VERSION ""

NS_ :

BS_:

BU_: MPAD CVADAS ADCAM ORC EVCU2 EPS ECM CVPAM CADM BSM2 BSM

BO_ 299 ADAS_FD_INFO3: 32 ADCAM
 SG_ ACC_Axle_Torque : 7|16@0+ (2,-65534) [-65534|65536] "Nm"  EVCU2,BSM
 SG_ ACC_Axle_Torque_Enabled : 180|1@0+ (1,0) [0|1] "" BSM
 SG_ MessageCounter_ADAS_FD_INFO3 : 179|4@0+ (1,0) [0|15] "-"  MPAD,BSM
 SG_ CRC_ADAS_FD_INFO3 : 191|8@0+ (1,0) [0|255] "-"  MPAD,BSM
 SG_ ACC_TORSts : 22|1@0+ (1,0) [0|1] "" ADCAM

BO_ 263 PT_SYSTEM_FD_1: 64 EVCU2
 SG_ PowertrainPrplsnActv_PT : 146|1@0+ (1,0) [0|1] "" CVADAS,ADCAM,MPAD,CADM,BSM,EPS
 SG_ GearEngagedForDisplay_PT : 12|5@0+ (1,0) [0|31] "" CVADAS,ADCAM,EPS
 SG_ GearEngaged_PT : 132|4@0+ (1,0) [0|15] "" ADCAM,BSM2,BSM,EPS
 SG_ DriveReady_PT : 166|1@0+ (1,0) [0|1] "" BSM,EPS
 SG_ TargetGear_PT : 55|4@0+ (1,0) [0|15] "" EPS
 SG_ SpeedLimitSts_PT : 140|3@0+ (1,0) [0|7] "" Vector__XXX
 SG_ ShiftLeverPosition_PT : 51|4@0+ (1,0) [0|15] "" CVADAS,ADCAM,CVPAM,BSM,EPS
 SG_ PdlPosActual_PT : 39|8@0+ (0.4,0) [0|102] "%"  CVADAS,ADCAM,MPAD,BSM2,CVPAM,CADM,BSM
 SG_ MessageCounter_PT_SYSTEM_FD_1 : 435|4@0+ (1,0) [0|15] "-"  CVADAS,ADCAM,MPAD,CADM,BSM,EPS,ECM
 SG_ ISASts_PT : 149|1@0+ (1,0) [0|1] "" Vector__XXX
 SG_ GasPedalPositionFailSts_PT : 145|1@0+ (1,0) [0|1] "" ADCAM,MPAD,CADM,BSM
 SG_ GasPedalPosition_PT : 31|8@0+ (0.392,0) [0|99.96] "%"  MPAD,BSM
 SG_ CRC_PT_SYSTEM_FD_1 : 447|8@0+ (1,0) [0|255] "-"  CVADAS,ADCAM,MPAD,CADM,BSM,EPS,ECM
 SG_ RawPVS2_PT : 303|8@0+ (0.019607843,0) [0|4.999999965] "V"  Vector__XXX
 SG_ RawPVS1_PT : 295|8@0+ (0.019607843,0) [0|4.999999965] "V"  Vector__XXX
 SG_ EVCU2_THA_Resp : 220|2@0+ (1,0) [0|3] "" CVADAS
 SG_ EVCU2_TRSC_Resp : 414|2@0+ (1,0) [0|3] "" CVADAS
 SG_ Propulsion_ADAS_Inhibit : 231|1@0+ (1,0) [0|1] "" CVADAS,BSM

BO_ 1580 HYBRID_POWERTRAIN6: 32 EVCU2
 SG_ Motor2_RPM : 23|16@0+ (1,-32768) [-32768|32767] "RPM"  ORC
 SG_ Motor1_RPM : 7|16@0+ (1,-32768) [-32768|32767] "RPM"  ORC

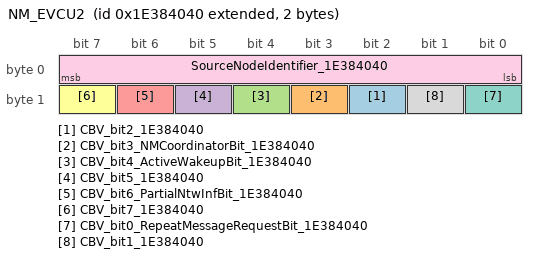
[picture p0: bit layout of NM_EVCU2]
BO_ 2654486592 NM_EVCU2: 2 EVCU2
 SG_ CBV_bit2_1E384040 : 10|1@0+ (1,0) [0|1] "" CVADAS,ADCAM,MPAD,BSM2,CVPAM,CADM,BSM,ORC,EPS,ECM
 SG_ CBV_bit3_NMCoordinatorBit_1E384040 : 11|1@0+ (1,0) [0|1] "" CVADAS,ADCAM,MPAD,BSM2,CVPAM,CADM,BSM,ORC,EPS,ECM
 SG_ CBV_bit4_ActiveWakeupBit_1E384040 : 12|1@0+ (1,0) [0|1] "" CVADAS,ADCAM,MPAD,BSM2,CVPAM,CADM,BSM,ORC,EPS,ECM
 SG_ CBV_bit5_1E384040 : 13|1@0+ (1,0) [0|1] "" CVADAS,ADCAM,MPAD,BSM2,CVPAM,CADM,BSM,ORC,EPS,ECM
 SG_ CBV_bit6_PartialNtwInfBit_1E384040 : 14|1@0+ (1,0) [0|1] "" CVADAS,ADCAM,MPAD,BSM2,CVPAM,CADM,BSM,ORC,EPS,ECM
 SG_ CBV_bit7_1E384040 : 15|1@0+ (1,0) [0|1] "" CVADAS,ADCAM,MPAD,BSM2,CVPAM,CADM,BSM,ORC,EPS,ECM
 SG_ CBV_bit0_RepeatMessageRequestBit_1E384040 : 8|1@0+ (1,0) [0|1] "" CVADAS,ADCAM,MPAD,BSM2,CVPAM,CADM,BSM,ORC,EPS,ECM
 SG_ CBV_bit1_1E384040 : 9|1@0+ (1,0) [0|1] "" CVADAS,ADCAM,MPAD,BSM2,CVPAM,CADM,BSM,ORC,EPS,ECM
 SG_ SourceNodeIdentifier_1E384040 : 7|8@0+ (1,0) [0|255] "-"  CVADAS,ADCAM,MPAD,BSM2,CVPAM,CADM,BSM,ORC,EPS,ECM

BO_ 616 ADAS_FD_HMI_VIP: 32 ADCAM
 SG_ Set_Speed_MPH_VIP : 15|8@0+ (1,0) [0|255] "mph"  MPAD
 SG_ Set_Speed_KPH_VIP : 7|8@0+ (1,0) [0|255] "kph"  MPAD
 SG_ LKA_LEDControlSts_VIP : 57|2@0+ (1,0) [0|3] "No_Unit"  MPAD
 SG_ RR_Chime_RqSts_VIP : 99|1@0+ (1,0) [0|1] "No_Unit"  MPAD
 SG_ PEB_Setting_Avail_VIP : 78|1@0+ (1,0) [0|1] "No_Unit"  MPAD
 SG_ LR_Chime_RqSts_VIP : 100|1@0+ (1,0) [0|1] "No_Unit"  MPAD
 SG_ LKA_FailSts_VIP : 84|1@0+ (1,0) [0|1] "No_Unit"  MPAD
 SG_ LKA_Blind_VIP : 86|1@0+ (1,0) [0|1] "No_Unit"  MPAD
 SG_ ICA_Blind_VIP : 55|1@0+ (1,0) [0|1] "No_Unit"  MPAD
 SG_ FCW_Setting_Avail_VIP : 77|1@0+ (1,0) [0|1] "No_Unit"  MPAD
 SG_ DDD_FailSts_VIP : 96|1@0+ (1,0) [0|1] "No_Unit"  MPAD
 SG_ DDD_DispPopupSts_VIP : 39|2@0+ (1,0) [0|3] "No_Unit"  MPAD
 SG_ BSS_TrailerSts_VIP : 175|3@0+ (1,0) [0|7] "No_Unit"  MPAD
 SG_ BSS_SRV_RQSts_VIP : 88|1@0+ (1,0) [0|1] "No_Unit"  MPAD
 SG_ BSS_DispPopoupSts_VIP : 132|3@0+ (1,0) [0|7] "No_Unit"  MPAD
 SG_ BSS_CFG_STATSts_VIP : 103|2@0+ (1,0) [0|3] "No_Unit"  MPAD
 SG_ BSS_Blind_RQSts_VIP : 101|1@0+ (1,0) [0|1] "No_Unit"  MPAD
 SG_ BlindSpotRightWarn_VIP : 171|2@0+ (1,0) [0|3] "No_Unit"  MPAD
 SG_ BlindSpotLeftWarn_VIP : 105|2@0+ (1,0) [0|3] "No_unit"  MPAD
 SG_ AEB_Limited_VIP : 72|1@0+ (1,0) [0|1] "No_Unit"  MPAD
 SG_ AEB_Limit_Fail_VIP : 74|1@0+ (1,0) [0|1] "No_Unit"  MPAD
 SG_ AEB_FailSts_VIP : 83|1@0+ (1,0) [0|1] "No_Unit"  MPAD
 SG_ AEB_DispPopupSts_VIP : 37|6@0+ (1,0) [0|63] "No_Unit"  MPAD
 SG_ AEB_Blind_VIP : 76|1@0+ (1,0) [0|1] "No_Unit"  MPAD
 SG_ LKA_Status_VIP : 23|1@0+ (1,0) [0|1] "No_Unit"  MPAD
 SG_ Lane_DispPopupSts_VIP : 127|8@0+ (1,0) [0|255] "No_Unit"  MPAD
 SG_ Lane_DisplaySts_Right_LKA_VIP : 60|3@0+ (1,0) [0|7] "No_Unit"  MPAD
 SG_ Lane_DisplaySts_Left_VIP : 71|3@0+ (1,0) [0|7] "No_Unit"  MPAD
 SG_ DisplaySts_Veh_LKA_VIP : 63|3@0+ (1,0) [0|7] "No_Unit"  MPAD
 SG_ MessageCounter_ADAS_FD_HMI_VIP : 179|4@0+ (1,0) [0|15] "No_Unit"  MPAD
 SG_ CRC_ADAS_FD_HMI_VIP : 191|8@0+ (1,0) [0|255] "No_Unit"  MPAD
 SG_ DM_Camera_Block_VIP : 112|1@0+ (1,0) [0|1] "-"  MPAD
 SG_ RRCC_DispPopupSts_VIP : 149|6@0+ (1,0) [0|63] "No_Unit"  MPAD
 SG_ ACC_Set_Speed_Strike_VIP : 92|1@0+ (1,0) [0|1] "No_Unit"  MPAD

BO_ 213 VIP_INFO_FD: 32 MPAD
 SG_ ACCFSafe_D5 : 7|8@0+ (1,0) [0|255] "No_Unit"  ADCAM
 SG_ AEB_Type_Brk_D5 : 11|4@0+ (1,0) [0|15] "No_Unit"  ADCAM
 SG_ DASEngReqPos_D5 : 20|1@0+ (1,0) [0|1] "No_Unit"  ADCAM
 SG_ LKA_LAT_CTRL_ResponseSts_D5 : 13|2@0+ (1,0) [0|3] "No_Unit"  ADCAM
 SG_ RRCC_Cancel_Req_D5 : 15|2@0+ (1,0) [0|3] "No_Unit"  ADCAM
 SG_ MessageCounter_VIP_INFO_FD : 179|4@0+ (1,0) [0|15] "No_Unit"  ADCAM
 SG_ CRC_VIP_INFO_FD : 191|8@0+ (1,0) [0|255] "No_Unit"  ADCAM

BO_ 97 GT_MASTER_FD: 16 MPAD
 SG_ SyncTime : 39|32@0+ (1,0) [0|0] "" CVADAS,BSM2,BSM,ORC
 SG_ OfsTimeSec : 71|32@0+ (1,0) [0|0] "sec"  CVADAS,BSM2,BSM,ORC
 SG_ OfsTimeNSec : 103|32@0+ (1,0) [0|0] "" CVADAS,BSM2,BSM,ORC
 SG_ GTS_Type : 7|8@0+ (1,0) [0|255] "" CVADAS,BSM2,BSM,ORC
 SG_ GTS_SC : 19|4@0+ (1,0) [0|15] "" CVADAS,BSM2,BSM,ORC
 SG_ GTS_D : 23|4@0+ (1,0) [0|16] "" CVADAS,BSM2,BSM,ORC
 SG_ GTS_CRC : 15|8@0+ (1,0) [0|255] "" CVADAS,BSM2,BSM,ORC
 SG_ GTS_Byte3 : 31|8@0+ (1,0) [0|255] "" CVADAS,BSM2,BSM,ORC

BO_ 210 ADAS_FD_INFO3_VIP: 32 ADCAM
 SG_ ACC_Axle_Torque_VIP : 7|16@0+ (2,-65534) [-65534|65536] "Nm"  MPAD

BO_ 209 ADAS_FD_INFO_VIP: 32 ADCAM
 SG_ TorqueOverlaySteeringReq_VIP : 130|11@0+ (0.0048828125,-5) [-5|4.9951171875] "No_Unit"  MPAD
 SG_ SteeringVibration_Type_VIP : 67|4@0+ (1,0) [0|15] "No_Unit"  MPAD
 SG_ SteeringVibration_Rq_VIP : 135|1@0+ (1,0) [0|1] "No_Unit"  MPAD
 SG_ Prefill_Req_VIP : 91|1@0+ (1,0) [0|1] "No_Unit"  MPAD
 SG_ PEB_SystemSts_VIP : 90|1@0+ (1,0) [0|1] "No_Unit"  MPAD
 SG_ Object_Dist_VIP : 127|8@0+ (1,0) [0|255] "m"  MPAD
 SG_ LKA_LAT_CTRL_RequestSts_VIP : 108|2@0+ (1,0) [0|3] "No_Unit"  MPAD
 SG_ LC_Jerk_VIP : 104|1@0+ (1,0) [0|1] "No_Unit"  MPAD
 SG_ Intervention_VIP : 163|12@0+ (0.01,-16) [-16|24.95] "m/s2"  MPAD
 SG_ GrMax_Rq_ACC_VIP : 150|4@0+ (1,0) [0|15] "No_Unit"  MPAD
 SG_ DDD_SystemSts_VIP : 103|1@0+ (1,0) [0|1] "No_Unit"  MPAD
 SG_ DDD_Setting_Avail_VIP : 102|1@0+ (1,0) [0|1] "No_Unit"  MPAD
 SG_ CIPV_Fused_VIP : 101|1@0+ (1,0) [0|1] "No_Unit"  MPAD
 SG_ Brake_Jerk_Req_VIP : 100|1@0+ (1,0) [0|1] "No_Unit"  MPAD
 SG_ AEB_Type_VIP : 167|4@0+ (1,0) [0|15] "No_Unit"  MPAD
 SG_ AEB_Systemsts_VIP : 99|2@0+ (1,0) [0|3] "No_Unit"  MPAD
 SG_ AEB_Sensitivity_Setting_VIP : 1|2@0+ (1,0) [0|3] "No_Unit"  MPAD
 SG_ ACC_Systemsts_VIP : 183|4@0+ (1,0) [0|15] "No_Unit"  MPAD
 SG_ ACC_Engine_Torque_Enabled_VIP : 111|1@0+ (1,0) [0|1] "No_Unit"  MPAD
 SG_ ACC_DsrSpeedKPH_VIP : 119|8@0+ (1,0) [0|255] "km/h"  MPAD
 SG_ MessageCounter_ADAS_FD_INFO_VIP : 179|4@0+ (1,0) [0|15] "No_Unit"  MPAD
 SG_ CRC_ADAS_FD_INFO_VIP : 191|8@0+ (1,0) [0|255] "No_Unit"  MPAD

BO_ 734 ADAS_FD_LANES_2: 64 CVADAS
 SG_ Segment_8_Y2 : 369|10@0+ (0.01,-5) [-5|5.23] "m"  MPAD,CADM
 SG_ Segment_8_Y1 : 201|10@0+ (0.01,-5) [-5|5.23] "m"  MPAD,CADM
 SG_ Segment_8_X2 : 290|11@0+ (0.03,-21) [-21|40.41] "m"  MPAD,CADM
 SG_ Segment_8_X1 : 122|11@0+ (0.03,-21) [-21|40.41] "m"  MPAD,CADM
 SG_ Segment_8_ID : 43|4@0+ (1,0) [0|15] "" MPAD,CADM
 SG_ Segment_8_Confidence : 411|4@0+ (0.1,0) [0|1.5] "" MPAD,CADM
 SG_ Segment_7_Y2 : 363|10@0+ (0.01,-5) [-5|5.23] "m"  MPAD,CADM
 SG_ Segment_7_Y1 : 195|10@0+ (0.01,-5) [-5|5.23] "m"  MPAD,CADM
 SG_ Segment_7_X2 : 285|11@0+ (0.03,-21) [-21|40.41] "m"  MPAD,CADM
 SG_ Segment_7_X1 : 117|11@0+ (0.03,-21) [-21|40.41] "m"  MPAD,CADM
 SG_ Segment_7_ID : 47|4@0+ (1,0) [0|15] "" MPAD,CADM
 SG_ Segment_7_Confidence : 415|4@0+ (0.1,0) [0|1.5] "" MPAD,CADM
 SG_ Segment_6_Y2 : 357|10@0+ (0.01,-5) [-5|5.23] "m"  MPAD,CADM
 SG_ Segment_6_Y1 : 189|10@0+ (0.01,-5) [-5|5.23] "m"  MPAD,CADM
 SG_ Segment_6_X2 : 264|11@0+ (0.03,-21) [-21|40.41] "m"  MPAD,CADM
 SG_ Segment_6_X1 : 96|11@0+ (0.03,-21) [-21|40.41] "m"  MPAD,CADM
 SG_ Segment_6_ID : 35|4@0+ (1,0) [0|15] "" MPAD,CADM
 SG_ Segment_6_Confidence : 403|4@0+ (0.1,0) [0|1.5] "" MPAD,CADM
 SG_ Segment_5_Y2 : 351|10@0+ (0.01,-5) [-5|5.23] "m"  MPAD,CADM
 SG_ Segment_5_Y1 : 183|10@0+ (0.01,-5) [-5|5.23] "m"  MPAD,CADM
 SG_ Segment_5_X2 : 259|11@0+ (0.03,-21) [-21|40.41] "m"  MPAD,CADM
 SG_ Segment_5_X1 : 91|11@0+ (0.03,-21) [-21|40.41] "m"  MPAD,CADM
 SG_ Segment_5_ID : 39|4@0+ (1,0) [0|15] "" MPAD,CADM
 SG_ Segment_5_Confidence : 407|4@0+ (0.1,0) [0|1.5] "" MPAD,CADM
 SG_ Segment_4_Y2 : 329|10@0+ (0.01,-5) [-5|5.23] "m"  MPAD,CADM
 SG_ Segment_4_Y1 : 161|10@0+ (0.01,-5) [-5|5.23] "m"  MPAD,CADM
 SG_ Segment_4_X2 : 254|11@0+ (0.03,-21) [-21|40.41] "m"  MPAD,CADM
 SG_ Segment_4_X1 : 86|11@0+ (0.03,-21) [-21|40.41] "m"  MPAD,CADM
 SG_ Segment_4_ID : 27|4@0+ (1,0) [0|15] "" MPAD,CADM
 SG_ Segment_4_Confidence : 395|4@0+ (0.1,0) [0|1.5] "" MPAD,CADM
 SG_ Segment_3_Y2 : 323|10@0+ (0.01,-5) [-5|5.23] "m"  MPAD,CADM
 SG_ Segment_3_Y1 : 155|10@0+ (0.01,-5) [-5|5.23] "m"  MPAD,CADM
 SG_ Segment_3_X2 : 233|11@0+ (0.03,-21) [-21|40.41] "m"  MPAD,CADM
 SG_ Segment_3_X1 : 65|11@0+ (0.03,-21) [-21|40.41] "m"  MPAD,CADM
 SG_ Segment_3_ID : 31|4@0+ (1,0) [0|15] "" MPAD,CADM
 SG_ Segment_3_Confidence : 399|4@0+ (0.1,0) [0|1.5] "" MPAD,CADM
 SG_ Segment_2_Y2 : 317|10@0+ (0.01,-5) [-5|5.23] "m"  MPAD,CADM
 SG_ Segment_2_Y1 : 149|10@0+ (0.01,-5) [-5|5.23] "m"  MPAD,CADM
 SG_ Segment_2_X2 : 228|11@0+ (0.03,-21) [-21|40.41] "m"  MPAD,CADM
 SG_ Segment_2_X1 : 60|11@0+ (0.03,-21) [-21|40.41] "m"  MPAD,CADM
 SG_ Segment_2_ID : 19|4@0+ (1,0) [0|15] "" MPAD,CADM
 SG_ Segment_2_Confidence : 387|4@0+ (0.1,0) [0|1.5] "" MPAD,CADM
 SG_ Segment_1_Y2 : 311|10@0+ (0.01,-5) [-5|5.23] "m"  MPAD,CADM
 SG_ Segment_1_Y1 : 143|10@0+ (0.01,-5) [-5|5.23] "m"  MPAD,CADM
 SG_ Segment_1_X2 : 223|11@0+ (0.03,-21) [-21|40.41] "m"  MPAD,CADM
 SG_ Segment_1_X1 : 55|11@0+ (0.03,-21) [-21|40.41] "m"  MPAD,CADM
 SG_ Segment_1_ID : 23|4@0+ (1,0) [0|15] "" MPAD,CADM
 SG_ Segment_1_Confidence : 391|4@0+ (0.1,0) [0|1.5] "" MPAD,CADM
 SG_ MessageCounter_ADAS_FD_LANES_2 : 435|4@0+ (1,0) [0|15] "-"  MPAD,CADM
 SG_ MAC_ADAS_FD_LANES_2 : 471|48@0+ (1,0) [0|0] "-"  MPAD,CADM
 SG_ Frame_Index_Lanes_2 : 7|16@0+ (1,0) [0|65535] "" MPAD,CADM
 SG_ CRC_ADAS_FD_LANES_2 : 447|8@0+ (1,0) [0|255] "-"  MPAD,CADM
 SG_ Cntr_ADAS_FD_LANES_2 : 455|16@0+ (1,0) [0|65535] "-"  MPAD,CADM
 SG_ Reserved_for_functional_safety_2DE : 431|12@0+ (0,0) [0|0] "" MPAD,CADM

BO_ 730 ADAS_FD_LANES_1: 64 CVADAS
 SG_ MessageCounter_ADAS_FD_LANES_1 : 435|4@0+ (1,0) [0|15] "-"  MPAD,CADM
 SG_ MAC_ADAS_FD_LANES_1 : 471|48@0+ (1,0) [0|0] "-"  MPAD,CADM
 SG_ Line_4_Type : 179|4@0+ (1,0) [0|15] "" MPAD,CADM
 SG_ Line_4_Start_Range : 294|7@0+ (0.5,-25) [-25|38.5] "m"  MPAD,CADM
 SG_ Line_4_Offset : 209|10@0+ (0.01,-5) [-5|5.23] "m"  MPAD,CADM
 SG_ Line_4_Heading : 249|10@0+ (0.0009765625,-0.357) [-0.357|0.6420234375] "rad"  MPAD,CADM
 SG_ Line_4_End_Range : 326|7@0+ (0.5,-25) [-25|38.5] "m"  MPAD,CADM
 SG_ Line_4_Curvature_Rate : 143|16@0+ (3.7252902985E-09,-0.000122) [-0.000122|0.0001221368997121975] "" MPAD,CADM
 SG_ Line_4_Curvature : 79|16@0+ (9.77E-07,-0.032) [-0.032|0.032027694999999995] "" MPAD,CADM
 SG_ Line_4_Confidence : 163|4@0+ (0.1,0) [0|1.5] "" MPAD,CADM
 SG_ Line_3_Type : 183|4@0+ (1,0) [0|15] "" MPAD,CADM
 SG_ Line_3_Start_Range : 287|7@0+ (0.5,-25) [-25|38.5] "m"  MPAD,CADM
 SG_ Line_3_Offset : 203|10@0+ (0.01,-5) [-5|5.23] "m"  MPAD,CADM
 SG_ Line_3_Heading : 243|10@0+ (0.0009765625,-0.357) [-0.357|0.6420234375] "rad"  MPAD,CADM
 SG_ Line_3_End_Range : 319|7@0+ (0.5,-25) [-25|38.5] "m"  MPAD,CADM
 SG_ Line_3_Curvature_Rate : 127|16@0+ (3.7252902985E-09,-0.000122) [-0.000122|0.0001221368997121975] "" MPAD,CADM
 SG_ Line_3_Curvature : 63|16@0+ (9.77E-07,-0.032) [-0.032|0.032027694999999995] "" MPAD,CADM
 SG_ Line_3_Confidence : 167|4@0+ (0.1,0) [0|1.5] "" MPAD,CADM
 SG_ Line_2_Type : 171|4@0+ (1,0) [0|15] "" MPAD,CADM
 SG_ Line_2_Start_Range : 278|7@0+ (0.5,-25) [-25|38.5] "m"  MPAD,CADM
 SG_ Line_2_Offset : 197|10@0+ (0.01,-5) [-5|5.23] "m"  MPAD,CADM
 SG_ Line_2_Heading : 237|10@0+ (0.0009765625,-0.357) [-0.357|0.6420234375] "rad"  MPAD,CADM
 SG_ Line_2_End_Range : 310|7@0+ (0.5,-25) [-25|38.5] "m"  MPAD,CADM
 SG_ Line_2_Curvature_Rate : 111|16@0+ (3.7252902985E-09,-0.000122) [-0.000122|0.0001221368997121975] "" MPAD,CADM
 SG_ Line_2_Curvature : 47|16@0+ (9.77E-07,-0.032) [-0.032|0.032027694999999995] "" MPAD,CADM
 SG_ Line_2_Confidence : 155|4@0+ (0.1,0) [0|1.5] "" MPAD,CADM
 SG_ Line_1_Type : 175|4@0+ (1,0) [0|15] "" MPAD,CADM
 SG_ Line_1_Start_Range : 271|7@0+ (0.5,-25) [-25|38.5] "m"  MPAD,CADM
 SG_ Line_1_Offset : 191|10@0+ (0.01,-5) [-5|5.23] "m"  MPAD,CADM
 SG_ Line_1_Heading : 231|10@0+ (0.0009765625,-0.357) [-0.357|0.6420234375] "rad"  MPAD,CADM
 SG_ Line_1_End_Range : 303|7@0+ (0.5,-25) [-25|38.5] "m"  MPAD,CADM
 SG_ Line_1_Curvature_Rate : 95|16@0+ (3.7252902985E-09,-0.000122) [-0.000122|0.0001221368997121975] "" MPAD,CADM
 SG_ Line_1_Curvature : 31|16@0+ (9.77E-07,-0.032) [-0.032|0.032027694999999995] "" MPAD,CADM
 SG_ Line_1_Confidence : 159|4@0+ (0.1,0) [0|1.5] "" MPAD,CADM
 SG_ Health_Lane_Detection : 19|2@0+ (1,0) [0|3] "" MPAD,CADM
 SG_ Health_Front_Object_Detection : 17|2@0+ (1,0) [0|3] "" MPAD,CADM
 SG_ Frame_Index_Lanes_1 : 7|16@0+ (1,0) [0|65535] "" MPAD,CADM
 SG_ FOD_Confidence : 335|2@0+ (1,0) [0|3] "" MPAD,CADM
 SG_ CRC_ADAS_FD_LANES_1 : 447|8@0+ (1,0) [0|255] "-"  MPAD,CADM
 SG_ Cntr_ADAS_FD_LANES_1 : 455|16@0+ (1,0) [0|65535] "-"  MPAD,CADM
 SG_ Camera_Status : 23|4@0+ (1,0) [0|15] "" MPAD,CADM
 SG_ Reserved_for_functional_safety_2DA : 431|12@0+ (0,0) [0|0] "" MPAD,CADM

BO_ 265 BRAKE_FD_TMSMP: 64 BSM
 SG_ StbmTimestampSec_BSM_TMSMP : 191|32@0+ (1,0) [0|4294967295] "sec"  MPAD
 SG_ StbmTimestampNSec_BSM_TMSMP : 223|32@0+ (1,0) [0|4294967295] "nsec"  MPAD
 SG_ StbmSyncState_BSM_TMSMP : 255|8@0+ (1,0) [0|255] "No_Unit"  MPAD
 SG_ RHRWheelSpeed_TMSMP : 68|13@0+ (0.0625,0) [0|511.875] "Km/h"  MPAD
 SG_ RHR_WheelSensorFailSts_TMSMP : 103|1@0+ (1,0) [0|1] "-"  MPAD
 SG_ RHR_Spin_TMSMP : 102|2@0+ (1,0) [0|3] "-"  MPAD
 SG_ RHR_FastPulseCounter_TMSMP : 159|8@0+ (1,0) [0|255] "pulse"  MPAD
 SG_ RHFWheelSpeed_TMSMP : 52|13@0+ (0.0625,0) [0|511.875] "Km/h"  MPAD
 SG_ RHF_WheelSensorFailSts_TMSMP : 182|1@0+ (1,0) [0|1] "-"  MPAD
 SG_ RHF_Spin_TMSMP : 7|2@0+ (1,0) [0|3] "-"  MPAD
 SG_ RHF_FastPulseCounter_TMSMP : 175|8@0+ (1,0) [0|255] "pulse"  MPAD
 SG_ LHRWheelSpeed_TMSMP : 4|13@0+ (0.0625,0) [0|511.875] "Km/h"  MPAD
 SG_ LHR_WheelSensorFailSts_TMSMP : 87|1@0+ (1,0) [0|1] "-"  MPAD
 SG_ LHR_Spin_TMSMP : 86|2@0+ (1,0) [0|3] "-"  MPAD
 SG_ LHR_FastPulseCounter_TMSMP : 151|8@0+ (1,0) [0|255] "pulse"  MPAD
 SG_ LHFWheelSpeed_TMSMP : 20|13@0+ (0.0625,0) [0|511.875] "Km/h"  MPAD
 SG_ LHF_WheelSensorFailSts_TMSMP : 181|1@0+ (1,0) [0|1] "-"  MPAD
 SG_ LHF_Spin_TMSMP : 23|2@0+ (1,0) [0|3] "-"  MPAD
 SG_ LHF_FastPulseCounter_TMSMP : 167|8@0+ (1,0) [0|255] "pulse"  MPAD

BO_TX_BU_ 299 : ADCAM,MPAD,CADM;
CM_ SG_ 299 ACC_Axle_Torque "ACC requested Axle Torque";
CM_ SG_ 263 PowertrainPrplsnActv_PT "Powertrain Propulsion System Status";
CM_ SG_ 263 GearEngagedForDisplay_PT "Transmission Gear Engaged signal for the instrument cluster display";
CM_ SG_ 263 GearEngaged_PT "Current engaged gear";
CM_ SG_ 263 DriveReady_PT "Drive Ready allowed status";
CM_ SG_ 1580 Motor2_RPM "Motor 2 speed";
CM_ SG_ 1580 Motor1_RPM "Motor 1 speed";
CM_ SG_ 263 TargetGear_PT "Intended Gear that the transmission will shift to.";
CM_ SG_ 263 SpeedLimitSts_PT "Speed limiter status";
CM_ SG_ 263 ShiftLeverPosition_PT "Shift Lever Position";
CM_ SG_ 263 PdlPosActual_PT "Actual Pedal Position";
CM_ SG_ 263 MessageCounter_PT_SYSTEM_FD_1 "This signal is a counter used for safety checks strategies. This counter is incremented of 1 (one) unit at each frame transmission.";
CM_ SG_ 263 ISASts_PT "Intelligent Speed Assist status";
CM_ SG_ 263 GasPedalPositionFailSts_PT "Gas Pedal Position Failure Status";
CM_ SG_ 263 GasPedalPosition_PT "Gas Pedal Position in percentage";
CM_ SG_ 263 CRC_PT_SYSTEM_FD_1 "CRC according to SAE J1850 standard at each frame transmission.";
CM_ SG_ 616 Set_Speed_MPH_VIP "Speed shown by IPC, which ACC is controlling in MPH";
CM_ SG_ 616 Set_Speed_KPH_VIP "Speed shown by IPC, which ACC is controlling in KPH";
CM_ SG_ 616 LKA_LEDControlSts_VIP "Lane Keep LED Control Status";
CM_ SG_ 97 GTS_Type "Global Time Sync type of frame";
CM_ SG_ 97 GTS_SC "Sequence Counter";
CM_ SG_ 97 GTS_CRC "Global Time Sync CRC";
CM_ SG_ 210 ACC_Axle_Torque_VIP "ACC requested Axle Torque";
CM_ SG_ 299 ACC_Axle_Torque_Enabled "An enable bit that axle torque commands should be followed";
CM_ SG_ 209 TorqueOverlaySteeringReq_VIP "TorqueOverlaySteeringReq";
CM_ SG_ 209 SteeringVibration_Type_VIP "Type of Steering Wheel Vibration Request";
CM_ SG_ 209 SteeringVibration_Rq_VIP "Request to activate Steering Wheel Vibration";
CM_ SG_ 209 Prefill_Req_VIP "Prefill command of Brake System by DASM";
CM_ SG_ 209 PEB_SystemSts_VIP "PEB System Status";
CM_ SG_ 209 Object_Dist_VIP "It indicates the distance to the recognized object";
CM_ SG_ 209 LKA_LAT_CTRL_RequestSts_VIP "LKA_LAT_CTRL_RequestSts";
CM_ SG_ 209 LC_Jerk_VIP "Lane Centering request for brake jerk";
CM_ SG_ 209 Intervention_VIP "Request to set target acceleration/deceleration for any feature";
CM_ SG_ 209 GrMax_Rq_ACC_VIP "Used to request Max Gear from TCM";
CM_ SG_ 209 DDD_SystemSts_VIP "DDD System Status";
CM_ SG_ 209 DDD_Setting_Avail_VIP "DDD_Setting Av Status";
CM_ SG_ 209 CIPV_Fused_VIP "Closest in-path vehicle is fused True = 1";
CM_ SG_ 209 Brake_Jerk_Req_VIP "Request from DASM to perform Jerk Warning";
CM_ SG_ 209 AEB_Type_VIP "AEB Type";
CM_ SG_ 209 AEB_Systemsts_VIP "AEB System Status";
CM_ SG_ 209 AEB_Sensitivity_Setting_VIP "AEB sensitivity status";
CM_ SG_ 209 ACC_Systemsts_VIP "ACC System Status";
CM_ SG_ 209 ACC_Engine_Torque_Enabled_VIP "An enable bit that Torque commands should be followed";
CM_ SG_ 209 ACC_DsrSpeedKPH_VIP "Desired speed in kilometers per hour";
CM_ SG_ 616 RR_Chime_RqSts_VIP "BSM right rear chime on request";
CM_ SG_ 616 PEB_Setting_Avail_VIP "PEB setting availability";
CM_ SG_ 616 LR_Chime_RqSts_VIP "BSM Left rear chime on request";
CM_ SG_ 616 LKA_FailSts_VIP "LKA_FailSts";
CM_ SG_ 616 LKA_Blind_VIP "LKA_Blind";
CM_ SG_ 616 ICA_Blind_VIP "This signal is used to indicate the presence of an occlusion of the ICA feature";
CM_ SG_ 616 FCW_Setting_Avail_VIP "FCW setting availability";
CM_ SG_ 616 DDD_FailSts_VIP "DDD Fail Sts CADM2";
CM_ SG_ 616 DDD_DispPopupSts_VIP "DDD Disp Pop Up";
CM_ SG_ 616 BSS_SRV_RQSts_VIP "BSS service warning request";
CM_ SG_ 616 BSS_CFG_STATSts_VIP "Blind Spot configuration status";
CM_ SG_ 616 BSS_Blind_RQSts_VIP "Sensor blinded request from BSS";
CM_ SG_ 616 BlindSpotRightWarn_VIP "BlindSpotRightWarn";
CM_ SG_ 616 BlindSpotLeftWarn_VIP "BlindSpotLeftWarn";
CM_ SG_ 616 AEB_Limited_VIP "AEB_Limited";
CM_ SG_ 616 AEB_Limit_Fail_VIP "AEB_Limit_Fail";
CM_ SG_ 616 AEB_FailSts_VIP "AEB_FailSts";
CM_ SG_ 616 AEB_DispPopupSts_VIP "AEB Dips Pop Up";
CM_ SG_ 616 AEB_Blind_VIP "AEB_Blind";
CM_ SG_ 299 MessageCounter_ADAS_FD_INFO3 "This signal is a counter used for safety checks strategies. This counter is incremented of 1 (one) unit at each frame transmission.";
CM_ SG_ 299 CRC_ADAS_FD_INFO3 "CRC according to SAE J1850 standard at each frame transmission.";
CM_ SG_ 213 ACCFSafe_D5 "0";
CM_ SG_ 213 AEB_Type_Brk_D5 "AEB type brake signal";
CM_ SG_ 213 DASEngReqPos_D5 "ACC allowed to request engine torque";
CM_ SG_ 213 LKA_LAT_CTRL_ResponseSts_D5 "LKA LAT CTRL Response Sts";
CM_ SG_ 263 RawPVS2_PT "Raw Pedal Voltage - Sensor 2";
CM_ SG_ 263 RawPVS1_PT "Raw Pedal Voltage - Sensor 1";
CM_ SG_ 263 EVCU2_THA_Resp "EVCU2 speed limiting availability response for trailer hitch assist";
CM_ SG_ 734 Segment_8_Y2 "Line segment 8 end point lateral position";
CM_ SG_ 734 Segment_8_Y1 "Line segment 8 start point lateral position";
CM_ SG_ 734 Segment_8_X2 "Line segment 8 end point longitudinal position";
CM_ SG_ 734 Segment_8_X1 "Line segment 8 start point longitudinal position";
CM_ SG_ 734 Segment_8_ID "ID value of line segment 8";
CM_ SG_ 734 Segment_8_Confidence "Line segment 8 confidence";
CM_ SG_ 734 Segment_7_Y2 "Line segment 7 end point lateral position";
CM_ SG_ 734 Segment_7_Y1 "Line segment 7 start point lateral position";
CM_ SG_ 734 Segment_7_X2 "Line segment 7 end point longitudinal position";
CM_ SG_ 734 Segment_7_X1 "Line segment 7 start point longitudinal position";
CM_ SG_ 734 Segment_7_ID "ID value of line segment 7";
CM_ SG_ 734 Segment_7_Confidence "Line segment 7 confidence";
CM_ SG_ 734 Segment_6_Y2 "Line segment 6 end point lateral position";
CM_ SG_ 734 Segment_6_Y1 "Line segment 6 start point lateral position";
CM_ SG_ 734 Segment_6_X2 "Line segment 6 end point longitudinal position";
CM_ SG_ 734 Segment_6_X1 "Line segment 6 start point longitudinal position";
CM_ SG_ 734 Segment_6_ID "ID value of line segment 6";
CM_ SG_ 734 Segment_6_Confidence "Line segment 6 confidence";
CM_ SG_ 734 Segment_5_Y2 "Line segment 5 end point lateral position";
CM_ SG_ 734 Segment_5_Y1 "Line segment 5 start point lateral position";
CM_ SG_ 734 Segment_5_X2 "Line segment 5 end point longitudinal position";
CM_ SG_ 734 Segment_5_X1 "Line segment 5 start point longitudinal position";
CM_ SG_ 734 Segment_5_ID "ID value of line segment 5";
CM_ SG_ 734 Segment_5_Confidence "Line segment 5 confidence";
CM_ SG_ 734 Segment_4_Y2 "Line segment 4 end point lateral position";
CM_ SG_ 734 Segment_4_Y1 "Line segment 4 start point lateral position";
CM_ SG_ 734 Segment_4_X2 "Line segment 4 end point longitudinal position";
CM_ SG_ 734 Segment_4_X1 "Line segment 4 start point longitudinal position";
CM_ SG_ 734 Segment_4_ID "ID value of line segment 4";
CM_ SG_ 734 Segment_4_Confidence "Line segment 4 confidence";
CM_ SG_ 734 Segment_3_Y2 "Line segment 3 end point lateral position";
CM_ SG_ 734 Segment_3_Y1 "Line segment 3 start point lateral position";
CM_ SG_ 734 Segment_3_X2 "Line segment 3 end point longitudinal position";
CM_ SG_ 734 Segment_3_X1 "Line segment 3 start point longitudinal position";
CM_ SG_ 734 Segment_3_ID "ID value of line segment 3";
CM_ SG_ 734 Segment_3_Confidence "Line segment 3 confidence";
CM_ SG_ 734 Segment_2_Y2 "Line segment 2 end point lateral position";
CM_ SG_ 734 Segment_2_Y1 "Line segment 2 start point lateral position";
CM_ SG_ 734 Segment_2_X2 "Line segment 2 end point longitudinal position";
CM_ SG_ 734 Segment_2_X1 "Line segment 2 start point longitudinal position";
CM_ SG_ 734 Segment_2_ID "ID value of line segment 2";
CM_ SG_ 734 Segment_2_Confidence "Line segment 2 confidence";
CM_ SG_ 734 Segment_1_Y2 "Line segment 1 end point lateral position";
CM_ SG_ 734 Segment_1_Y1 "Line segment 1 start point lateral position";
CM_ SG_ 734 Segment_1_X2 "Line segment 1 end point longitudinal position";
CM_ SG_ 734 Segment_1_X1 "Line segment 1 start point longitudinal position";
CM_ SG_ 734 Segment_1_ID "ID value of line segment 1";
CM_ SG_ 734 Segment_1_Confidence "Line segment 1 confidence";
CM_ SG_ 734 MessageCounter_ADAS_FD_LANES_2 "This signal is a counter used for safety checks strategies. This counter is incremented of 1 (one) unit at each frame transmission.";
CM_ SG_ 734 MAC_ADAS_FD_LANES_2 "-";
CM_ SG_ 734 Frame_Index_Lanes_2 "Frame index number for lanes_2 data";
CM_ SG_ 734 CRC_ADAS_FD_LANES_2 "CRC according to SAE J1850 standard at each frame transmission.";
CM_ SG_ 730 MessageCounter_ADAS_FD_LANES_1 "This signal is a counter used for safety checks strategies. This counter is incremented of 1 (one) unit at each frame transmission.";
CM_ SG_ 730 MAC_ADAS_FD_LANES_1 "-";
CM_ SG_ 730 Line_4_Type "Lane marker 4 type";
CM_ SG_ 730 Line_4_Start_Range "Lane marker 4 start range/view range";
CM_ SG_ 730 Line_4_Offset "Lane marker 4 offset distance";
CM_ SG_ 730 Line_4_Heading "Lane marker 4 heading angle (1st order)";
CM_ SG_ 730 Line_4_End_Range "Lane marker 4 end range/view range";
CM_ SG_ 730 Line_4_Curvature_Rate "Lane marker 4 curvature rate (3rd order)";
CM_ SG_ 730 Line_4_Curvature "Lane marker 4 curvature rate (2nd order)";
CM_ SG_ 730 Line_4_Confidence "Lane marker 4 confidence";
CM_ SG_ 730 Line_3_Type "Lane marker 3 type";
CM_ SG_ 730 Line_3_Start_Range "Lane marker 3 start range/view range";
CM_ SG_ 730 Line_3_Offset "Lane marker 3 offset distance";
CM_ SG_ 730 Line_3_Heading "Lane marker 3 heading angle (1st order)";
CM_ SG_ 730 Line_3_End_Range "Lane marker 3 end range/view range";
CM_ SG_ 730 Line_3_Curvature_Rate "Lane marker 3 curvature rate (3rd order)";
CM_ SG_ 730 Line_3_Curvature "Lane marker 3 curvature rate (2nd order)";
CM_ SG_ 730 Line_3_Confidence "Lane marker 3 confidence";
CM_ SG_ 730 Line_2_Type "Lane marker 2 type";
CM_ SG_ 730 Line_2_Start_Range "Lane marker 2 start range/view range";
CM_ SG_ 730 Line_2_Offset "Lane marker 2 offset distance";
CM_ SG_ 730 Line_2_Heading "Lane marker 2 heading angle (1st order)";
CM_ SG_ 730 Line_2_End_Range "Lane marker 2 end range/view range";
CM_ SG_ 730 Line_2_Curvature_Rate "Lane marker 2 curvature rate (3rd order)";
CM_ SG_ 730 Line_2_Curvature "Lane marker 2 curvature rate (2nd order)";
CM_ SG_ 730 Line_2_Confidence "Lane marker 2 confidence";
CM_ SG_ 730 Line_1_Type "Lane marker 1 type";
CM_ SG_ 730 Line_1_Start_Range "Lane marker 1 start range/view range";
CM_ SG_ 730 Line_1_Offset "Lane marker 1 offset distance";
CM_ SG_ 730 Line_1_Heading "Lane marker 1 heading angle (1st order)";
CM_ SG_ 730 Line_1_End_Range "Lane marker 1 end range/view range";
CM_ SG_ 730 Line_1_Curvature_Rate "Lane marker 1 curvature rate (3rd order)";
CM_ SG_ 730 Line_1_Curvature "Lane marker 1 curvature rate (2nd order)";
CM_ SG_ 730 Line_1_Confidence "Lane marker 1 confidence";
CM_ SG_ 730 Health_Lane_Detection "Health of the Lane Marker Detection system";
CM_ SG_ 730 Health_Front_Object_Detection "Health of the Front Object Detection system";
CM_ SG_ 730 Frame_Index_Lanes_1 "Frame index number for lanes_1 data";
CM_ SG_ 730 FOD_Confidence "Front Object Detection Confidence";
CM_ SG_ 730 CRC_ADAS_FD_LANES_1 "CRC according to SAE J1850 standard at each frame transmission.";
CM_ SG_ 730 Camera_Status "List of which cameras are active";
CM_ SG_ 616 LKA_Status_VIP "None";
CM_ SG_ 616 Lane_DispPopupSts_VIP "Lane Management Pop-up Messages.TEXT MSG n corresponds to a raw value of 'n'";
CM_ SG_ 616 Lane_DisplaySts_Right_LKA_VIP "Lane Display Status Right";
CM_ SG_ 616 Lane_DisplaySts_Left_VIP "Lane Display Status Left";
CM_ SG_ 616 DisplaySts_Veh_LKA_VIP "Display Status Veh";
CM_ SG_ 213 MessageCounter_VIP_INFO_FD "This signal is a counter used for safety checks strategies. This counter is incremented of 1 (one) unit at each frame transmission.";
CM_ SG_ 213 CRC_VIP_INFO_FD "CRC according to SAE J1850 standard at each frame transmission.";
CM_ SG_ 265 StbmTimestampSec_BSM_TMSMP "Timestamp in seconds from the BSM Stbm, [0 - 4294967294].";
CM_ SG_ 265 StbmTimestampNSec_BSM_TMSMP "Timestamp in nanoseconds from the BSM Stbm, [0 - 999999999].";
CM_ SG_ 265 StbmSyncState_BSM_TMSMP "Sync status of the BSM Stbm";
CM_ SG_ 265 RHRWheelSpeed_TMSMP "This is the value of the right rear wheel speed";
CM_ SG_ 265 RHR_WheelSensorFailSts_TMSMP "This signal indicates the fail status of RHR sensor";
CM_ SG_ 265 RHR_Spin_TMSMP "This signal indicates the right hand rear wheel status";
CM_ SG_ 265 RHR_FastPulseCounter_TMSMP "This signal is the right rear wheel pulse counter.";
CM_ SG_ 265 RHFWheelSpeed_TMSMP "This is the value of the right front wheel speed";
CM_ SG_ 265 RHF_WheelSensorFailSts_TMSMP "This signal indicates the fail status of RHF sensor";
CM_ SG_ 265 RHF_Spin_TMSMP "This signal indicates the right hand front wheel status";
CM_ SG_ 265 RHF_FastPulseCounter_TMSMP "This signal is the right front wheel pulse counter.";
CM_ SG_ 265 LHRWheelSpeed_TMSMP "This is the value of the left rear wheel speed";
CM_ SG_ 265 LHR_WheelSensorFailSts_TMSMP "This signal indicates the fail status of LHR sensor";
CM_ SG_ 265 LHR_Spin_TMSMP "This signal indicates the left hand rear wheel status";
CM_ SG_ 265 LHR_FastPulseCounter_TMSMP "This signal is the left rear wheel pulse counter.";
CM_ SG_ 265 LHFWheelSpeed_TMSMP "This is the value of the left front wheel speed";
CM_ SG_ 265 LHF_WheelSensorFailSts_TMSMP "This signal indicates the fail status of LHF sensor";
CM_ SG_ 265 LHF_Spin_TMSMP "This signal indicates the left hand front wheel status";
CM_ SG_ 265 LHF_FastPulseCounter_TMSMP "This signal is the left front wheel pulse counter.";
CM_ SG_ 209 MessageCounter_ADAS_FD_INFO_VIP "This signal is a counter used for safety checks strategies. This counter is incremented of 1 (one) unit at each frame transmission.";
CM_ SG_ 209 CRC_ADAS_FD_INFO_VIP "CRC according to SAE J1850 standard at each frame transmission.";
CM_ SG_ 616 MessageCounter_ADAS_FD_HMI_VIP "This signal is a counter used for safety checks strategies. This counter is incremented of 1 (one) unit at each frame transmission.";
CM_ SG_ 616 CRC_ADAS_FD_HMI_VIP "CRC according to SAE J1850 standard at each frame transmission.";
CM_ SG_ 263 EVCU2_TRSC_Resp "EVCU2 break activation response";
CM_ SG_ 263 Propulsion_ADAS_Inhibit "EVCU2's ability to accept external gear shift requests";
CM_ SG_ 616 DM_Camera_Block_VIP "Driver Camera is blocked or obstructed";
CM_ SG_ 299 ACC_TORSts "Take Over Request status";
CM_ SG_ 616 RRCC_DispPopupSts_VIP "RRCC_DispPopupSts";
CM_ SG_ 616 ACC_Set_Speed_Strike_VIP "ACC Set Speed Strike";
BA_DEF_ SG_ "GenSigTimeoutTime_MPAD" INT 0 65535;
BA_DEF_ SG_ "GenSigTimeoutTime_ADCAM" INT 0 65535;
BA_DEF_ SG_ "GenSigTimeoutTime_CVADAS" INT 0 65535;
BA_DEF_ SG_ "GenSigTimeoutTime_VDCM" INT 0 65535;
BA_DEF_ SG_ "GenSigStartValue" INT 0 2147483647;
BA_DEF_ SG_ "GenSigInactiveValue" INT 0 2147483647;
BA_DEF_ SG_ "GenSigSendType" ENUM "NotUsed","OnWrite","OnWriteWithRepetition","OnChange","OnChangeWithRepetition","IfActive","IfActiveWithRepetition","NoSigSendType";
BA_DEF_ SG_ "SystemSignalLongSymbol" STRING ;
BA_DEF_ SG_ "GenSigTimeoutTime_BSM" INT 0 65535;
BA_DEF_ SG_ "GenSigTimeoutTime_BSM2" INT 0 65535;
BA_DEF_ SG_ "GenSigTimeoutTime_CADM" INT 0 65535;
BA_DEF_ SG_ "GenSigTimeoutTime_CVPAM" INT 0 65535;
BA_DEF_ SG_ "GenSigTimeoutTime_ECM" INT 0 65535;
BA_DEF_ SG_ "GenSigTimeoutTime_EPS" INT 0 65535;
BA_DEF_ SG_ "GenSigTimeoutTime_EVCU2" INT 0 65535;
BA_DEF_ SG_ "GenSigTimeoutTime_ORC" INT 0 65535;
BA_DEF_ BO_ "DiagRequest" ENUM "No","Yes";
BA_DEF_ BO_ "Type" ENUM "P","C","PE","COC","PE_Cntrl","E","E_Cntrl","OC","S","BAF","DC","EM","MM","ISO-TP","-";
BA_DEF_ BO_ "DiagResponse" ENUM "No","Yes";
BA_DEF_ BO_ "NmMessage" ENUM "No","Yes";
BA_DEF_ BO_ "GenMsgSendType" ENUM "Cyclic","NotUsed","NotUsed","NotUsed","NotUsed","NotUsed","NotUsed","NotUsed","NoMsgSendType";
BA_DEF_ BO_ "GenMsgNrOfRepetition" INT 0 255;
BA_DEF_ BO_ "GenMsgILSupport" ENUM "No","Yes";
BA_DEF_ BO_ "GenMsgStartDelayTime" INT 0 65535;
BA_DEF_ BO_ "GenMsgCycleTimeFast" INT 0 65535;
BA_DEF_ BO_ "GenMsgCycleTime" INT 0 65535;
BA_DEF_ BO_ "GenMsgDelayTime" INT 0 65535;
BA_DEF_ BO_ "NmAsrMessage" ENUM "No","Yes";
BA_DEF_ BO_ "DiagState" ENUM "No","Yes";
BA_DEF_ BO_ "DiagConnection" HEX 0 65535;
BA_DEF_ BO_ "VFrameFormat" ENUM "StandardCAN","ExtendedCAN","reserved","reserved","reserved","reserved","reserved","reserved","reserved","reserved","reserved","reserved","reserved","reserved","StandardCAN_FD","ExtendedCAN_FD";
BA_DEF_ BO_ "CANFD_BRS" ENUM "0","1";
BA_DEF_DEF_ "GenSigTimeoutTime_MPAD" 2500;
BA_DEF_DEF_ "GenSigTimeoutTime_ADCAM" 2500;
BA_DEF_DEF_ "GenSigTimeoutTime_CVADAS" 2500;
BA_DEF_DEF_ "GenSigTimeoutTime_VDCM" 2500;
BA_DEF_DEF_ "GenSigStartValue" 0;
BA_DEF_DEF_ "GenSigInactiveValue" 0;
BA_DEF_DEF_ "GenSigSendType" "NoSigSendType";
BA_DEF_DEF_ "SystemSignalLongSymbol" "";
BA_DEF_DEF_ "GenSigTimeoutTime_BSM" 2500;
BA_DEF_DEF_ "GenSigTimeoutTime_BSM2" 2500;
BA_DEF_DEF_ "GenSigTimeoutTime_CADM" 2500;
BA_DEF_DEF_ "GenSigTimeoutTime_CVPAM" 2500;
BA_DEF_DEF_ "GenSigTimeoutTime_ECM" 2500;
BA_DEF_DEF_ "GenSigTimeoutTime_EPS" 2500;
BA_DEF_DEF_ "GenSigTimeoutTime_EVCU2" 2500;
BA_DEF_DEF_ "GenSigTimeoutTime_ORC" 2500;
BA_DEF_DEF_ "DiagRequest" "No";
BA_DEF_DEF_ "Type" "-";
BA_DEF_DEF_ "DiagResponse" "No";
BA_DEF_DEF_ "NmMessage" "No";
BA_DEF_DEF_ "GenMsgSendType" "NoMsgSendType";
BA_DEF_DEF_ "GenMsgNrOfRepetition" 0;
BA_DEF_DEF_ "GenMsgILSupport" "No";
BA_DEF_DEF_ "GenMsgStartDelayTime" 0;
BA_DEF_DEF_ "GenMsgCycleTimeFast" 0;
BA_DEF_DEF_ "GenMsgCycleTime" 0;
BA_DEF_DEF_ "GenMsgDelayTime" 0;
BA_DEF_DEF_ "NmAsrMessage" "No";
BA_DEF_DEF_ "DiagState" "No";
BA_DEF_DEF_ "DiagConnection" 0;
BA_DEF_DEF_ "VFrameFormat" "StandardCAN_FD";
BA_DEF_DEF_ "CANFD_BRS" "0";
BA_ "Type" BO_ 299 1;
BA_ "GenMsgSendType" BO_ 299 0;
BA_ "GenMsgILSupport" BO_ 299 1;
BA_ "GenMsgCycleTime" BO_ 299 10;
BA_ "CANFD_BRS" BO_ 299 1;
BA_ "Type" BO_ 263 1;
BA_ "GenMsgSendType" BO_ 263 0;
BA_ "GenMsgILSupport" BO_ 263 1;
BA_ "GenMsgCycleTime" BO_ 263 10;
BA_ "CANFD_BRS" BO_ 263 1;
BA_ "Type" BO_ 1580 1;
BA_ "GenMsgSendType" BO_ 1580 0;
BA_ "GenMsgILSupport" BO_ 1580 1;
BA_ "GenMsgCycleTime" BO_ 1580 500;
BA_ "CANFD_BRS" BO_ 1580 1;
BA_ "Type" BO_ 2654486592 8;
BA_ "NmMessage" BO_ 2654486592 1;
BA_ "NmAsrMessage" BO_ 2654486592 1;
BA_ "VFrameFormat" BO_ 2654486592 15;
BA_ "CANFD_BRS" BO_ 2654486592 1;
BA_ "Type" BO_ 616 3;
BA_ "GenMsgSendType" BO_ 616 0;
BA_ "GenMsgILSupport" BO_ 616 1;
BA_ "GenMsgCycleTime" BO_ 616 100;
BA_ "GenMsgDelayTime" BO_ 616 20;
BA_ "CANFD_BRS" BO_ 616 1;
BA_ "Type" BO_ 213 1;
BA_ "GenMsgSendType" BO_ 213 0;
BA_ "GenMsgILSupport" BO_ 213 1;
BA_ "GenMsgCycleTime" BO_ 213 10;
BA_ "CANFD_BRS" BO_ 213 1;
BA_ "Type" BO_ 97 8;
BA_ "CANFD_BRS" BO_ 97 1;
BA_ "Type" BO_ 210 1;
BA_ "GenMsgSendType" BO_ 210 0;
BA_ "GenMsgILSupport" BO_ 210 1;
BA_ "GenMsgCycleTime" BO_ 210 10;
BA_ "CANFD_BRS" BO_ 210 1;
BA_ "Type" BO_ 209 1;
BA_ "GenMsgSendType" BO_ 209 0;
BA_ "GenMsgILSupport" BO_ 209 1;
BA_ "GenMsgCycleTime" BO_ 209 10;
BA_ "CANFD_BRS" BO_ 209 1;
BA_ "Type" BO_ 734 1;
BA_ "GenMsgSendType" BO_ 734 0;
BA_ "GenMsgILSupport" BO_ 734 1;
BA_ "GenMsgCycleTime" BO_ 734 40;
BA_ "CANFD_BRS" BO_ 734 1;
BA_ "Type" BO_ 730 1;
BA_ "GenMsgSendType" BO_ 730 0;
BA_ "GenMsgILSupport" BO_ 730 1;
BA_ "GenMsgCycleTime" BO_ 730 40;
BA_ "CANFD_BRS" BO_ 730 1;
BA_ "Type" BO_ 265 1;
BA_ "GenMsgSendType" BO_ 265 0;
BA_ "GenMsgILSupport" BO_ 265 1;
BA_ "GenMsgCycleTime" BO_ 265 10;
BA_ "CANFD_BRS" BO_ 265 1;
BA_ "GenSigTimeoutTime_ADCAM" SG_ 734 Reserved_for_functional_safety_2DE 0;
BA_ "GenSigTimeoutTime_CVADAS" SG_ 734 Reserved_for_functional_safety_2DE 0;
BA_ "GenSigTimeoutTime_BSM" SG_ 734 Reserved_for_functional_safety_2DE 0;
BA_ "GenSigTimeoutTime_BSM2" SG_ 734 Reserved_for_functional_safety_2DE 0;
BA_ "GenSigTimeoutTime_ECM" SG_ 734 Reserved_for_functional_safety_2DE 0;
BA_ "GenSigTimeoutTime_EPS" SG_ 734 Reserved_for_functional_safety_2DE 0;
BA_ "GenSigTimeoutTime_EVCU2" SG_ 734 Reserved_for_functional_safety_2DE 0;
BA_ "GenSigTimeoutTime_ORC" SG_ 734 Reserved_for_functional_safety_2DE 0;
BA_ "GenSigTimeoutTime_ADCAM" SG_ 734 Segment_4_Y2 0;
BA_ "GenSigTimeoutTime_CVADAS" SG_ 734 Segment_4_Y2 0;
BA_ "GenSigTimeoutTime_BSM" SG_ 734 Segment_4_Y2 0;
BA_ "GenSigTimeoutTime_BSM2" SG_ 734 Segment_4_Y2 0;
BA_ "GenSigTimeoutTime_ECM" SG_ 734 Segment_4_Y2 0;
BA_ "GenSigTimeoutTime_EPS" SG_ 734 Segment_4_Y2 0;
BA_ "GenSigTimeoutTime_EVCU2" SG_ 734 Segment_4_Y2 0;
BA_ "GenSigTimeoutTime_ORC" SG_ 734 Segment_4_Y2 0;
BA_ "GenSigTimeoutTime_ADCAM" SG_ 734 Segment_4_Y1 0;
BA_ "GenSigTimeoutTime_CVADAS" SG_ 734 Segment_4_Y1 0;
BA_ "GenSigTimeoutTime_BSM" SG_ 734 Segment_4_Y1 0;
BA_ "GenSigTimeoutTime_BSM2" SG_ 734 Segment_4_Y1 0;
BA_ "GenSigTimeoutTime_ECM" SG_ 734 Segment_4_Y1 0;
BA_ "GenSigTimeoutTime_EPS" SG_ 734 Segment_4_Y1 0;
BA_ "GenSigTimeoutTime_EVCU2" SG_ 734 Segment_4_Y1 0;
BA_ "GenSigTimeoutTime_ORC" SG_ 734 Segment_4_Y1 0;
BA_ "GenSigTimeoutTime_ORC" SG_ 734 Segment_4_X2 0;
BA_ "GenSigTimeoutTime_ADCAM" SG_ 734 Segment_3_Y2 0;
BA_ "GenSigTimeoutTime_CVADAS" SG_ 734 Segment_3_Y2 0;
BA_ "GenSigTimeoutTime_BSM" SG_ 734 Segment_3_Y2 0;
BA_ "GenSigTimeoutTime_BSM2" SG_ 734 Segment_3_Y2 0;
BA_ "GenSigTimeoutTime_ECM" SG_ 734 Segment_3_Y2 0;
BA_ "GenSigTimeoutTime_EPS" SG_ 734 Segment_3_Y2 0;
BA_ "GenSigTimeoutTime_EVCU2" SG_ 734 Segment_3_Y2 0;
BA_ "GenSigTimeoutTime_ORC" SG_ 734 Segment_3_Y2 0;
BA_ "GenSigTimeoutTime_ADCAM" SG_ 734 Segment_3_Y1 0;
BA_ "GenSigTimeoutTime_CVADAS" SG_ 734 Segment_3_Y1 0;
BA_ "GenSigTimeoutTime_BSM" SG_ 734 Segment_3_Y1 0;
BA_ "GenSigTimeoutTime_BSM2" SG_ 734 Segment_3_Y1 0;
BA_ "GenSigTimeoutTime_ECM" SG_ 734 Segment_3_Y1 0;
BA_ "GenSigTimeoutTime_EPS" SG_ 734 Segment_3_Y1 0;
BA_ "GenSigTimeoutTime_EVCU2" SG_ 734 Segment_3_Y1 0;
BA_ "GenSigTimeoutTime_ORC" SG_ 734 Segment_3_Y1 0;
BA_ "GenSigTimeoutTime_ADCAM" SG_ 734 Segment_3_X2 0;
BA_ "GenSigTimeoutTime_CVADAS" SG_ 734 Segment_3_X2 0;
BA_ "GenSigTimeoutTime_BSM" SG_ 734 Segment_3_X2 0;
BA_ "GenSigTimeoutTime_BSM2" SG_ 734 Segment_3_X2 0;
BA_ "GenSigTimeoutTime_ECM" SG_ 734 Segment_3_X2 0;
BA_ "GenSigTimeoutTime_EPS" SG_ 734 Segment_3_X2 0;
BA_ "GenSigTimeoutTime_EVCU2" SG_ 734 Segment_3_X2 0;
BA_ "GenSigTimeoutTime_ORC" SG_ 734 Segment_3_X2 0;
BA_ "GenSigTimeoutTime_ADCAM" SG_ 734 Segment_3_X1 0;
BA_ "GenSigTimeoutTime_CVADAS" SG_ 734 Segment_3_X1 0;
BA_ "GenSigTimeoutTime_BSM" SG_ 734 Segment_3_X1 0;
BA_ "GenSigTimeoutTime_BSM2" SG_ 734 Segment_3_X1 0;
BA_ "GenSigTimeoutTime_ECM" SG_ 734 Segment_3_X1 0;
BA_ "GenSigTimeoutTime_EPS" SG_ 734 Segment_3_X1 0;
BA_ "GenSigTimeoutTime_EVCU2" SG_ 734 Segment_3_X1 0;
BA_ "GenSigTimeoutTime_ORC" SG_ 734 Segment_3_X1 0;
BA_ "GenSigTimeoutTime_ADCAM" SG_ 734 Segment_3_ID 0;
BA_ "GenSigTimeoutTime_CVADAS" SG_ 734 Segment_3_ID 0;
BA_ "GenSigTimeoutTime_BSM" SG_ 734 Segment_3_ID 0;
BA_ "GenSigTimeoutTime_BSM2" SG_ 734 Segment_3_ID 0;
BA_ "GenSigTimeoutTime_ECM" SG_ 734 Segment_3_ID 0;
BA_ "GenSigTimeoutTime_EPS" SG_ 734 Segment_3_ID 0;
BA_ "GenSigTimeoutTime_EVCU2" SG_ 734 Segment_3_ID 0;
BA_ "GenSigTimeoutTime_ORC" SG_ 734 Segment_3_ID 0;
BA_ "GenSigTimeoutTime_ADCAM" SG_ 734 Segment_3_Confidence 0;
BA_ "GenSigTimeoutTime_CVADAS" SG_ 734 Segment_3_Confidence 0;
BA_ "GenSigTimeoutTime_BSM" SG_ 734 Segment_3_Confidence 0;
BA_ "GenSigTimeoutTime_BSM2" SG_ 734 Segment_3_Confidence 0;
BA_ "GenSigTimeoutTime_ECM" SG_ 734 Segment_3_Confidence 0;
BA_ "GenSigTimeoutTime_EPS" SG_ 734 Segment_3_Confidence 0;
BA_ "GenSigTimeoutTime_EVCU2" SG_ 734 Segment_3_Confidence 0;
BA_ "GenSigTimeoutTime_ORC" SG_ 734 Segment_3_Confidence 0;
BA_ "GenSigTimeoutTime_ADCAM" SG_ 734 Segment_2_Y2 0;
BA_ "GenSigTimeoutTime_CVADAS" SG_ 734 Segment_2_Y2 0;
BA_ "GenSigTimeoutTime_BSM" SG_ 734 Segment_2_Y2 0;
BA_ "GenSigTimeoutTime_BSM2" SG_ 734 Segment_2_Y2 0;
BA_ "GenSigTimeoutTime_ECM" SG_ 734 Segment_2_Y2 0;
BA_ "GenSigTimeoutTime_EPS" SG_ 734 Segment_2_Y2 0;
BA_ "GenSigTimeoutTime_EVCU2" SG_ 734 Segment_2_Y2 0;
BA_ "GenSigTimeoutTime_ORC" SG_ 734 Segment_2_Y2 0;
BA_ "GenSigTimeoutTime_ADCAM" SG_ 734 Segment_2_Y1 0;
BA_ "GenSigTimeoutTime_CVADAS" SG_ 734 Segment_2_Y1 0;
BA_ "GenSigTimeoutTime_BSM" SG_ 734 Segment_2_Y1 0;
BA_ "GenSigTimeoutTime_BSM2" SG_ 734 Segment_2_Y1 0;
BA_ "GenSigTimeoutTime_ECM" SG_ 734 Segment_2_Y1 0;
BA_ "GenSigTimeoutTime_EPS" SG_ 734 Segment_2_Y1 0;
BA_ "GenSigTimeoutTime_EVCU2" SG_ 734 Segment_2_Y1 0;
BA_ "GenSigTimeoutTime_ORC" SG_ 734 Segment_2_Y1 0;
BA_ "GenSigTimeoutTime_ADCAM" SG_ 734 Segment_2_X2 0;
BA_ "GenSigTimeoutTime_CVADAS" SG_ 734 Segment_2_X2 0;
BA_ "GenSigTimeoutTime_BSM" SG_ 734 Segment_2_X2 0;
BA_ "GenSigTimeoutTime_BSM2" SG_ 734 Segment_2_X2 0;
BA_ "GenSigTimeoutTime_ECM" SG_ 734 Segment_2_X2 0;
BA_ "GenSigTimeoutTime_EPS" SG_ 734 Segment_2_X2 0;
BA_ "GenSigTimeoutTime_EVCU2" SG_ 734 Segment_2_X2 0;
BA_ "GenSigTimeoutTime_ORC" SG_ 734 Segment_2_X2 0;
BA_ "GenSigTimeoutTime_ADCAM" SG_ 734 Segment_2_X1 0;
BA_ "GenSigTimeoutTime_CVADAS" SG_ 734 Segment_2_X1 0;
BA_ "GenSigTimeoutTime_BSM" SG_ 734 Segment_2_X1 0;
BA_ "GenSigTimeoutTime_BSM2" SG_ 734 Segment_2_X1 0;
BA_ "GenSigTimeoutTime_ECM" SG_ 734 Segment_2_X1 0;
BA_ "GenSigTimeoutTime_EPS" SG_ 734 Segment_2_X1 0;
BA_ "GenSigTimeoutTime_EVCU2" SG_ 734 Segment_2_X1 0;
BA_ "GenSigTimeoutTime_ORC" SG_ 734 Segment_2_X1 0;
BA_ "GenSigTimeoutTime_ADCAM" SG_ 734 Segment_2_ID 0;
BA_ "GenSigTimeoutTime_CVADAS" SG_ 734 Segment_2_ID 0;
BA_ "GenSigTimeoutTime_BSM" SG_ 734 Segment_2_ID 0;
BA_ "GenSigTimeoutTime_BSM2" SG_ 734 Segment_2_ID 0;
BA_ "GenSigTimeoutTime_ECM" SG_ 734 Segment_2_ID 0;
BA_ "GenSigTimeoutTime_EPS" SG_ 734 Segment_2_ID 0;
BA_ "GenSigTimeoutTime_EVCU2" SG_ 734 Segment_2_ID 0;
BA_ "GenSigTimeoutTime_ORC" SG_ 734 Segment_2_ID 0;
BA_ "GenSigTimeoutTime_ADCAM" SG_ 734 Segment_2_Confidence 0;
BA_ "GenSigTimeoutTime_CVADAS" SG_ 734 Segment_2_Confidence 0;
BA_ "GenSigTimeoutTime_BSM" SG_ 734 Segment_2_Confidence 0;
BA_ "GenSigTimeoutTime_BSM2" SG_ 734 Segment_2_Confidence 0;
BA_ "GenSigTimeoutTime_ECM" SG_ 734 Segment_2_Confidence 0;
BA_ "GenSigTimeoutTime_EPS" SG_ 734 Segment_2_Confidence 0;
BA_ "GenSigTimeoutTime_EVCU2" SG_ 734 Segment_2_Confidence 0;
BA_ "GenSigTimeoutTime_ORC" SG_ 734 Segment_2_Confidence 0;
BA_ "GenSigTimeoutTime_ADCAM" SG_ 734 Segment_1_Y2 0;
BA_ "GenSigTimeoutTime_CVADAS" SG_ 734 Segment_1_Y2 0;
BA_ "GenSigTimeoutTime_BSM" SG_ 734 Segment_1_Y2 0;
BA_ "GenSigTimeoutTime_BSM2" SG_ 734 Segment_1_Y2 0;
BA_ "GenSigTimeoutTime_ECM" SG_ 734 Segment_1_Y2 0;
BA_ "GenSigTimeoutTime_EPS" SG_ 734 Segment_1_Y2 0;
BA_ "GenSigTimeoutTime_EVCU2" SG_ 734 Segment_1_Y2 0;
BA_ "GenSigTimeoutTime_ORC" SG_ 734 Segment_1_Y2 0;
BA_ "GenSigTimeoutTime_ADCAM" SG_ 734 Segment_1_Y1 0;
BA_ "GenSigTimeoutTime_CVADAS" SG_ 734 Segment_1_Y1 0;
BA_ "GenSigTimeoutTime_BSM" SG_ 734 Segment_1_Y1 0;
BA_ "GenSigTimeoutTime_BSM2" SG_ 734 Segment_1_Y1 0;
BA_ "GenSigTimeoutTime_ECM" SG_ 734 Segment_1_Y1 0;
BA_ "GenSigTimeoutTime_EPS" SG_ 734 Segment_1_Y1 0;
BA_ "GenSigTimeoutTime_EVCU2" SG_ 734 Segment_1_Y1 0;
BA_ "GenSigTimeoutTime_ORC" SG_ 734 Segment_1_Y1 0;
BA_ "GenSigTimeoutTime_ADCAM" SG_ 734 Segment_1_X2 0;
BA_ "GenSigTimeoutTime_CVADAS" SG_ 734 Segment_1_X2 0;
BA_ "GenSigTimeoutTime_BSM" SG_ 734 Segment_1_X2 0;
BA_ "GenSigTimeoutTime_BSM2" SG_ 734 Segment_1_X2 0;
BA_ "GenSigTimeoutTime_ECM" SG_ 734 Segment_1_X2 0;
BA_ "GenSigTimeoutTime_EPS" SG_ 734 Segment_1_X2 0;
BA_ "GenSigTimeoutTime_EVCU2" SG_ 734 Segment_1_X2 0;
BA_ "GenSigTimeoutTime_ORC" SG_ 734 Segment_1_X2 0;
BA_ "GenSigTimeoutTime_ADCAM" SG_ 734 Segment_1_X1 0;
BA_ "GenSigTimeoutTime_CVADAS" SG_ 734 Segment_1_X1 0;
BA_ "GenSigTimeoutTime_BSM" SG_ 734 Segment_1_X1 0;
BA_ "GenSigTimeoutTime_BSM2" SG_ 734 Segment_1_X1 0;
BA_ "GenSigTimeoutTime_ECM" SG_ 734 Segment_1_X1 0;
BA_ "GenSigTimeoutTime_EPS" SG_ 734 Segment_1_X1 0;
BA_ "GenSigTimeoutTime_EVCU2" SG_ 734 Segment_1_X1 0;
BA_ "GenSigTimeoutTime_ORC" SG_ 734 Segment_1_X1 0;
BA_ "GenSigTimeoutTime_ADCAM" SG_ 734 Segment_1_ID 0;
BA_ "GenSigTimeoutTime_CVADAS" SG_ 734 Segment_1_ID 0;
BA_ "GenSigTimeoutTime_BSM" SG_ 734 Segment_1_ID 0;
BA_ "GenSigTimeoutTime_BSM2" SG_ 734 Segment_1_ID 0;
BA_ "GenSigTimeoutTime_ECM" SG_ 734 Segment_1_ID 0;
BA_ "GenSigTimeoutTime_EPS" SG_ 734 Segment_1_ID 0;
BA_ "GenSigTimeoutTime_EVCU2" SG_ 734 Segment_1_ID 0;
BA_ "GenSigTimeoutTime_ORC" SG_ 734 Segment_1_ID 0;
BA_ "GenSigTimeoutTime_ADCAM" SG_ 734 Segment_1_Confidence 0;
BA_ "GenSigTimeoutTime_CVADAS" SG_ 734 Segment_1_Confidence 0;
BA_ "GenSigTimeoutTime_BSM" SG_ 734 Segment_1_Confidence 0;
BA_ "GenSigTimeoutTime_BSM2" SG_ 734 Segment_1_Confidence 0;
BA_ "GenSigTimeoutTime_ECM" SG_ 734 Segment_1_Confidence 0;
BA_ "GenSigTimeoutTime_EPS" SG_ 734 Segment_1_Confidence 0;
BA_ "GenSigTimeoutTime_EVCU2" SG_ 734 Segment_1_Confidence 0;
BA_ "GenSigTimeoutTime_ORC" SG_ 734 Segment_1_Confidence 0;
BA_ "GenSigTimeoutTime_ADCAM" SG_ 734 MessageCounter_ADAS_FD_LANES_2 0;
BA_ "GenSigTimeoutTime_CVADAS" SG_ 734 MessageCounter_ADAS_FD_LANES_2 0;
BA_ "GenSigTimeoutTime_BSM" SG_ 734 MessageCounter_ADAS_FD_LANES_2 0;
BA_ "GenSigTimeoutTime_BSM2" SG_ 734 MessageCounter_ADAS_FD_LANES_2 0;
BA_ "GenSigTimeoutTime_ECM" SG_ 734 MessageCounter_ADAS_FD_LANES_2 0;
BA_ "GenSigTimeoutTime_EPS" SG_ 734 MessageCounter_ADAS_FD_LANES_2 0;
BA_ "GenSigTimeoutTime_EVCU2" SG_ 734 MessageCounter_ADAS_FD_LANES_2 0;
BA_ "GenSigTimeoutTime_ORC" SG_ 734 MessageCounter_ADAS_FD_LANES_2 0;
BA_ "GenSigTimeoutTime_BSM" SG_ 734 MAC_ADAS_FD_LANES_2 0;
BA_ "GenSigTimeoutTime_BSM2" SG_ 734 MAC_ADAS_FD_LANES_2 0;
BA_ "GenSigTimeoutTime_ECM" SG_ 734 MAC_ADAS_FD_LANES_2 0;
BA_ "GenSigTimeoutTime_EPS" SG_ 734 MAC_ADAS_FD_LANES_2 0;
BA_ "GenSigTimeoutTime_EVCU2" SG_ 734 MAC_ADAS_FD_LANES_2 0;
BA_ "GenSigTimeoutTime_ORC" SG_ 734 MAC_ADAS_FD_LANES_2 0;
BA_ "GenSigTimeoutTime_ADCAM" SG_ 734 MAC_ADAS_FD_LANES_2 0;
BA_ "GenSigTimeoutTime_CVADAS" SG_ 734 MAC_ADAS_FD_LANES_2 0;
BA_ "GenSigTimeoutTime_ADCAM" SG_ 734 Frame_Index_Lanes_2 0;
BA_ "GenSigTimeoutTime_CVADAS" SG_ 734 Frame_Index_Lanes_2 0;
BA_ "GenSigTimeoutTime_BSM" SG_ 734 Frame_Index_Lanes_2 0;
BA_ "GenSigTimeoutTime_BSM2" SG_ 734 Frame_Index_Lanes_2 0;
BA_ "GenSigTimeoutTime_ECM" SG_ 734 Frame_Index_Lanes_2 0;
BA_ "GenSigTimeoutTime_EPS" SG_ 734 Frame_Index_Lanes_2 0;
BA_ "GenSigTimeoutTime_EVCU2" SG_ 734 Frame_Index_Lanes_2 0;
BA_ "GenSigTimeoutTime_ORC" SG_ 734 Frame_Index_Lanes_2 0;
BA_ "GenSigTimeoutTime_ADCAM" SG_ 734 CRC_ADAS_FD_LANES_2 0;
BA_ "GenSigTimeoutTime_CVADAS" SG_ 734 CRC_ADAS_FD_LANES_2 0;
BA_ "GenSigTimeoutTime_BSM" SG_ 734 CRC_ADAS_FD_LANES_2 0;
BA_ "GenSigTimeoutTime_BSM2" SG_ 734 CRC_ADAS_FD_LANES_2 0;
BA_ "GenSigTimeoutTime_ECM" SG_ 734 CRC_ADAS_FD_LANES_2 0;
BA_ "GenSigTimeoutTime_EPS" SG_ 734 CRC_ADAS_FD_LANES_2 0;
BA_ "GenSigTimeoutTime_EVCU2" SG_ 734 CRC_ADAS_FD_LANES_2 0;
BA_ "GenSigTimeoutTime_ORC" SG_ 734 CRC_ADAS_FD_LANES_2 0;
BA_ "GenSigTimeoutTime_ADCAM" SG_ 734 Cntr_ADAS_FD_LANES_2 0;
BA_ "GenSigTimeoutTime_CVADAS" SG_ 734 Cntr_ADAS_FD_LANES_2 0;
BA_ "GenSigTimeoutTime_BSM" SG_ 734 Cntr_ADAS_FD_LANES_2 0;
BA_ "GenSigTimeoutTime_BSM2" SG_ 734 Cntr_ADAS_FD_LANES_2 0;
BA_ "GenSigTimeoutTime_ECM" SG_ 734 Cntr_ADAS_FD_LANES_2 0;
BA_ "GenSigTimeoutTime_EPS" SG_ 734 Cntr_ADAS_FD_LANES_2 0;
BA_ "GenSigTimeoutTime_EVCU2" SG_ 734 Cntr_ADAS_FD_LANES_2 0;
BA_ "GenSigTimeoutTime_ORC" SG_ 734 Cntr_ADAS_FD_LANES_2 0;
BA_ "GenSigTimeoutTime_ADCAM" SG_ 734 Segment_8_Confidence 0;
BA_ "GenSigTimeoutTime_CVADAS" SG_ 734 Segment_8_Confidence 0;
BA_ "GenSigTimeoutTime_BSM" SG_ 734 Segment_8_Confidence 0;
BA_ "GenSigTimeoutTime_BSM2" SG_ 734 Segment_8_Confidence 0;
BA_ "GenSigTimeoutTime_ECM" SG_ 734 Segment_8_Confidence 0;
BA_ "GenSigTimeoutTime_EPS" SG_ 734 Segment_8_Confidence 0;
BA_ "GenSigTimeoutTime_ADCAM" SG_ 265 LHRWheelSpeed_TMSMP 0;
BA_ "GenSigTimeoutTime_CVADAS" SG_ 265 LHRWheelSpeed_TMSMP 0;
BA_ "GenSigTimeoutTime_BSM" SG_ 265 LHRWheelSpeed_TMSMP 0;
BA_ "GenSigTimeoutTime_BSM2" SG_ 265 LHRWheelSpeed_TMSMP 0;
BA_ "GenSigTimeoutTime_EPS" SG_ 265 LHRWheelSpeed_TMSMP 0;
BA_ "GenSigTimeoutTime_EVCU2" SG_ 265 LHRWheelSpeed_TMSMP 0;
BA_ "GenSigTimeoutTime_ORC" SG_ 265 LHRWheelSpeed_TMSMP 0;
BA_ "GenSigTimeoutTime_ADCAM" SG_ 265 LHR_WheelSensorFailSts_TMSMP 0;
BA_ "GenSigTimeoutTime_CVADAS" SG_ 265 LHR_WheelSensorFailSts_TMSMP 0;
BA_ "GenSigTimeoutTime_BSM" SG_ 265 LHR_WheelSensorFailSts_TMSMP 0;
BA_ "GenSigTimeoutTime_BSM2" SG_ 265 LHR_WheelSensorFailSts_TMSMP 0;
BA_ "GenSigTimeoutTime_EPS" SG_ 265 LHR_WheelSensorFailSts_TMSMP 0;
BA_ "GenSigTimeoutTime_EVCU2" SG_ 265 LHR_WheelSensorFailSts_TMSMP 0;
BA_ "GenSigTimeoutTime_ORC" SG_ 265 LHR_WheelSensorFailSts_TMSMP 0;
BA_ "GenSigTimeoutTime_ADCAM" SG_ 265 LHR_FastPulseCounter_TMSMP 0;
BA_ "GenSigTimeoutTime_CVADAS" SG_ 265 LHR_FastPulseCounter_TMSMP 0;
BA_ "GenSigTimeoutTime_BSM" SG_ 265 LHR_FastPulseCounter_TMSMP 0;
BA_ "GenSigTimeoutTime_BSM2" SG_ 265 LHR_FastPulseCounter_TMSMP 0;
BA_ "GenSigTimeoutTime_EPS" SG_ 265 LHR_FastPulseCounter_TMSMP 0;
BA_ "GenSigTimeoutTime_EVCU2" SG_ 265 LHR_FastPulseCounter_TMSMP 0;
BA_ "GenSigTimeoutTime_ORC" SG_ 265 LHR_FastPulseCounter_TMSMP 0;
BA_ "GenSigTimeoutTime_ADCAM" SG_ 265 LHR_Spin_TMSMP 0;
BA_ "GenSigTimeoutTime_CVADAS" SG_ 265 LHR_Spin_TMSMP 0;
BA_ "GenSigTimeoutTime_BSM" SG_ 265 LHR_Spin_TMSMP 0;
BA_ "GenSigTimeoutTime_BSM2" SG_ 265 LHR_Spin_TMSMP 0;
BA_ "GenSigTimeoutTime_EPS" SG_ 265 LHR_Spin_TMSMP 0;
BA_ "GenSigTimeoutTime_EVCU2" SG_ 265 LHR_Spin_TMSMP 0;
BA_ "GenSigTimeoutTime_ORC" SG_ 265 LHR_Spin_TMSMP 0;
BA_ "GenSigTimeoutTime_ADCAM" SG_ 265 LHF_FastPulseCounter_TMSMP 0;
BA_ "GenSigTimeoutTime_CVADAS" SG_ 265 LHF_FastPulseCounter_TMSMP 0;
BA_ "GenSigTimeoutTime_BSM" SG_ 265 LHF_FastPulseCounter_TMSMP 0;
BA_ "GenSigTimeoutTime_BSM2" SG_ 265 LHF_FastPulseCounter_TMSMP 0;
BA_ "GenSigTimeoutTime_EPS" SG_ 265 LHF_FastPulseCounter_TMSMP 0;
BA_ "GenSigTimeoutTime_EVCU2" SG_ 265 LHF_FastPulseCounter_TMSMP 0;
BA_ "GenSigTimeoutTime_ORC" SG_ 265 LHF_FastPulseCounter_TMSMP 0;
BA_ "GenSigTimeoutTime_ADCAM" SG_ 265 LHF_Spin_TMSMP 0;
BA_ "GenSigTimeoutTime_CVADAS" SG_ 265 LHF_Spin_TMSMP 0;
BA_ "GenSigTimeoutTime_BSM" SG_ 265 LHF_Spin_TMSMP 0;
BA_ "GenSigTimeoutTime_BSM2" SG_ 265 LHF_Spin_TMSMP 0;
BA_ "GenSigTimeoutTime_EPS" SG_ 265 LHF_Spin_TMSMP 0;
BA_ "GenSigTimeoutTime_EVCU2" SG_ 265 LHF_Spin_TMSMP 0;
BA_ "GenSigTimeoutTime_ORC" SG_ 265 LHF_Spin_TMSMP 0;
BA_ "GenSigTimeoutTime_ADCAM" SG_ 265 LHF_WheelSensorFailSts_TMSMP 0;
BA_ "GenSigTimeoutTime_CVADAS" SG_ 265 LHF_WheelSensorFailSts_TMSMP 0;
BA_ "GenSigTimeoutTime_BSM" SG_ 265 LHF_WheelSensorFailSts_TMSMP 0;
BA_ "GenSigTimeoutTime_BSM2" SG_ 265 LHF_WheelSensorFailSts_TMSMP 0;
BA_ "GenSigTimeoutTime_EPS" SG_ 265 LHF_WheelSensorFailSts_TMSMP 0;
BA_ "GenSigTimeoutTime_EVCU2" SG_ 265 LHF_WheelSensorFailSts_TMSMP 0;
BA_ "GenSigTimeoutTime_ORC" SG_ 265 LHF_WheelSensorFailSts_TMSMP 0;
BA_ "GenSigTimeoutTime_ADCAM" SG_ 265 LHFWheelSpeed_TMSMP 0;
BA_ "GenSigTimeoutTime_CVADAS" SG_ 265 LHFWheelSpeed_TMSMP 0;
BA_ "GenSigTimeoutTime_BSM" SG_ 265 LHFWheelSpeed_TMSMP 0;
BA_ "GenSigTimeoutTime_BSM2" SG_ 265 LHFWheelSpeed_TMSMP 0;
BA_ "GenSigTimeoutTime_EPS" SG_ 265 LHFWheelSpeed_TMSMP 0;
BA_ "GenSigTimeoutTime_EVCU2" SG_ 265 LHFWheelSpeed_TMSMP 0;
BA_ "GenSigTimeoutTime_ORC" SG_ 265 LHFWheelSpeed_TMSMP 0;
BA_ "GenSigTimeoutTime_ADCAM" SG_ 265 RHF_FastPulseCounter_TMSMP 0;
BA_ "GenSigTimeoutTime_CVADAS" SG_ 265 RHF_FastPulseCounter_TMSMP 0;
BA_ "GenSigTimeoutTime_BSM" SG_ 265 RHF_FastPulseCounter_TMSMP 0;
BA_ "GenSigTimeoutTime_BSM2" SG_ 265 RHF_FastPulseCounter_TMSMP 0;
BA_ "GenSigTimeoutTime_EPS" SG_ 265 RHF_FastPulseCounter_TMSMP 0;
BA_ "GenSigTimeoutTime_EVCU2" SG_ 265 RHF_FastPulseCounter_TMSMP 0;
BA_ "GenSigTimeoutTime_ORC" SG_ 265 RHF_FastPulseCounter_TMSMP 0;
BA_ "GenSigTimeoutTime_ADCAM" SG_ 265 RHF_Spin_TMSMP 0;
BA_ "GenSigTimeoutTime_CVADAS" SG_ 265 RHF_Spin_TMSMP 0;
BA_ "GenSigTimeoutTime_BSM" SG_ 265 RHF_Spin_TMSMP 0;
BA_ "GenSigTimeoutTime_BSM2" SG_ 265 RHF_Spin_TMSMP 0;
BA_ "GenSigTimeoutTime_EPS" SG_ 265 RHF_Spin_TMSMP 0;
BA_ "GenSigTimeoutTime_EVCU2" SG_ 265 RHF_Spin_TMSMP 0;
BA_ "GenSigTimeoutTime_ORC" SG_ 265 RHF_Spin_TMSMP 0;
BA_ "GenSigTimeoutTime_ADCAM" SG_ 265 RHF_WheelSensorFailSts_TMSMP 0;
BA_ "GenSigTimeoutTime_CVADAS" SG_ 265 RHF_WheelSensorFailSts_TMSMP 0;
BA_ "GenSigTimeoutTime_BSM" SG_ 265 RHF_WheelSensorFailSts_TMSMP 0;
BA_ "GenSigTimeoutTime_BSM2" SG_ 265 RHF_WheelSensorFailSts_TMSMP 0;
BA_ "GenSigTimeoutTime_EPS" SG_ 265 RHF_WheelSensorFailSts_TMSMP 0;
BA_ "GenSigTimeoutTime_EVCU2" SG_ 265 RHF_WheelSensorFailSts_TMSMP 0;
BA_ "GenSigTimeoutTime_ORC" SG_ 265 RHF_WheelSensorFailSts_TMSMP 0;
BA_ "GenSigTimeoutTime_ADCAM" SG_ 265 RHFWheelSpeed_TMSMP 0;
BA_ "GenSigTimeoutTime_CVADAS" SG_ 265 RHFWheelSpeed_TMSMP 0;
BA_ "GenSigTimeoutTime_BSM" SG_ 265 RHFWheelSpeed_TMSMP 0;
BA_ "GenSigTimeoutTime_BSM2" SG_ 265 RHFWheelSpeed_TMSMP 0;
BA_ "GenSigTimeoutTime_EPS" SG_ 265 RHFWheelSpeed_TMSMP 0;
BA_ "GenSigTimeoutTime_EVCU2" SG_ 265 RHFWheelSpeed_TMSMP 0;
BA_ "GenSigTimeoutTime_ORC" SG_ 265 RHFWheelSpeed_TMSMP 0;
BA_ "GenSigTimeoutTime_ADCAM" SG_ 265 RHR_FastPulseCounter_TMSMP 0;
BA_ "GenSigTimeoutTime_CVADAS" SG_ 265 RHR_FastPulseCounter_TMSMP 0;
BA_ "GenSigTimeoutTime_BSM" SG_ 265 RHR_FastPulseCounter_TMSMP 0;
BA_ "GenSigTimeoutTime_BSM2" SG_ 265 RHR_FastPulseCounter_TMSMP 0;
BA_ "GenSigTimeoutTime_EPS" SG_ 265 RHR_FastPulseCounter_TMSMP 0;
BA_ "GenSigTimeoutTime_EVCU2" SG_ 265 RHR_FastPulseCounter_TMSMP 0;
BA_ "GenSigTimeoutTime_ORC" SG_ 265 RHR_FastPulseCounter_TMSMP 0;
BA_ "GenSigTimeoutTime_ADCAM" SG_ 265 RHR_Spin_TMSMP 0;
BA_ "GenSigTimeoutTime_CVADAS" SG_ 265 RHR_Spin_TMSMP 0;
BA_ "GenSigTimeoutTime_BSM" SG_ 265 RHR_Spin_TMSMP 0;
BA_ "GenSigTimeoutTime_BSM2" SG_ 265 RHR_Spin_TMSMP 0;
BA_ "GenSigTimeoutTime_EPS" SG_ 265 RHR_Spin_TMSMP 0;
BA_ "GenSigTimeoutTime_EVCU2" SG_ 265 RHR_Spin_TMSMP 0;
BA_ "GenSigTimeoutTime_ORC" SG_ 265 RHR_Spin_TMSMP 0;
BA_ "GenSigTimeoutTime_ADCAM" SG_ 265 RHR_WheelSensorFailSts_TMSMP 0;
BA_ "GenSigTimeoutTime_CVADAS" SG_ 265 RHR_WheelSensorFailSts_TMSMP 0;
BA_ "GenSigTimeoutTime_BSM" SG_ 265 RHR_WheelSensorFailSts_TMSMP 0;
BA_ "GenSigTimeoutTime_BSM2" SG_ 265 RHR_WheelSensorFailSts_TMSMP 0;
BA_ "GenSigTimeoutTime_EPS" SG_ 265 RHR_WheelSensorFailSts_TMSMP 0;
BA_ "GenSigTimeoutTime_EVCU2" SG_ 265 RHR_WheelSensorFailSts_TMSMP 0;
BA_ "GenSigTimeoutTime_ORC" SG_ 265 RHR_WheelSensorFailSts_TMSMP 0;
BA_ "GenSigTimeoutTime_ADCAM" SG_ 265 RHRWheelSpeed_TMSMP 0;
BA_ "GenSigTimeoutTime_CVADAS" SG_ 265 RHRWheelSpeed_TMSMP 0;
BA_ "GenSigTimeoutTime_BSM" SG_ 265 RHRWheelSpeed_TMSMP 0;
BA_ "GenSigTimeoutTime_BSM2" SG_ 265 RHRWheelSpeed_TMSMP 0;
BA_ "GenSigTimeoutTime_EPS" SG_ 265 RHRWheelSpeed_TMSMP 0;
BA_ "GenSigTimeoutTime_EVCU2" SG_ 265 RHRWheelSpeed_TMSMP 0;
BA_ "GenSigTimeoutTime_ORC" SG_ 265 RHRWheelSpeed_TMSMP 0;
BA_ "GenSigTimeoutTime_ADCAM" SG_ 265 StbmTimestampSec_BSM_TMSMP 0;
BA_ "GenSigTimeoutTime_CVADAS" SG_ 265 StbmTimestampSec_BSM_TMSMP 0;
BA_ "GenSigTimeoutTime_BSM" SG_ 265 StbmTimestampSec_BSM_TMSMP 0;
BA_ "GenSigTimeoutTime_BSM2" SG_ 265 StbmTimestampSec_BSM_TMSMP 0;
BA_ "GenSigTimeoutTime_EPS" SG_ 265 StbmTimestampSec_BSM_TMSMP 0;
BA_ "GenSigTimeoutTime_EVCU2" SG_ 265 StbmTimestampSec_BSM_TMSMP 0;
BA_ "GenSigTimeoutTime_ORC" SG_ 265 StbmTimestampSec_BSM_TMSMP 0;
BA_ "GenSigTimeoutTime_ADCAM" SG_ 265 StbmSyncState_BSM_TMSMP 0;
BA_ "GenSigTimeoutTime_CVADAS" SG_ 265 StbmSyncState_BSM_TMSMP 0;
BA_ "GenSigStartValue" SG_ 265 StbmSyncState_BSM_TMSMP 255;
BA_ "GenSigTimeoutTime_BSM" SG_ 265 StbmSyncState_BSM_TMSMP 0;
BA_ "GenSigTimeoutTime_BSM2" SG_ 265 StbmSyncState_BSM_TMSMP 0;
BA_ "GenSigTimeoutTime_EPS" SG_ 265 StbmSyncState_BSM_TMSMP 0;
BA_ "GenSigTimeoutTime_EVCU2" SG_ 265 StbmSyncState_BSM_TMSMP 0;
BA_ "GenSigTimeoutTime_ORC" SG_ 265 StbmSyncState_BSM_TMSMP 0;
BA_ "GenSigTimeoutTime_ADCAM" SG_ 265 StbmTimestampNSec_BSM_TMSMP 0;
BA_ "GenSigTimeoutTime_CVADAS" SG_ 265 StbmTimestampNSec_BSM_TMSMP 0;
BA_ "GenSigTimeoutTime_BSM" SG_ 265 StbmTimestampNSec_BSM_TMSMP 0;
BA_ "GenSigTimeoutTime_BSM2" SG_ 265 StbmTimestampNSec_BSM_TMSMP 0;
BA_ "GenSigTimeoutTime_EPS" SG_ 265 StbmTimestampNSec_BSM_TMSMP 0;
BA_ "GenSigTimeoutTime_EVCU2" SG_ 265 StbmTimestampNSec_BSM_TMSMP 0;
BA_ "GenSigTimeoutTime_ORC" SG_ 265 StbmTimestampNSec_BSM_TMSMP 0;
BA_ "GenSigTimeoutTime_BSM" SG_ 730 Line_3_Curvature 0;
BA_ "GenSigTimeoutTime_BSM2" SG_ 730 Line_3_Curvature 0;
BA_ "GenSigTimeoutTime_ECM" SG_ 730 Line_3_Curvature 0;
BA_ "GenSigTimeoutTime_EPS" SG_ 730 Line_3_Curvature 0;
BA_ "GenSigTimeoutTime_EVCU2" SG_ 730 Line_3_Curvature 0;
BA_ "GenSigTimeoutTime_ORC" SG_ 730 Line_3_Curvature 0;
BA_ "GenSigTimeoutTime_ADCAM" SG_ 730 Line_3_Curvature 0;
BA_ "GenSigTimeoutTime_CVADAS" SG_ 730 Line_3_Curvature 0;
BA_ "GenSigTimeoutTime_ADCAM" SG_ 730 Line_3_Curvature_Rate 0;
BA_ "GenSigTimeoutTime_CVADAS" SG_ 730 Line_3_Curvature_Rate 0;
BA_ "GenSigTimeoutTime_BSM" SG_ 730 Line_3_Curvature_Rate 0;
BA_ "GenSigTimeoutTime_BSM2" SG_ 730 Line_3_Curvature_Rate 0;
BA_ "GenSigTimeoutTime_ECM" SG_ 730 Line_3_Curvature_Rate 0;
BA_ "GenSigTimeoutTime_EPS" SG_ 730 Line_3_Curvature_Rate 0;
BA_ "GenSigTimeoutTime_EVCU2" SG_ 730 Line_3_Curvature_Rate 0;
BA_ "GenSigTimeoutTime_ORC" SG_ 730 Line_3_Curvature_Rate 0;
BA_ "GenSigTimeoutTime_ADCAM" SG_ 730 Line_3_End_Range 0;
BA_ "GenSigTimeoutTime_CVADAS" SG_ 730 Line_3_End_Range 0;
BA_ "GenSigTimeoutTime_BSM" SG_ 730 Line_3_End_Range 0;
BA_ "GenSigTimeoutTime_BSM2" SG_ 730 Line_3_End_Range 0;
BA_ "GenSigTimeoutTime_ECM" SG_ 730 Line_3_End_Range 0;
BA_ "GenSigTimeoutTime_EPS" SG_ 730 Line_3_End_Range 0;
BA_ "GenSigTimeoutTime_EVCU2" SG_ 730 Line_3_End_Range 0;
BA_ "GenSigTimeoutTime_ORC" SG_ 730 Line_3_End_Range 0;
BA_ "GenSigTimeoutTime_ADCAM" SG_ 730 Line_3_Heading 0;
BA_ "GenSigTimeoutTime_CVADAS" SG_ 730 Line_3_Heading 0;
BA_ "GenSigTimeoutTime_BSM" SG_ 730 Line_3_Heading 0;
BA_ "GenSigTimeoutTime_BSM2" SG_ 730 Line_3_Heading 0;
BA_ "GenSigTimeoutTime_ECM" SG_ 730 Line_3_Heading 0;
BA_ "GenSigTimeoutTime_EPS" SG_ 730 Line_3_Heading 0;
BA_ "GenSigTimeoutTime_EVCU2" SG_ 730 Line_3_Heading 0;
BA_ "GenSigTimeoutTime_ORC" SG_ 730 Line_3_Heading 0;
BA_ "GenSigTimeoutTime_ADCAM" SG_ 730 Line_3_Offset 0;
BA_ "GenSigTimeoutTime_ADCAM" SG_ 730 Line_3_Type 0;
BA_ "GenSigTimeoutTime_CVADAS" SG_ 730 Line_3_Type 0;
BA_ "GenSigTimeoutTime_BSM" SG_ 730 Line_3_Type 0;
BA_ "GenSigTimeoutTime_BSM2" SG_ 730 Line_3_Type 0;
BA_ "GenSigTimeoutTime_ECM" SG_ 730 Line_3_Type 0;
BA_ "GenSigTimeoutTime_EPS" SG_ 730 Line_3_Type 0;
BA_ "GenSigTimeoutTime_EVCU2" SG_ 730 Line_3_Type 0;
BA_ "GenSigTimeoutTime_ORC" SG_ 730 Line_3_Type 0;
BA_ "GenSigTimeoutTime_ADCAM" SG_ 730 Line_4_Confidence 0;
BA_ "GenSigTimeoutTime_CVADAS" SG_ 730 Line_4_Confidence 0;
BA_ "GenSigTimeoutTime_BSM" SG_ 730 Line_4_Confidence 0;
BA_ "GenSigTimeoutTime_BSM2" SG_ 730 Line_4_Confidence 0;
BA_ "GenSigTimeoutTime_ECM" SG_ 730 Line_4_Confidence 0;
BA_ "GenSigTimeoutTime_EPS" SG_ 730 Line_4_Confidence 0;
BA_ "GenSigTimeoutTime_EVCU2" SG_ 730 Line_4_Confidence 0;
BA_ "GenSigTimeoutTime_ORC" SG_ 730 Line_4_Confidence 0;
BA_ "GenSigTimeoutTime_ADCAM" SG_ 730 Line_4_Curvature 0;
BA_ "GenSigTimeoutTime_CVADAS" SG_ 730 Line_4_Curvature 0;
BA_ "GenSigTimeoutTime_BSM" SG_ 730 Line_4_Curvature 0;
BA_ "GenSigTimeoutTime_BSM2" SG_ 730 Line_4_Curvature 0;
BA_ "GenSigTimeoutTime_ECM" SG_ 730 Line_4_Curvature 0;
BA_ "GenSigTimeoutTime_EPS" SG_ 730 Line_4_Curvature 0;
BA_ "GenSigTimeoutTime_EVCU2" SG_ 730 Line_4_Curvature 0;
BA_ "GenSigTimeoutTime_ORC" SG_ 730 Line_4_Curvature 0;
BA_ "GenSigTimeoutTime_ADCAM" SG_ 730 Line_4_Curvature_Rate 0;
BA_ "GenSigTimeoutTime_CVADAS" SG_ 730 Line_4_Curvature_Rate 0;
BA_ "GenSigTimeoutTime_BSM" SG_ 730 Line_4_Curvature_Rate 0;
BA_ "GenSigTimeoutTime_BSM2" SG_ 730 Line_4_Curvature_Rate 0;
BA_ "GenSigTimeoutTime_ECM" SG_ 730 Line_4_Curvature_Rate 0;
BA_ "GenSigTimeoutTime_EPS" SG_ 730 Line_4_Curvature_Rate 0;
BA_ "GenSigTimeoutTime_EVCU2" SG_ 730 Line_4_Curvature_Rate 0;
BA_ "GenSigTimeoutTime_ORC" SG_ 730 Line_4_Curvature_Rate 0;
BA_ "GenSigTimeoutTime_ADCAM" SG_ 730 Line_4_End_Range 0;
BA_ "GenSigTimeoutTime_CVADAS" SG_ 730 Line_4_End_Range 0;
BA_ "GenSigTimeoutTime_BSM" SG_ 730 Line_4_End_Range 0;
BA_ "GenSigTimeoutTime_BSM2" SG_ 730 Line_4_End_Range 0;
BA_ "GenSigTimeoutTime_ECM" SG_ 730 Line_4_End_Range 0;
BA_ "GenSigTimeoutTime_EPS" SG_ 730 Line_4_End_Range 0;
BA_ "GenSigTimeoutTime_EVCU2" SG_ 730 Line_4_End_Range 0;
BA_ "GenSigTimeoutTime_ORC" SG_ 730 Line_4_End_Range 0;
BA_ "GenSigTimeoutTime_ADCAM" SG_ 730 Line_4_Heading 0;
BA_ "GenSigTimeoutTime_CVADAS" SG_ 730 Line_4_Heading 0;
BA_ "GenSigTimeoutTime_BSM" SG_ 730 Line_4_Heading 0;
BA_ "GenSigTimeoutTime_BSM2" SG_ 730 Line_4_Heading 0;
BA_ "GenSigTimeoutTime_ECM" SG_ 730 Line_4_Heading 0;
BA_ "GenSigTimeoutTime_EPS" SG_ 730 Line_4_Heading 0;
BA_ "GenSigTimeoutTime_EVCU2" SG_ 730 Line_4_Heading 0;
BA_ "GenSigTimeoutTime_ORC" SG_ 730 Line_4_Heading 0;
BA_ "GenSigTimeoutTime_ADCAM" SG_ 730 Line_4_Offset 0;
BA_ "GenSigTimeoutTime_CVADAS" SG_ 730 Line_4_Offset 0;
BA_ "GenSigTimeoutTime_BSM" SG_ 730 Line_4_Offset 0;
BA_ "GenSigTimeoutTime_BSM2" SG_ 730 Line_4_Offset 0;
BA_ "GenSigTimeoutTime_ECM" SG_ 730 Line_4_Offset 0;
BA_ "GenSigTimeoutTime_EPS" SG_ 730 Line_4_Offset 0;
BA_ "GenSigTimeoutTime_EVCU2" SG_ 730 Line_4_Offset 0;
BA_ "GenSigTimeoutTime_ORC" SG_ 730 Line_4_Offset 0;
BA_ "GenSigTimeoutTime_CVADAS" SG_ 730 Line_3_Offset 0;
BA_ "GenSigTimeoutTime_BSM" SG_ 730 Line_3_Offset 0;
BA_ "GenSigTimeoutTime_BSM2" SG_ 730 Line_3_Offset 0;
BA_ "GenSigTimeoutTime_ECM" SG_ 730 Line_3_Offset 0;
BA_ "GenSigTimeoutTime_EPS" SG_ 730 Line_3_Offset 0;
BA_ "GenSigTimeoutTime_EVCU2" SG_ 730 Line_3_Offset 0;
BA_ "GenSigTimeoutTime_ORC" SG_ 730 Line_3_Offset 0;
BA_ "GenSigTimeoutTime_ADCAM" SG_ 730 Line_3_Start_Range 0;
BA_ "GenSigTimeoutTime_CVADAS" SG_ 730 Line_3_Start_Range 0;
BA_ "GenSigTimeoutTime_BSM" SG_ 730 Line_3_Start_Range 0;
BA_ "GenSigTimeoutTime_BSM2" SG_ 730 Line_3_Start_Range 0;
BA_ "GenSigTimeoutTime_ECM" SG_ 730 Line_3_Start_Range 0;
BA_ "GenSigTimeoutTime_EPS" SG_ 730 Line_3_Start_Range 0;
BA_ "GenSigTimeoutTime_EVCU2" SG_ 730 Line_3_Start_Range 0;
BA_ "GenSigTimeoutTime_ORC" SG_ 730 Line_3_Start_Range 0;
BA_ "GenSigTimeoutTime_ADCAM" SG_ 730 Line_2_Type 0;
BA_ "GenSigTimeoutTime_CVADAS" SG_ 730 Line_2_Type 0;
BA_ "GenSigTimeoutTime_BSM" SG_ 730 Line_2_Type 0;
BA_ "GenSigTimeoutTime_BSM2" SG_ 730 Line_2_Type 0;
BA_ "GenSigTimeoutTime_ECM" SG_ 730 Line_2_Type 0;
BA_ "GenSigTimeoutTime_EPS" SG_ 730 Line_2_Type 0;
BA_ "GenSigTimeoutTime_EVCU2" SG_ 730 Line_2_Type 0;
BA_ "GenSigTimeoutTime_ORC" SG_ 730 Line_2_Type 0;
BA_ "GenSigTimeoutTime_ADCAM" SG_ 730 Line_3_Confidence 0;
BA_ "GenSigTimeoutTime_CVADAS" SG_ 730 Line_3_Confidence 0;
BA_ "GenSigTimeoutTime_BSM" SG_ 730 Line_3_Confidence 0;
BA_ "GenSigTimeoutTime_BSM2" SG_ 730 Line_3_Confidence 0;
BA_ "GenSigTimeoutTime_ECM" SG_ 730 Line_3_Confidence 0;
BA_ "GenSigTimeoutTime_EPS" SG_ 730 Line_3_Confidence 0;
BA_ "GenSigTimeoutTime_EVCU2" SG_ 730 Line_3_Confidence 0;
BA_ "GenSigTimeoutTime_ORC" SG_ 730 Line_3_Confidence 0;
BA_ "GenSigTimeoutTime_ADCAM" SG_ 730 Health_Lane_Detection 0;
BA_ "GenSigTimeoutTime_CVADAS" SG_ 730 Health_Lane_Detection 0;
BA_ "GenSigTimeoutTime_BSM" SG_ 730 Health_Lane_Detection 0;
BA_ "GenSigTimeoutTime_BSM2" SG_ 730 Health_Lane_Detection 0;
BA_ "GenSigTimeoutTime_ECM" SG_ 730 Health_Lane_Detection 0;
BA_ "GenSigTimeoutTime_EPS" SG_ 730 Health_Lane_Detection 0;
BA_ "GenSigTimeoutTime_EVCU2" SG_ 730 Health_Lane_Detection 0;
BA_ "GenSigTimeoutTime_ORC" SG_ 730 Health_Lane_Detection 0;
BA_ "GenSigTimeoutTime_ADCAM" SG_ 730 Line_1_Confidence 0;
BA_ "GenSigTimeoutTime_CVADAS" SG_ 730 Line_1_Confidence 0;
BA_ "GenSigTimeoutTime_BSM" SG_ 730 Line_1_Confidence 0;
BA_ "GenSigTimeoutTime_BSM2" SG_ 730 Line_1_Confidence 0;
BA_ "GenSigTimeoutTime_ECM" SG_ 730 Line_1_Confidence 0;
BA_ "GenSigTimeoutTime_EPS" SG_ 730 Line_1_Confidence 0;
BA_ "GenSigTimeoutTime_EVCU2" SG_ 730 Line_1_Confidence 0;
BA_ "GenSigTimeoutTime_ORC" SG_ 730 Line_1_Confidence 0;
BA_ "GenSigTimeoutTime_ADCAM" SG_ 730 Line_1_Curvature 0;
BA_ "GenSigTimeoutTime_CVADAS" SG_ 730 Line_1_Curvature 0;
BA_ "GenSigTimeoutTime_BSM" SG_ 730 Line_1_Curvature 0;
BA_ "GenSigTimeoutTime_BSM2" SG_ 730 Line_1_Curvature 0;
BA_ "GenSigTimeoutTime_ECM" SG_ 730 Line_1_Curvature 0;
BA_ "GenSigTimeoutTime_EPS" SG_ 730 Line_1_Curvature 0;
BA_ "GenSigTimeoutTime_EVCU2" SG_ 730 Line_1_Curvature 0;
BA_ "GenSigTimeoutTime_ORC" SG_ 730 Line_1_Curvature 0;
BA_ "GenSigTimeoutTime_ADCAM" SG_ 730 Line_1_Curvature_Rate 0;
BA_ "GenSigTimeoutTime_CVADAS" SG_ 730 Line_1_Curvature_Rate 0;
BA_ "GenSigTimeoutTime_BSM" SG_ 730 Line_1_Curvature_Rate 0;
BA_ "GenSigTimeoutTime_BSM2" SG_ 730 Line_1_Curvature_Rate 0;
BA_ "GenSigTimeoutTime_ECM" SG_ 730 Line_1_Curvature_Rate 0;
BA_ "GenSigTimeoutTime_EPS" SG_ 730 Line_1_Curvature_Rate 0;
BA_ "GenSigTimeoutTime_EVCU2" SG_ 730 Line_1_Curvature_Rate 0;
BA_ "GenSigTimeoutTime_ORC" SG_ 730 Line_1_Curvature_Rate 0;
BA_ "GenSigTimeoutTime_ADCAM" SG_ 730 Line_1_End_Range 0;
BA_ "GenSigTimeoutTime_CVADAS" SG_ 730 Line_1_End_Range 0;
BA_ "GenSigTimeoutTime_BSM" SG_ 730 Line_1_End_Range 0;
BA_ "GenSigTimeoutTime_BSM2" SG_ 730 Line_1_End_Range 0;
BA_ "GenSigTimeoutTime_ECM" SG_ 730 Line_1_End_Range 0;
BA_ "GenSigTimeoutTime_EPS" SG_ 730 Line_1_End_Range 0;
BA_ "GenSigTimeoutTime_EVCU2" SG_ 730 Line_1_End_Range 0;
BA_ "GenSigTimeoutTime_ORC" SG_ 730 Line_1_End_Range 0;
BA_ "GenSigTimeoutTime_ADCAM" SG_ 730 Line_1_Heading 0;
BA_ "GenSigTimeoutTime_CVADAS" SG_ 730 Line_1_Heading 0;
BA_ "GenSigTimeoutTime_BSM" SG_ 730 Line_1_Heading 0;
BA_ "GenSigTimeoutTime_BSM2" SG_ 730 Line_1_Heading 0;
BA_ "GenSigTimeoutTime_ECM" SG_ 730 Line_1_Heading 0;
BA_ "GenSigTimeoutTime_EPS" SG_ 730 Line_1_Heading 0;
BA_ "GenSigTimeoutTime_EVCU2" SG_ 730 Line_1_Heading 0;
BA_ "GenSigTimeoutTime_ORC" SG_ 730 Line_1_Heading 0;
BA_ "GenSigTimeoutTime_ADCAM" SG_ 730 Line_1_Offset 0;
BA_ "GenSigTimeoutTime_CVADAS" SG_ 730 Line_1_Offset 0;
BA_ "GenSigTimeoutTime_BSM" SG_ 730 Line_1_Offset 0;
BA_ "GenSigTimeoutTime_BSM2" SG_ 730 Line_1_Offset 0;
BA_ "GenSigTimeoutTime_ECM" SG_ 730 Line_1_Offset 0;
BA_ "GenSigTimeoutTime_EPS" SG_ 730 Line_1_Offset 0;
BA_ "GenSigTimeoutTime_EVCU2" SG_ 730 Line_1_Offset 0;
BA_ "GenSigTimeoutTime_ORC" SG_ 730 Line_1_Offset 0;
BA_ "GenSigTimeoutTime_ADCAM" SG_ 730 Line_1_Start_Range 0;
BA_ "GenSigTimeoutTime_CVADAS" SG_ 730 Line_1_Start_Range 0;
BA_ "GenSigTimeoutTime_BSM" SG_ 730 Line_1_Start_Range 0;
BA_ "GenSigTimeoutTime_BSM2" SG_ 730 Line_1_Start_Range 0;
BA_ "GenSigTimeoutTime_ECM" SG_ 730 Line_1_Start_Range 0;
BA_ "GenSigTimeoutTime_EPS" SG_ 730 Line_1_Start_Range 0;
BA_ "GenSigTimeoutTime_EVCU2" SG_ 730 Line_1_Start_Range 0;
BA_ "GenSigTimeoutTime_ORC" SG_ 730 Line_1_Start_Range 0;
BA_ "GenSigTimeoutTime_ADCAM" SG_ 730 Line_1_Type 0;
BA_ "GenSigTimeoutTime_CVADAS" SG_ 730 Line_1_Type 0;
BA_ "GenSigTimeoutTime_BSM" SG_ 730 Line_1_Type 0;
BA_ "GenSigTimeoutTime_BSM2" SG_ 730 Line_1_Type 0;
BA_ "GenSigTimeoutTime_ECM" SG_ 730 Line_1_Type 0;
BA_ "GenSigTimeoutTime_EPS" SG_ 730 Line_1_Type 0;
BA_ "GenSigTimeoutTime_EVCU2" SG_ 730 Line_1_Type 0;
BA_ "GenSigTimeoutTime_ORC" SG_ 730 Line_1_Type 0;
BA_ "GenSigTimeoutTime_ADCAM" SG_ 730 Line_2_Confidence 0;
BA_ "GenSigTimeoutTime_CVADAS" SG_ 730 Line_2_Confidence 0;
BA_ "GenSigTimeoutTime_BSM" SG_ 730 Line_2_Confidence 0;
BA_ "GenSigTimeoutTime_BSM2" SG_ 730 Line_2_Confidence 0;
BA_ "GenSigTimeoutTime_ECM" SG_ 730 Line_2_Confidence 0;
BA_ "GenSigTimeoutTime_EPS" SG_ 730 Line_2_Confidence 0;
BA_ "GenSigTimeoutTime_EVCU2" SG_ 730 Line_2_Confidence 0;
BA_ "GenSigTimeoutTime_ORC" SG_ 730 Line_2_Confidence 0;
BA_ "GenSigTimeoutTime_ADCAM" SG_ 730 Line_2_Curvature 0;
BA_ "GenSigTimeoutTime_CVADAS" SG_ 730 Line_2_Curvature 0;
BA_ "GenSigTimeoutTime_BSM" SG_ 730 Line_2_Curvature 0;
BA_ "GenSigTimeoutTime_BSM2" SG_ 730 Line_2_Curvature 0;
BA_ "GenSigTimeoutTime_ECM" SG_ 730 Line_2_Curvature 0;
BA_ "GenSigTimeoutTime_EPS" SG_ 730 Line_2_Curvature 0;
BA_ "GenSigTimeoutTime_EVCU2" SG_ 730 Line_2_Curvature 0;
BA_ "GenSigTimeoutTime_ORC" SG_ 730 Line_2_Curvature 0;
BA_ "GenSigTimeoutTime_ADCAM" SG_ 730 Line_2_Curvature_Rate 0;
BA_ "GenSigTimeoutTime_CVADAS" SG_ 730 Line_2_Curvature_Rate 0;
BA_ "GenSigTimeoutTime_BSM" SG_ 730 Line_2_Curvature_Rate 0;
BA_ "GenSigTimeoutTime_BSM2" SG_ 730 Line_2_Curvature_Rate 0;
BA_ "GenSigTimeoutTime_ECM" SG_ 730 Line_2_Curvature_Rate 0;
BA_ "GenSigTimeoutTime_EPS" SG_ 730 Line_2_Curvature_Rate 0;
BA_ "GenSigTimeoutTime_EVCU2" SG_ 730 Line_2_Curvature_Rate 0;
BA_ "GenSigTimeoutTime_ORC" SG_ 730 Line_2_Curvature_Rate 0;
BA_ "GenSigTimeoutTime_ADCAM" SG_ 730 Line_2_End_Range 0;
BA_ "GenSigTimeoutTime_CVADAS" SG_ 730 Line_2_End_Range 0;
BA_ "GenSigTimeoutTime_BSM" SG_ 730 Line_2_End_Range 0;
BA_ "GenSigTimeoutTime_BSM2" SG_ 730 Line_2_End_Range 0;
BA_ "GenSigTimeoutTime_ECM" SG_ 730 Line_2_End_Range 0;
BA_ "GenSigTimeoutTime_EPS" SG_ 730 Line_2_End_Range 0;
BA_ "GenSigTimeoutTime_EVCU2" SG_ 730 Line_2_End_Range 0;
BA_ "GenSigTimeoutTime_ORC" SG_ 730 Line_2_End_Range 0;
BA_ "GenSigTimeoutTime_ADCAM" SG_ 730 Line_2_Heading 0;
BA_ "GenSigTimeoutTime_CVADAS" SG_ 730 Line_2_Heading 0;
BA_ "GenSigTimeoutTime_BSM" SG_ 730 Line_2_Heading 0;
BA_ "GenSigTimeoutTime_BSM2" SG_ 730 Line_2_Heading 0;
BA_ "GenSigTimeoutTime_ECM" SG_ 730 Line_2_Heading 0;
BA_ "GenSigTimeoutTime_EPS" SG_ 730 Line_2_Heading 0;
BA_ "GenSigTimeoutTime_EVCU2" SG_ 730 Line_2_Heading 0;
BA_ "GenSigTimeoutTime_ORC" SG_ 730 Line_2_Heading 0;
BA_ "GenSigTimeoutTime_ADCAM" SG_ 730 Line_2_Offset 0;
BA_ "GenSigTimeoutTime_CVADAS" SG_ 730 Line_2_Offset 0;
BA_ "GenSigTimeoutTime_BSM" SG_ 730 Line_2_Offset 0;
BA_ "GenSigTimeoutTime_BSM2" SG_ 730 Line_2_Offset 0;
BA_ "GenSigTimeoutTime_ECM" SG_ 730 Line_2_Offset 0;
BA_ "GenSigTimeoutTime_EPS" SG_ 730 Line_2_Offset 0;
BA_ "GenSigTimeoutTime_EVCU2" SG_ 730 Line_2_Offset 0;
BA_ "GenSigTimeoutTime_ORC" SG_ 730 Line_2_Offset 0;
BA_ "GenSigTimeoutTime_ADCAM" SG_ 730 Line_2_Start_Range 0;
BA_ "GenSigTimeoutTime_CVADAS" SG_ 730 Line_2_Start_Range 0;
BA_ "GenSigTimeoutTime_BSM" SG_ 730 Line_2_Start_Range 0;
BA_ "GenSigTimeoutTime_BSM2" SG_ 730 Line_2_Start_Range 0;
BA_ "GenSigTimeoutTime_ECM" SG_ 730 Line_2_Start_Range 0;
BA_ "GenSigTimeoutTime_EPS" SG_ 730 Line_2_Start_Range 0;
BA_ "GenSigTimeoutTime_EVCU2" SG_ 730 Line_2_Start_Range 0;
BA_ "GenSigTimeoutTime_ORC" SG_ 730 Line_2_Start_Range 0;
BA_ "GenSigTimeoutTime_ADCAM" SG_ 730 Camera_Status 0;
BA_ "GenSigTimeoutTime_CVADAS" SG_ 730 Camera_Status 0;
BA_ "GenSigTimeoutTime_BSM" SG_ 730 Camera_Status 0;
BA_ "GenSigTimeoutTime_BSM2" SG_ 730 Camera_Status 0;
BA_ "GenSigTimeoutTime_ECM" SG_ 730 Camera_Status 0;
BA_ "GenSigTimeoutTime_EPS" SG_ 730 Camera_Status 0;
BA_ "GenSigTimeoutTime_EVCU2" SG_ 730 Camera_Status 0;
BA_ "GenSigTimeoutTime_ORC" SG_ 730 Camera_Status 0;
BA_ "GenSigTimeoutTime_ADCAM" SG_ 730 Cntr_ADAS_FD_LANES_1 0;
BA_ "GenSigTimeoutTime_CVADAS" SG_ 730 Cntr_ADAS_FD_LANES_1 0;
BA_ "GenSigTimeoutTime_BSM" SG_ 730 Cntr_ADAS_FD_LANES_1 0;
BA_ "GenSigTimeoutTime_BSM2" SG_ 730 Cntr_ADAS_FD_LANES_1 0;
BA_ "GenSigTimeoutTime_ECM" SG_ 730 Cntr_ADAS_FD_LANES_1 0;
BA_ "GenSigTimeoutTime_EPS" SG_ 730 Cntr_ADAS_FD_LANES_1 0;
BA_ "GenSigTimeoutTime_EVCU2" SG_ 730 Cntr_ADAS_FD_LANES_1 0;
BA_ "GenSigTimeoutTime_ORC" SG_ 730 Cntr_ADAS_FD_LANES_1 0;
BA_ "GenSigTimeoutTime_ADCAM" SG_ 730 CRC_ADAS_FD_LANES_1 0;
BA_ "GenSigTimeoutTime_CVADAS" SG_ 730 CRC_ADAS_FD_LANES_1 0;
BA_ "GenSigTimeoutTime_BSM" SG_ 730 CRC_ADAS_FD_LANES_1 0;
BA_ "GenSigTimeoutTime_BSM2" SG_ 730 CRC_ADAS_FD_LANES_1 0;
BA_ "GenSigTimeoutTime_ECM" SG_ 730 CRC_ADAS_FD_LANES_1 0;
BA_ "GenSigTimeoutTime_EPS" SG_ 730 CRC_ADAS_FD_LANES_1 0;
BA_ "GenSigTimeoutTime_EVCU2" SG_ 730 CRC_ADAS_FD_LANES_1 0;
BA_ "GenSigTimeoutTime_ORC" SG_ 730 CRC_ADAS_FD_LANES_1 0;
BA_ "GenSigTimeoutTime_BSM" SG_ 730 FOD_Confidence 0;
BA_ "GenSigTimeoutTime_BSM2" SG_ 730 FOD_Confidence 0;
BA_ "GenSigTimeoutTime_ECM" SG_ 730 FOD_Confidence 0;
BA_ "GenSigTimeoutTime_EPS" SG_ 730 FOD_Confidence 0;
BA_ "GenSigTimeoutTime_EVCU2" SG_ 730 FOD_Confidence 0;
BA_ "GenSigTimeoutTime_ORC" SG_ 730 FOD_Confidence 0;
BA_ "GenSigTimeoutTime_ADCAM" SG_ 730 FOD_Confidence 0;
BA_ "GenSigTimeoutTime_CVADAS" SG_ 730 FOD_Confidence 0;
BA_ "GenSigTimeoutTime_ADCAM" SG_ 730 Frame_Index_Lanes_1 0;
BA_ "GenSigTimeoutTime_CVADAS" SG_ 730 Frame_Index_Lanes_1 0;
BA_ "GenSigTimeoutTime_BSM" SG_ 730 Frame_Index_Lanes_1 0;
BA_ "GenSigTimeoutTime_BSM2" SG_ 730 Frame_Index_Lanes_1 0;
BA_ "GenSigTimeoutTime_ECM" SG_ 730 Frame_Index_Lanes_1 0;
BA_ "GenSigTimeoutTime_EPS" SG_ 730 Frame_Index_Lanes_1 0;
BA_ "GenSigTimeoutTime_EVCU2" SG_ 730 Frame_Index_Lanes_1 0;
BA_ "GenSigTimeoutTime_ORC" SG_ 730 Frame_Index_Lanes_1 0;
BA_ "GenSigTimeoutTime_ADCAM" SG_ 730 Health_Front_Object_Detection 0;
BA_ "GenSigTimeoutTime_CVADAS" SG_ 730 Health_Front_Object_Detection 0;
BA_ "GenSigTimeoutTime_BSM" SG_ 730 Health_Front_Object_Detection 0;
BA_ "GenSigTimeoutTime_BSM2" SG_ 730 Health_Front_Object_Detection 0;
BA_ "GenSigTimeoutTime_ECM" SG_ 730 Health_Front_Object_Detection 0;
BA_ "GenSigTimeoutTime_EPS" SG_ 730 Health_Front_Object_Detection 0;
BA_ "GenSigTimeoutTime_EVCU2" SG_ 730 Health_Front_Object_Detection 0;
BA_ "GenSigTimeoutTime_ORC" SG_ 730 Health_Front_Object_Detection 0;
BA_ "GenSigTimeoutTime_ADCAM" SG_ 730 Reserved_for_functional_safety_2DA 0;
BA_ "GenSigTimeoutTime_CVADAS" SG_ 730 Reserved_for_functional_safety_2DA 0;
BA_ "GenSigTimeoutTime_BSM" SG_ 730 Reserved_for_functional_safety_2DA 0;
BA_ "GenSigTimeoutTime_BSM2" SG_ 730 Reserved_for_functional_safety_2DA 0;
BA_ "GenSigTimeoutTime_ECM" SG_ 730 Reserved_for_functional_safety_2DA 0;
BA_ "GenSigTimeoutTime_EPS" SG_ 730 Reserved_for_functional_safety_2DA 0;
BA_ "GenSigTimeoutTime_EVCU2" SG_ 730 Reserved_for_functional_safety_2DA 0;
BA_ "GenSigTimeoutTime_ORC" SG_ 730 Reserved_for_functional_safety_2DA 0;
BA_ "GenSigTimeoutTime_ADCAM" SG_ 730 Line_4_Start_Range 0;
BA_ "GenSigTimeoutTime_CVADAS" SG_ 730 Line_4_Start_Range 0;
BA_ "GenSigTimeoutTime_BSM" SG_ 730 Line_4_Start_Range 0;
BA_ "GenSigTimeoutTime_BSM2" SG_ 730 Line_4_Start_Range 0;
BA_ "GenSigTimeoutTime_ECM" SG_ 730 Line_4_Start_Range 0;
BA_ "GenSigTimeoutTime_EPS" SG_ 730 Line_4_Start_Range 0;
BA_ "GenSigTimeoutTime_EVCU2" SG_ 730 Line_4_Start_Range 0;
BA_ "GenSigTimeoutTime_ORC" SG_ 730 Line_4_Start_Range 0;
BA_ "GenSigTimeoutTime_ADCAM" SG_ 734 Segment_4_X1 0;
BA_ "GenSigTimeoutTime_CVADAS" SG_ 734 Segment_4_X1 0;
BA_ "GenSigTimeoutTime_BSM" SG_ 734 Segment_4_X1 0;
BA_ "GenSigTimeoutTime_BSM2" SG_ 734 Segment_4_X1 0;
BA_ "GenSigTimeoutTime_ECM" SG_ 734 Segment_4_X1 0;
BA_ "GenSigTimeoutTime_EPS" SG_ 734 Segment_4_X1 0;
BA_ "GenSigTimeoutTime_EVCU2" SG_ 734 Segment_4_X1 0;
BA_ "GenSigTimeoutTime_ORC" SG_ 734 Segment_4_X1 0;
BA_ "GenSigTimeoutTime_ADCAM" SG_ 734 Segment_4_X2 0;
BA_ "GenSigTimeoutTime_CVADAS" SG_ 734 Segment_4_X2 0;
BA_ "GenSigTimeoutTime_BSM" SG_ 734 Segment_4_X2 0;
BA_ "GenSigTimeoutTime_BSM2" SG_ 734 Segment_4_X2 0;
BA_ "GenSigTimeoutTime_ECM" SG_ 734 Segment_4_X2 0;
BA_ "GenSigTimeoutTime_EPS" SG_ 734 Segment_4_X2 0;
BA_ "GenSigTimeoutTime_EVCU2" SG_ 734 Segment_4_X2 0;
BA_ "GenSigTimeoutTime_BSM" SG_ 734 Segment_4_Confidence 0;
BA_ "GenSigTimeoutTime_BSM2" SG_ 734 Segment_4_Confidence 0;
BA_ "GenSigTimeoutTime_ECM" SG_ 734 Segment_4_Confidence 0;
BA_ "GenSigTimeoutTime_EPS" SG_ 734 Segment_4_Confidence 0;
BA_ "GenSigTimeoutTime_EVCU2" SG_ 734 Segment_4_Confidence 0;
BA_ "GenSigTimeoutTime_ORC" SG_ 734 Segment_4_Confidence 0;
BA_ "GenSigTimeoutTime_ADCAM" SG_ 734 Segment_4_Confidence 0;
BA_ "GenSigTimeoutTime_CVADAS" SG_ 734 Segment_4_Confidence 0;
BA_ "GenSigTimeoutTime_ADCAM" SG_ 734 Segment_4_ID 0;
BA_ "GenSigTimeoutTime_CVADAS" SG_ 734 Segment_4_ID 0;
BA_ "GenSigTimeoutTime_BSM" SG_ 734 Segment_4_ID 0;
BA_ "GenSigTimeoutTime_BSM2" SG_ 734 Segment_4_ID 0;
BA_ "GenSigTimeoutTime_ECM" SG_ 734 Segment_4_ID 0;
BA_ "GenSigTimeoutTime_EPS" SG_ 734 Segment_4_ID 0;
BA_ "GenSigTimeoutTime_EVCU2" SG_ 734 Segment_4_ID 0;
BA_ "GenSigTimeoutTime_ORC" SG_ 734 Segment_4_ID 0;
BA_ "GenSigTimeoutTime_ADCAM" SG_ 730 MessageCounter_ADAS_FD_LANES_1 0;
BA_ "GenSigTimeoutTime_CVADAS" SG_ 730 MessageCounter_ADAS_FD_LANES_1 0;
BA_ "GenSigTimeoutTime_BSM" SG_ 730 MessageCounter_ADAS_FD_LANES_1 0;
BA_ "GenSigTimeoutTime_BSM2" SG_ 730 MessageCounter_ADAS_FD_LANES_1 0;
BA_ "GenSigTimeoutTime_ECM" SG_ 730 MessageCounter_ADAS_FD_LANES_1 0;
BA_ "GenSigTimeoutTime_EPS" SG_ 730 MessageCounter_ADAS_FD_LANES_1 0;
BA_ "GenSigTimeoutTime_EVCU2" SG_ 730 MessageCounter_ADAS_FD_LANES_1 0;
BA_ "GenSigTimeoutTime_ORC" SG_ 730 MessageCounter_ADAS_FD_LANES_1 0;
BA_ "GenSigTimeoutTime_ADCAM" SG_ 730 Line_4_Type 0;
BA_ "GenSigTimeoutTime_CVADAS" SG_ 730 Line_4_Type 0;
BA_ "GenSigTimeoutTime_BSM" SG_ 730 Line_4_Type 0;
BA_ "GenSigTimeoutTime_BSM2" SG_ 730 Line_4_Type 0;
BA_ "GenSigTimeoutTime_ECM" SG_ 730 Line_4_Type 0;
BA_ "GenSigTimeoutTime_EPS" SG_ 730 Line_4_Type 0;
BA_ "GenSigTimeoutTime_EVCU2" SG_ 730 Line_4_Type 0;
BA_ "GenSigTimeoutTime_ORC" SG_ 730 Line_4_Type 0;
BA_ "GenSigTimeoutTime_ADCAM" SG_ 730 MAC_ADAS_FD_LANES_1 0;
BA_ "GenSigTimeoutTime_CVADAS" SG_ 730 MAC_ADAS_FD_LANES_1 0;
BA_ "GenSigTimeoutTime_BSM" SG_ 730 MAC_ADAS_FD_LANES_1 0;
BA_ "GenSigTimeoutTime_BSM2" SG_ 730 MAC_ADAS_FD_LANES_1 0;
BA_ "GenSigTimeoutTime_ECM" SG_ 730 MAC_ADAS_FD_LANES_1 0;
BA_ "GenSigTimeoutTime_EPS" SG_ 730 MAC_ADAS_FD_LANES_1 0;
BA_ "GenSigTimeoutTime_EVCU2" SG_ 730 MAC_ADAS_FD_LANES_1 0;
BA_ "GenSigTimeoutTime_ORC" SG_ 730 MAC_ADAS_FD_LANES_1 0;
BA_ "GenSigTimeoutTime_ADCAM" SG_ 734 Segment_7_Y1 0;
BA_ "GenSigTimeoutTime_CVADAS" SG_ 734 Segment_7_Y1 0;
BA_ "GenSigTimeoutTime_BSM" SG_ 734 Segment_7_Y1 0;
BA_ "GenSigTimeoutTime_BSM2" SG_ 734 Segment_7_Y1 0;
BA_ "GenSigTimeoutTime_ECM" SG_ 734 Segment_7_Y1 0;
BA_ "GenSigTimeoutTime_EPS" SG_ 734 Segment_7_Y1 0;
BA_ "GenSigTimeoutTime_EVCU2" SG_ 734 Segment_7_Y1 0;
BA_ "GenSigTimeoutTime_ORC" SG_ 734 Segment_7_Y1 0;
BA_ "GenSigTimeoutTime_ADCAM" SG_ 734 Segment_7_Y2 0;
BA_ "GenSigTimeoutTime_CVADAS" SG_ 734 Segment_7_Y2 0;
BA_ "GenSigTimeoutTime_BSM" SG_ 734 Segment_7_Y2 0;
BA_ "GenSigTimeoutTime_BSM2" SG_ 734 Segment_7_Y2 0;
BA_ "GenSigTimeoutTime_ECM" SG_ 734 Segment_7_Y2 0;
BA_ "GenSigTimeoutTime_EPS" SG_ 734 Segment_7_Y2 0;
BA_ "GenSigTimeoutTime_EVCU2" SG_ 734 Segment_7_Y2 0;
BA_ "GenSigTimeoutTime_ORC" SG_ 734 Segment_7_Y2 0;
BA_ "GenSigTimeoutTime_ADCAM" SG_ 734 Segment_6_Y1 0;
BA_ "GenSigTimeoutTime_CVADAS" SG_ 734 Segment_6_Y1 0;
BA_ "GenSigTimeoutTime_BSM" SG_ 734 Segment_6_Y1 0;
BA_ "GenSigTimeoutTime_BSM2" SG_ 734 Segment_6_Y1 0;
BA_ "GenSigTimeoutTime_ECM" SG_ 734 Segment_6_Y1 0;
BA_ "GenSigTimeoutTime_EPS" SG_ 734 Segment_6_Y1 0;
BA_ "GenSigTimeoutTime_EVCU2" SG_ 734 Segment_6_Y1 0;
BA_ "GenSigTimeoutTime_ORC" SG_ 734 Segment_6_Y1 0;
BA_ "GenSigTimeoutTime_ADCAM" SG_ 734 Segment_6_Y2 0;
BA_ "GenSigTimeoutTime_CVADAS" SG_ 734 Segment_6_Y2 0;
BA_ "GenSigTimeoutTime_BSM" SG_ 734 Segment_6_Y2 0;
BA_ "GenSigTimeoutTime_BSM2" SG_ 734 Segment_6_Y2 0;
BA_ "GenSigTimeoutTime_ECM" SG_ 734 Segment_6_Y2 0;
BA_ "GenSigTimeoutTime_EPS" SG_ 734 Segment_6_Y2 0;
BA_ "GenSigTimeoutTime_EVCU2" SG_ 734 Segment_6_Y2 0;
BA_ "GenSigTimeoutTime_ORC" SG_ 734 Segment_6_Y2 0;
BA_ "GenSigTimeoutTime_ADCAM" SG_ 734 Segment_6_X2 0;
BA_ "GenSigTimeoutTime_CVADAS" SG_ 734 Segment_6_X2 0;
BA_ "GenSigTimeoutTime_BSM" SG_ 734 Segment_6_X2 0;
BA_ "GenSigTimeoutTime_BSM2" SG_ 734 Segment_6_X2 0;
BA_ "GenSigTimeoutTime_ECM" SG_ 734 Segment_6_X2 0;
BA_ "GenSigTimeoutTime_EPS" SG_ 734 Segment_6_X2 0;
BA_ "GenSigTimeoutTime_EVCU2" SG_ 734 Segment_6_X2 0;
BA_ "GenSigTimeoutTime_ORC" SG_ 734 Segment_6_X2 0;
BA_ "GenSigTimeoutTime_ADCAM" SG_ 734 Segment_6_X1 0;
BA_ "GenSigTimeoutTime_CVADAS" SG_ 734 Segment_6_X1 0;
BA_ "GenSigTimeoutTime_BSM" SG_ 734 Segment_6_X1 0;
BA_ "GenSigTimeoutTime_BSM2" SG_ 734 Segment_6_X1 0;
BA_ "GenSigTimeoutTime_ECM" SG_ 734 Segment_6_X1 0;
BA_ "GenSigTimeoutTime_EPS" SG_ 734 Segment_6_X1 0;
BA_ "GenSigTimeoutTime_EVCU2" SG_ 734 Segment_6_X1 0;
BA_ "GenSigTimeoutTime_ORC" SG_ 734 Segment_6_X1 0;
BA_ "GenSigTimeoutTime_ADCAM" SG_ 734 Segment_7_Confidence 0;
BA_ "GenSigTimeoutTime_CVADAS" SG_ 734 Segment_7_Confidence 0;
BA_ "GenSigTimeoutTime_BSM" SG_ 734 Segment_7_Confidence 0;
BA_ "GenSigTimeoutTime_BSM2" SG_ 734 Segment_7_Confidence 0;
BA_ "GenSigTimeoutTime_ECM" SG_ 734 Segment_7_Confidence 0;
BA_ "GenSigTimeoutTime_EPS" SG_ 734 Segment_7_Confidence 0;
BA_ "GenSigTimeoutTime_EVCU2" SG_ 734 Segment_7_Confidence 0;
BA_ "GenSigTimeoutTime_ORC" SG_ 734 Segment_7_Confidence 0;
BA_ "GenSigTimeoutTime_ADCAM" SG_ 734 Segment_7_ID 0;
BA_ "GenSigTimeoutTime_CVADAS" SG_ 734 Segment_7_ID 0;
BA_ "GenSigTimeoutTime_BSM" SG_ 734 Segment_7_ID 0;
BA_ "GenSigTimeoutTime_BSM2" SG_ 734 Segment_7_ID 0;
BA_ "GenSigTimeoutTime_ECM" SG_ 734 Segment_7_ID 0;
BA_ "GenSigTimeoutTime_EPS" SG_ 734 Segment_7_ID 0;
BA_ "GenSigTimeoutTime_EVCU2" SG_ 734 Segment_7_ID 0;
BA_ "GenSigTimeoutTime_ORC" SG_ 734 Segment_7_ID 0;
BA_ "GenSigTimeoutTime_ADCAM" SG_ 734 Segment_7_X1 0;
BA_ "GenSigTimeoutTime_CVADAS" SG_ 734 Segment_7_X1 0;
BA_ "GenSigTimeoutTime_BSM" SG_ 734 Segment_7_X1 0;
BA_ "GenSigTimeoutTime_BSM2" SG_ 734 Segment_7_X1 0;
BA_ "GenSigTimeoutTime_ECM" SG_ 734 Segment_7_X1 0;
BA_ "GenSigTimeoutTime_EPS" SG_ 734 Segment_7_X1 0;
BA_ "GenSigTimeoutTime_EVCU2" SG_ 734 Segment_7_X1 0;
BA_ "GenSigTimeoutTime_ORC" SG_ 734 Segment_7_X1 0;
BA_ "GenSigTimeoutTime_ADCAM" SG_ 734 Segment_7_X2 0;
BA_ "GenSigTimeoutTime_CVADAS" SG_ 734 Segment_7_X2 0;
BA_ "GenSigTimeoutTime_BSM" SG_ 734 Segment_7_X2 0;
BA_ "GenSigTimeoutTime_BSM2" SG_ 734 Segment_7_X2 0;
BA_ "GenSigTimeoutTime_ECM" SG_ 734 Segment_7_X2 0;
BA_ "GenSigTimeoutTime_EPS" SG_ 734 Segment_7_X2 0;
BA_ "GenSigTimeoutTime_EVCU2" SG_ 734 Segment_7_X2 0;
BA_ "GenSigTimeoutTime_ORC" SG_ 734 Segment_7_X2 0;
BA_ "GenSigTimeoutTime_ADCAM" SG_ 734 Segment_5_Confidence 0;
BA_ "GenSigTimeoutTime_CVADAS" SG_ 734 Segment_5_Confidence 0;
BA_ "GenSigTimeoutTime_BSM" SG_ 734 Segment_5_Confidence 0;
BA_ "GenSigTimeoutTime_BSM2" SG_ 734 Segment_5_Confidence 0;
BA_ "GenSigTimeoutTime_ECM" SG_ 734 Segment_5_Confidence 0;
BA_ "GenSigTimeoutTime_EPS" SG_ 734 Segment_5_Confidence 0;
BA_ "GenSigTimeoutTime_EVCU2" SG_ 734 Segment_5_Confidence 0;
BA_ "GenSigTimeoutTime_ORC" SG_ 734 Segment_5_Confidence 0;
BA_ "GenSigTimeoutTime_ADCAM" SG_ 734 Segment_5_ID 0;
BA_ "GenSigTimeoutTime_CVADAS" SG_ 734 Segment_5_ID 0;
BA_ "GenSigTimeoutTime_BSM" SG_ 734 Segment_5_ID 0;
BA_ "GenSigTimeoutTime_BSM2" SG_ 734 Segment_5_ID 0;
BA_ "GenSigTimeoutTime_ECM" SG_ 734 Segment_5_ID 0;
BA_ "GenSigTimeoutTime_EPS" SG_ 734 Segment_5_ID 0;
BA_ "GenSigTimeoutTime_EVCU2" SG_ 734 Segment_5_ID 0;
BA_ "GenSigTimeoutTime_ORC" SG_ 734 Segment_5_ID 0;
BA_ "GenSigTimeoutTime_ADCAM" SG_ 734 Segment_5_X1 0;
BA_ "GenSigTimeoutTime_CVADAS" SG_ 734 Segment_5_X1 0;
BA_ "GenSigTimeoutTime_BSM" SG_ 734 Segment_5_X1 0;
BA_ "GenSigTimeoutTime_BSM2" SG_ 734 Segment_5_X1 0;
BA_ "GenSigTimeoutTime_ECM" SG_ 734 Segment_5_X1 0;
BA_ "GenSigTimeoutTime_EPS" SG_ 734 Segment_5_X1 0;
BA_ "GenSigTimeoutTime_EVCU2" SG_ 734 Segment_5_X1 0;
BA_ "GenSigTimeoutTime_ORC" SG_ 734 Segment_5_X1 0;
BA_ "GenSigTimeoutTime_ADCAM" SG_ 734 Segment_5_X2 0;
BA_ "GenSigTimeoutTime_CVADAS" SG_ 734 Segment_5_X2 0;
BA_ "GenSigTimeoutTime_BSM" SG_ 734 Segment_5_X2 0;
BA_ "GenSigTimeoutTime_BSM2" SG_ 734 Segment_5_X2 0;
BA_ "GenSigTimeoutTime_ECM" SG_ 734 Segment_5_X2 0;
BA_ "GenSigTimeoutTime_EPS" SG_ 734 Segment_5_X2 0;
BA_ "GenSigTimeoutTime_EVCU2" SG_ 734 Segment_5_X2 0;
BA_ "GenSigTimeoutTime_ORC" SG_ 734 Segment_5_X2 0;
BA_ "GenSigTimeoutTime_ADCAM" SG_ 734 Segment_5_Y1 0;
BA_ "GenSigTimeoutTime_CVADAS" SG_ 734 Segment_5_Y1 0;
BA_ "GenSigTimeoutTime_BSM" SG_ 734 Segment_5_Y1 0;
BA_ "GenSigTimeoutTime_BSM2" SG_ 734 Segment_5_Y1 0;
BA_ "GenSigTimeoutTime_ECM" SG_ 734 Segment_5_Y1 0;
BA_ "GenSigTimeoutTime_EPS" SG_ 734 Segment_5_Y1 0;
BA_ "GenSigTimeoutTime_EVCU2" SG_ 734 Segment_5_Y1 0;
BA_ "GenSigTimeoutTime_ORC" SG_ 734 Segment_5_Y1 0;
BA_ "GenSigTimeoutTime_ADCAM" SG_ 734 Segment_5_Y2 0;
BA_ "GenSigTimeoutTime_CVADAS" SG_ 734 Segment_5_Y2 0;
BA_ "GenSigTimeoutTime_BSM" SG_ 734 Segment_5_Y2 0;
BA_ "GenSigTimeoutTime_BSM2" SG_ 734 Segment_5_Y2 0;
BA_ "GenSigTimeoutTime_ECM" SG_ 734 Segment_5_Y2 0;
BA_ "GenSigTimeoutTime_EPS" SG_ 734 Segment_5_Y2 0;
BA_ "GenSigTimeoutTime_EVCU2" SG_ 734 Segment_5_Y2 0;
BA_ "GenSigTimeoutTime_ORC" SG_ 734 Segment_5_Y2 0;
BA_ "GenSigTimeoutTime_ADCAM" SG_ 734 Segment_6_Confidence 0;
BA_ "GenSigTimeoutTime_CVADAS" SG_ 734 Segment_6_Confidence 0;
BA_ "GenSigTimeoutTime_BSM" SG_ 734 Segment_6_Confidence 0;
BA_ "GenSigTimeoutTime_BSM2" SG_ 734 Segment_6_Confidence 0;
BA_ "GenSigTimeoutTime_ECM" SG_ 734 Segment_6_Confidence 0;
BA_ "GenSigTimeoutTime_EPS" SG_ 734 Segment_6_Confidence 0;
BA_ "GenSigTimeoutTime_EVCU2" SG_ 734 Segment_6_Confidence 0;
BA_ "GenSigTimeoutTime_ORC" SG_ 734 Segment_6_Confidence 0;
BA_ "GenSigTimeoutTime_ADCAM" SG_ 734 Segment_6_ID 0;
BA_ "GenSigTimeoutTime_CVADAS" SG_ 734 Segment_6_ID 0;
BA_ "GenSigTimeoutTime_BSM" SG_ 734 Segment_6_ID 0;
BA_ "GenSigTimeoutTime_BSM2" SG_ 734 Segment_6_ID 0;
BA_ "GenSigTimeoutTime_ECM" SG_ 734 Segment_6_ID 0;
BA_ "GenSigTimeoutTime_EPS" SG_ 734 Segment_6_ID 0;
BA_ "GenSigTimeoutTime_EVCU2" SG_ 734 Segment_6_ID 0;
BA_ "GenSigTimeoutTime_ORC" SG_ 734 Segment_6_ID 0;
BA_ "GenSigTimeoutTime_ADCAM" SG_ 734 Segment_8_ID 0;
BA_ "GenSigTimeoutTime_CVADAS" SG_ 734 Segment_8_ID 0;
BA_ "GenSigTimeoutTime_BSM" SG_ 734 Segment_8_ID 0;
BA_ "GenSigTimeoutTime_BSM2" SG_ 734 Segment_8_ID 0;
BA_ "GenSigTimeoutTime_ECM" SG_ 734 Segment_8_ID 0;
BA_ "GenSigTimeoutTime_EPS" SG_ 734 Segment_8_ID 0;
BA_ "GenSigTimeoutTime_EVCU2" SG_ 734 Segment_8_ID 0;
BA_ "GenSigTimeoutTime_ORC" SG_ 734 Segment_8_ID 0;
BA_ "GenSigTimeoutTime_EVCU2" SG_ 734 Segment_8_Confidence 0;
BA_ "GenSigTimeoutTime_ORC" SG_ 734 Segment_8_Confidence 0;
BA_ "GenSigTimeoutTime_ADCAM" SG_ 734 Segment_8_X1 0;
BA_ "GenSigTimeoutTime_CVADAS" SG_ 734 Segment_8_X1 0;
BA_ "GenSigTimeoutTime_BSM" SG_ 734 Segment_8_X1 0;
BA_ "GenSigTimeoutTime_BSM2" SG_ 734 Segment_8_X1 0;
BA_ "GenSigTimeoutTime_ECM" SG_ 734 Segment_8_X1 0;
BA_ "GenSigTimeoutTime_EPS" SG_ 734 Segment_8_X1 0;
BA_ "GenSigTimeoutTime_EVCU2" SG_ 734 Segment_8_X1 0;
BA_ "GenSigTimeoutTime_ORC" SG_ 734 Segment_8_X1 0;
BA_ "GenSigTimeoutTime_ADCAM" SG_ 734 Segment_8_X2 0;
BA_ "GenSigTimeoutTime_CVADAS" SG_ 734 Segment_8_X2 0;
BA_ "GenSigTimeoutTime_BSM" SG_ 734 Segment_8_X2 0;
BA_ "GenSigTimeoutTime_BSM2" SG_ 734 Segment_8_X2 0;
BA_ "GenSigTimeoutTime_ECM" SG_ 734 Segment_8_X2 0;
BA_ "GenSigTimeoutTime_EPS" SG_ 734 Segment_8_X2 0;
BA_ "GenSigTimeoutTime_EVCU2" SG_ 734 Segment_8_X2 0;
BA_ "GenSigTimeoutTime_ORC" SG_ 734 Segment_8_X2 0;
BA_ "GenSigTimeoutTime_ADCAM" SG_ 734 Segment_8_Y1 0;
BA_ "GenSigTimeoutTime_CVADAS" SG_ 734 Segment_8_Y1 0;
BA_ "GenSigTimeoutTime_BSM" SG_ 734 Segment_8_Y1 0;
BA_ "GenSigTimeoutTime_BSM2" SG_ 734 Segment_8_Y1 0;
BA_ "GenSigTimeoutTime_ECM" SG_ 734 Segment_8_Y1 0;
BA_ "GenSigTimeoutTime_EPS" SG_ 734 Segment_8_Y1 0;
BA_ "GenSigTimeoutTime_EVCU2" SG_ 734 Segment_8_Y1 0;
BA_ "GenSigTimeoutTime_ORC" SG_ 734 Segment_8_Y1 0;
BA_ "GenSigTimeoutTime_ADCAM" SG_ 734 Segment_8_Y2 0;
BA_ "GenSigTimeoutTime_CVADAS" SG_ 734 Segment_8_Y2 0;
BA_ "GenSigTimeoutTime_BSM" SG_ 734 Segment_8_Y2 0;
BA_ "GenSigTimeoutTime_BSM2" SG_ 734 Segment_8_Y2 0;
BA_ "GenSigTimeoutTime_ECM" SG_ 734 Segment_8_Y2 0;
BA_ "GenSigTimeoutTime_EPS" SG_ 734 Segment_8_Y2 0;
BA_ "GenSigTimeoutTime_EVCU2" SG_ 734 Segment_8_Y2 0;
BA_ "GenSigTimeoutTime_ORC" SG_ 734 Segment_8_Y2 0;
BA_ "GenSigTimeoutTime_ADCAM" SG_ 210 ACC_Axle_Torque_VIP 0;
BA_ "GenSigTimeoutTime_CVADAS" SG_ 210 ACC_Axle_Torque_VIP 0;
BA_ "GenSigStartValue" SG_ 210 ACC_Axle_Torque_VIP 32768;
BA_ "GenSigTimeoutTime_BSM" SG_ 210 ACC_Axle_Torque_VIP 0;
BA_ "GenSigTimeoutTime_BSM2" SG_ 210 ACC_Axle_Torque_VIP 0;
BA_ "GenSigTimeoutTime_EPS" SG_ 210 ACC_Axle_Torque_VIP 0;
BA_ "GenSigTimeoutTime_EVCU2" SG_ 210 ACC_Axle_Torque_VIP 0;
BA_ "GenSigTimeoutTime_ORC" SG_ 210 ACC_Axle_Torque_VIP 0;
BA_ "GenSigTimeoutTime_MPAD" SG_ 97 GTS_Byte3 0;
BA_ "GenSigTimeoutTime_ADCAM" SG_ 97 GTS_Byte3 0;
BA_ "GenSigTimeoutTime_CVADAS" SG_ 97 GTS_Byte3 0;
BA_ "GenSigTimeoutTime_BSM" SG_ 97 GTS_Byte3 0;
BA_ "GenSigTimeoutTime_BSM2" SG_ 97 GTS_Byte3 0;
BA_ "GenSigTimeoutTime_EPS" SG_ 97 GTS_Byte3 0;
BA_ "GenSigTimeoutTime_ADCAM" SG_ 209 LC_Jerk_VIP 0;
BA_ "GenSigTimeoutTime_CVADAS" SG_ 209 LC_Jerk_VIP 0;
BA_ "GenSigTimeoutTime_BSM" SG_ 209 LC_Jerk_VIP 0;
BA_ "GenSigTimeoutTime_BSM2" SG_ 209 LC_Jerk_VIP 0;
BA_ "GenSigTimeoutTime_EPS" SG_ 209 LC_Jerk_VIP 0;
BA_ "GenSigTimeoutTime_EVCU2" SG_ 209 LC_Jerk_VIP 0;
BA_ "GenSigTimeoutTime_ORC" SG_ 209 LC_Jerk_VIP 0;
BA_ "GenSigTimeoutTime_ADCAM" SG_ 209 LKA_LAT_CTRL_RequestSts_VIP 0;
BA_ "GenSigTimeoutTime_CVADAS" SG_ 209 LKA_LAT_CTRL_RequestSts_VIP 0;
BA_ "GenSigTimeoutTime_BSM" SG_ 209 LKA_LAT_CTRL_RequestSts_VIP 0;
BA_ "GenSigTimeoutTime_BSM2" SG_ 209 LKA_LAT_CTRL_RequestSts_VIP 0;
BA_ "GenSigTimeoutTime_EPS" SG_ 209 LKA_LAT_CTRL_RequestSts_VIP 0;
BA_ "GenSigTimeoutTime_EVCU2" SG_ 209 LKA_LAT_CTRL_RequestSts_VIP 0;
BA_ "GenSigTimeoutTime_ORC" SG_ 209 LKA_LAT_CTRL_RequestSts_VIP 0;
BA_ "GenSigTimeoutTime_ADCAM" SG_ 209 Object_Dist_VIP 0;
BA_ "GenSigTimeoutTime_CVADAS" SG_ 209 Object_Dist_VIP 0;
BA_ "GenSigStartValue" SG_ 209 Object_Dist_VIP 255;
BA_ "GenSigTimeoutTime_BSM" SG_ 209 Object_Dist_VIP 0;
BA_ "GenSigTimeoutTime_BSM2" SG_ 209 Object_Dist_VIP 0;
BA_ "GenSigTimeoutTime_EPS" SG_ 209 Object_Dist_VIP 0;
BA_ "GenSigTimeoutTime_EVCU2" SG_ 209 Object_Dist_VIP 0;
BA_ "GenSigTimeoutTime_ORC" SG_ 209 Object_Dist_VIP 0;
BA_ "GenSigTimeoutTime_ADCAM" SG_ 209 PEB_SystemSts_VIP 0;
BA_ "GenSigTimeoutTime_CVADAS" SG_ 209 PEB_SystemSts_VIP 0;
BA_ "GenSigTimeoutTime_BSM" SG_ 209 PEB_SystemSts_VIP 0;
BA_ "GenSigTimeoutTime_BSM2" SG_ 209 PEB_SystemSts_VIP 0;
BA_ "GenSigTimeoutTime_EPS" SG_ 209 PEB_SystemSts_VIP 0;
BA_ "GenSigTimeoutTime_EVCU2" SG_ 209 PEB_SystemSts_VIP 0;
BA_ "GenSigTimeoutTime_ORC" SG_ 209 PEB_SystemSts_VIP 0;
BA_ "GenSigTimeoutTime_ADCAM" SG_ 209 Prefill_Req_VIP 0;
BA_ "GenSigTimeoutTime_CVADAS" SG_ 209 Prefill_Req_VIP 0;
BA_ "GenSigTimeoutTime_BSM" SG_ 209 Prefill_Req_VIP 0;
BA_ "GenSigTimeoutTime_BSM2" SG_ 209 Prefill_Req_VIP 0;
BA_ "GenSigTimeoutTime_EPS" SG_ 209 Prefill_Req_VIP 0;
BA_ "GenSigTimeoutTime_EVCU2" SG_ 209 Prefill_Req_VIP 0;
BA_ "GenSigTimeoutTime_ORC" SG_ 209 Prefill_Req_VIP 0;
BA_ "GenSigTimeoutTime_ADCAM" SG_ 209 SteeringVibration_Rq_VIP 0;
BA_ "GenSigTimeoutTime_CVADAS" SG_ 209 SteeringVibration_Rq_VIP 0;
BA_ "GenSigTimeoutTime_BSM" SG_ 209 SteeringVibration_Rq_VIP 0;
BA_ "GenSigTimeoutTime_BSM2" SG_ 209 SteeringVibration_Rq_VIP 0;
BA_ "GenSigTimeoutTime_EPS" SG_ 209 SteeringVibration_Rq_VIP 0;
BA_ "GenSigTimeoutTime_EVCU2" SG_ 209 SteeringVibration_Rq_VIP 0;
BA_ "GenSigTimeoutTime_ORC" SG_ 209 SteeringVibration_Rq_VIP 0;
BA_ "GenSigTimeoutTime_ADCAM" SG_ 209 SteeringVibration_Type_VIP 0;
BA_ "GenSigTimeoutTime_CVADAS" SG_ 209 SteeringVibration_Type_VIP 0;
BA_ "GenSigTimeoutTime_BSM" SG_ 209 SteeringVibration_Type_VIP 0;
BA_ "GenSigTimeoutTime_BSM2" SG_ 209 SteeringVibration_Type_VIP 0;
BA_ "GenSigTimeoutTime_EPS" SG_ 209 SteeringVibration_Type_VIP 0;
BA_ "GenSigTimeoutTime_EVCU2" SG_ 209 SteeringVibration_Type_VIP 0;
BA_ "GenSigTimeoutTime_ORC" SG_ 209 SteeringVibration_Type_VIP 0;
BA_ "GenSigTimeoutTime_ADCAM" SG_ 209 TorqueOverlaySteeringReq_VIP 0;
BA_ "GenSigTimeoutTime_CVADAS" SG_ 209 TorqueOverlaySteeringReq_VIP 0;
BA_ "GenSigStartValue" SG_ 209 TorqueOverlaySteeringReq_VIP 1024;
BA_ "GenSigTimeoutTime_BSM" SG_ 209 TorqueOverlaySteeringReq_VIP 0;
BA_ "GenSigTimeoutTime_BSM2" SG_ 209 TorqueOverlaySteeringReq_VIP 0;
BA_ "GenSigTimeoutTime_EPS" SG_ 209 TorqueOverlaySteeringReq_VIP 0;
BA_ "GenSigTimeoutTime_EVCU2" SG_ 209 TorqueOverlaySteeringReq_VIP 0;
BA_ "GenSigTimeoutTime_ORC" SG_ 209 TorqueOverlaySteeringReq_VIP 0;
BA_ "GenSigTimeoutTime_ADCAM" SG_ 209 ACC_DsrSpeedKPH_VIP 0;
BA_ "GenSigTimeoutTime_CVADAS" SG_ 209 ACC_DsrSpeedKPH_VIP 0;
BA_ "GenSigStartValue" SG_ 209 ACC_DsrSpeedKPH_VIP 255;
BA_ "GenSigTimeoutTime_BSM" SG_ 209 ACC_DsrSpeedKPH_VIP 0;
BA_ "GenSigTimeoutTime_BSM2" SG_ 209 ACC_DsrSpeedKPH_VIP 0;
BA_ "GenSigTimeoutTime_EPS" SG_ 209 ACC_DsrSpeedKPH_VIP 0;
BA_ "GenSigTimeoutTime_EVCU2" SG_ 209 ACC_DsrSpeedKPH_VIP 0;
BA_ "GenSigTimeoutTime_ORC" SG_ 209 ACC_DsrSpeedKPH_VIP 0;
BA_ "GenSigTimeoutTime_ADCAM" SG_ 209 ACC_Engine_Torque_Enabled_VIP 0;
BA_ "GenSigTimeoutTime_CVADAS" SG_ 209 ACC_Engine_Torque_Enabled_VIP 0;
BA_ "GenSigTimeoutTime_BSM" SG_ 209 ACC_Engine_Torque_Enabled_VIP 0;
BA_ "GenSigTimeoutTime_BSM2" SG_ 209 ACC_Engine_Torque_Enabled_VIP 0;
BA_ "GenSigTimeoutTime_EPS" SG_ 209 ACC_Engine_Torque_Enabled_VIP 0;
BA_ "GenSigTimeoutTime_EVCU2" SG_ 209 ACC_Engine_Torque_Enabled_VIP 0;
BA_ "GenSigTimeoutTime_ORC" SG_ 209 ACC_Engine_Torque_Enabled_VIP 0;
BA_ "GenSigTimeoutTime_ADCAM" SG_ 209 ACC_Systemsts_VIP 0;
BA_ "GenSigTimeoutTime_CVADAS" SG_ 209 ACC_Systemsts_VIP 0;
BA_ "GenSigTimeoutTime_BSM" SG_ 209 ACC_Systemsts_VIP 0;
BA_ "GenSigTimeoutTime_BSM2" SG_ 209 ACC_Systemsts_VIP 0;
BA_ "GenSigTimeoutTime_EPS" SG_ 209 ACC_Systemsts_VIP 0;
BA_ "GenSigTimeoutTime_EVCU2" SG_ 209 ACC_Systemsts_VIP 0;
BA_ "GenSigTimeoutTime_ORC" SG_ 209 ACC_Systemsts_VIP 0;
BA_ "GenSigTimeoutTime_ORC" SG_ 209 AEB_Sensitivity_Setting_VIP 0;
BA_ "GenSigTimeoutTime_ADCAM" SG_ 209 AEB_Sensitivity_Setting_VIP 0;
BA_ "GenSigTimeoutTime_CVADAS" SG_ 209 AEB_Sensitivity_Setting_VIP 0;
BA_ "GenSigTimeoutTime_BSM" SG_ 209 AEB_Sensitivity_Setting_VIP 0;
BA_ "GenSigTimeoutTime_BSM2" SG_ 209 AEB_Sensitivity_Setting_VIP 0;
BA_ "GenSigTimeoutTime_EPS" SG_ 209 AEB_Sensitivity_Setting_VIP 0;
BA_ "GenSigTimeoutTime_EVCU2" SG_ 209 AEB_Sensitivity_Setting_VIP 0;
BA_ "GenSigTimeoutTime_ADCAM" SG_ 209 AEB_Systemsts_VIP 0;
BA_ "GenSigTimeoutTime_CVADAS" SG_ 209 AEB_Systemsts_VIP 0;
BA_ "GenSigTimeoutTime_BSM" SG_ 209 AEB_Systemsts_VIP 0;
BA_ "GenSigTimeoutTime_BSM2" SG_ 209 AEB_Systemsts_VIP 0;
BA_ "GenSigTimeoutTime_EPS" SG_ 209 AEB_Systemsts_VIP 0;
BA_ "GenSigTimeoutTime_EVCU2" SG_ 209 AEB_Systemsts_VIP 0;
BA_ "GenSigTimeoutTime_ORC" SG_ 209 AEB_Systemsts_VIP 0;
BA_ "GenSigTimeoutTime_ADCAM" SG_ 209 AEB_Type_VIP 0;
BA_ "GenSigTimeoutTime_CVADAS" SG_ 209 AEB_Type_VIP 0;
BA_ "GenSigTimeoutTime_BSM" SG_ 209 AEB_Type_VIP 0;
BA_ "GenSigTimeoutTime_BSM2" SG_ 209 AEB_Type_VIP 0;
BA_ "GenSigTimeoutTime_EPS" SG_ 209 AEB_Type_VIP 0;
BA_ "GenSigTimeoutTime_EVCU2" SG_ 209 AEB_Type_VIP 0;
BA_ "GenSigTimeoutTime_ORC" SG_ 209 AEB_Type_VIP 0;
BA_ "GenSigTimeoutTime_ADCAM" SG_ 209 Brake_Jerk_Req_VIP 0;
BA_ "GenSigTimeoutTime_CVADAS" SG_ 209 Brake_Jerk_Req_VIP 0;
BA_ "GenSigTimeoutTime_BSM" SG_ 209 Brake_Jerk_Req_VIP 0;
BA_ "GenSigTimeoutTime_BSM2" SG_ 209 Brake_Jerk_Req_VIP 0;
BA_ "GenSigTimeoutTime_EPS" SG_ 209 Brake_Jerk_Req_VIP 0;
BA_ "GenSigTimeoutTime_EVCU2" SG_ 209 Brake_Jerk_Req_VIP 0;
BA_ "GenSigTimeoutTime_ORC" SG_ 209 Brake_Jerk_Req_VIP 0;
BA_ "GenSigTimeoutTime_ADCAM" SG_ 209 CIPV_Fused_VIP 0;
BA_ "GenSigTimeoutTime_CVADAS" SG_ 209 CIPV_Fused_VIP 0;
BA_ "GenSigTimeoutTime_BSM" SG_ 209 CIPV_Fused_VIP 0;
BA_ "GenSigTimeoutTime_BSM2" SG_ 209 CIPV_Fused_VIP 0;
BA_ "GenSigTimeoutTime_EPS" SG_ 209 CIPV_Fused_VIP 0;
BA_ "GenSigTimeoutTime_EVCU2" SG_ 209 CIPV_Fused_VIP 0;
BA_ "GenSigTimeoutTime_ORC" SG_ 209 CIPV_Fused_VIP 0;
BA_ "GenSigTimeoutTime_ADCAM" SG_ 209 DDD_Setting_Avail_VIP 0;
BA_ "GenSigTimeoutTime_CVADAS" SG_ 209 DDD_Setting_Avail_VIP 0;
BA_ "GenSigTimeoutTime_BSM" SG_ 209 DDD_Setting_Avail_VIP 0;
BA_ "GenSigTimeoutTime_BSM2" SG_ 209 DDD_Setting_Avail_VIP 0;
BA_ "GenSigTimeoutTime_EPS" SG_ 209 DDD_Setting_Avail_VIP 0;
BA_ "GenSigTimeoutTime_EVCU2" SG_ 209 DDD_Setting_Avail_VIP 0;
BA_ "GenSigTimeoutTime_ORC" SG_ 209 DDD_Setting_Avail_VIP 0;
BA_ "GenSigTimeoutTime_ADCAM" SG_ 209 DDD_SystemSts_VIP 0;
BA_ "GenSigTimeoutTime_CVADAS" SG_ 209 DDD_SystemSts_VIP 0;
BA_ "GenSigTimeoutTime_BSM" SG_ 209 DDD_SystemSts_VIP 0;
BA_ "GenSigTimeoutTime_BSM2" SG_ 209 DDD_SystemSts_VIP 0;
BA_ "GenSigTimeoutTime_EPS" SG_ 209 DDD_SystemSts_VIP 0;
BA_ "GenSigTimeoutTime_EVCU2" SG_ 209 DDD_SystemSts_VIP 0;
BA_ "GenSigTimeoutTime_ORC" SG_ 209 DDD_SystemSts_VIP 0;
BA_ "GenSigTimeoutTime_ADCAM" SG_ 209 GrMax_Rq_ACC_VIP 0;
BA_ "GenSigTimeoutTime_CVADAS" SG_ 209 GrMax_Rq_ACC_VIP 0;
BA_ "GenSigTimeoutTime_BSM" SG_ 209 GrMax_Rq_ACC_VIP 0;
BA_ "GenSigTimeoutTime_BSM2" SG_ 209 GrMax_Rq_ACC_VIP 0;
BA_ "GenSigTimeoutTime_EPS" SG_ 209 GrMax_Rq_ACC_VIP 0;
BA_ "GenSigTimeoutTime_EVCU2" SG_ 209 GrMax_Rq_ACC_VIP 0;
BA_ "GenSigTimeoutTime_ORC" SG_ 209 GrMax_Rq_ACC_VIP 0;
BA_ "GenSigTimeoutTime_ADCAM" SG_ 209 Intervention_VIP 0;
BA_ "GenSigTimeoutTime_CVADAS" SG_ 209 Intervention_VIP 0;
BA_ "GenSigStartValue" SG_ 209 Intervention_VIP 4095;
BA_ "GenSigTimeoutTime_BSM" SG_ 209 Intervention_VIP 0;
BA_ "GenSigTimeoutTime_BSM2" SG_ 209 Intervention_VIP 0;
BA_ "GenSigTimeoutTime_EPS" SG_ 209 Intervention_VIP 0;
BA_ "GenSigTimeoutTime_EVCU2" SG_ 209 Intervention_VIP 0;
BA_ "GenSigTimeoutTime_ORC" SG_ 209 Intervention_VIP 0;
BA_ "GenSigTimeoutTime_ADCAM" SG_ 209 CRC_ADAS_FD_INFO_VIP 0;
BA_ "GenSigTimeoutTime_CVADAS" SG_ 209 CRC_ADAS_FD_INFO_VIP 0;
BA_ "GenSigTimeoutTime_BSM" SG_ 209 CRC_ADAS_FD_INFO_VIP 0;
BA_ "GenSigTimeoutTime_BSM2" SG_ 209 CRC_ADAS_FD_INFO_VIP 0;
BA_ "GenSigTimeoutTime_EPS" SG_ 209 CRC_ADAS_FD_INFO_VIP 0;
BA_ "GenSigTimeoutTime_EVCU2" SG_ 209 CRC_ADAS_FD_INFO_VIP 0;
BA_ "GenSigTimeoutTime_ORC" SG_ 209 CRC_ADAS_FD_INFO_VIP 0;
BA_ "GenSigTimeoutTime_ADCAM" SG_ 209 MessageCounter_ADAS_FD_INFO_VIP 0;
BA_ "GenSigTimeoutTime_CVADAS" SG_ 209 MessageCounter_ADAS_FD_INFO_VIP 0;
BA_ "GenSigTimeoutTime_BSM" SG_ 209 MessageCounter_ADAS_FD_INFO_VIP 0;
BA_ "GenSigTimeoutTime_BSM2" SG_ 209 MessageCounter_ADAS_FD_INFO_VIP 0;
BA_ "GenSigTimeoutTime_EPS" SG_ 209 MessageCounter_ADAS_FD_INFO_VIP 0;
BA_ "GenSigTimeoutTime_EVCU2" SG_ 209 MessageCounter_ADAS_FD_INFO_VIP 0;
BA_ "GenSigTimeoutTime_ORC" SG_ 209 MessageCounter_ADAS_FD_INFO_VIP 0;
BA_ "GenSigTimeoutTime_ADCAM" SG_ 616 ACC_Set_Speed_Strike_VIP 0;
BA_ "GenSigTimeoutTime_CVADAS" SG_ 616 ACC_Set_Speed_Strike_VIP 0;
BA_ "GenSigSendType" SG_ 616 ACC_Set_Speed_Strike_VIP 3;
BA_ "GenSigTimeoutTime_BSM" SG_ 616 ACC_Set_Speed_Strike_VIP 0;
BA_ "GenSigTimeoutTime_BSM2" SG_ 616 ACC_Set_Speed_Strike_VIP 0;
BA_ "GenSigTimeoutTime_EPS" SG_ 616 ACC_Set_Speed_Strike_VIP 0;
BA_ "GenSigTimeoutTime_EVCU2" SG_ 616 ACC_Set_Speed_Strike_VIP 0;
BA_ "GenSigTimeoutTime_ORC" SG_ 616 ACC_Set_Speed_Strike_VIP 0;
BA_ "GenSigTimeoutTime_ADCAM" SG_ 616 RRCC_DispPopupSts_VIP 0;
BA_ "GenSigTimeoutTime_CVADAS" SG_ 616 RRCC_DispPopupSts_VIP 0;
BA_ "GenSigSendType" SG_ 616 RRCC_DispPopupSts_VIP 3;
BA_ "GenSigTimeoutTime_BSM" SG_ 616 RRCC_DispPopupSts_VIP 0;
BA_ "GenSigTimeoutTime_BSM2" SG_ 616 RRCC_DispPopupSts_VIP 0;
BA_ "GenSigTimeoutTime_EPS" SG_ 616 RRCC_DispPopupSts_VIP 0;
BA_ "GenSigTimeoutTime_EVCU2" SG_ 616 RRCC_DispPopupSts_VIP 0;
BA_ "GenSigTimeoutTime_ORC" SG_ 616 RRCC_DispPopupSts_VIP 0;
BA_ "GenSigTimeoutTime_MPAD" SG_ 213 CRC_VIP_INFO_FD 0;
BA_ "GenSigTimeoutTime_CVADAS" SG_ 213 CRC_VIP_INFO_FD 0;
BA_ "GenSigTimeoutTime_BSM" SG_ 213 CRC_VIP_INFO_FD 0;
BA_ "GenSigTimeoutTime_BSM2" SG_ 213 CRC_VIP_INFO_FD 0;
BA_ "GenSigTimeoutTime_EPS" SG_ 213 CRC_VIP_INFO_FD 0;
BA_ "GenSigTimeoutTime_EVCU2" SG_ 213 CRC_VIP_INFO_FD 0;
BA_ "GenSigTimeoutTime_ORC" SG_ 213 CRC_VIP_INFO_FD 0;
BA_ "GenSigTimeoutTime_MPAD" SG_ 213 MessageCounter_VIP_INFO_FD 0;
BA_ "GenSigTimeoutTime_CVADAS" SG_ 213 MessageCounter_VIP_INFO_FD 0;
BA_ "GenSigTimeoutTime_BSM" SG_ 213 MessageCounter_VIP_INFO_FD 0;
BA_ "GenSigTimeoutTime_BSM2" SG_ 213 MessageCounter_VIP_INFO_FD 0;
BA_ "GenSigTimeoutTime_EPS" SG_ 213 MessageCounter_VIP_INFO_FD 0;
BA_ "GenSigTimeoutTime_EVCU2" SG_ 213 MessageCounter_VIP_INFO_FD 0;
BA_ "GenSigTimeoutTime_ORC" SG_ 213 MessageCounter_VIP_INFO_FD 0;
BA_ "GenSigTimeoutTime_ADCAM" SG_ 616 LKA_FailSts_VIP 0;
BA_ "GenSigTimeoutTime_CVADAS" SG_ 616 LKA_FailSts_VIP 0;
BA_ "GenSigSendType" SG_ 616 LKA_FailSts_VIP 3;
BA_ "GenSigTimeoutTime_BSM" SG_ 616 LKA_FailSts_VIP 0;
BA_ "GenSigTimeoutTime_BSM2" SG_ 616 LKA_FailSts_VIP 0;
BA_ "GenSigTimeoutTime_EPS" SG_ 616 LKA_FailSts_VIP 0;
BA_ "GenSigTimeoutTime_EVCU2" SG_ 616 LKA_FailSts_VIP 0;
BA_ "GenSigTimeoutTime_ORC" SG_ 616 LKA_FailSts_VIP 0;
BA_ "GenSigTimeoutTime_EVCU2" SG_ 97 GTS_Byte3 0;
BA_ "GenSigTimeoutTime_ORC" SG_ 97 GTS_Byte3 0;
BA_ "GenSigTimeoutTime_MPAD" SG_ 97 GTS_CRC 0;
BA_ "GenSigTimeoutTime_ADCAM" SG_ 97 GTS_CRC 0;
BA_ "GenSigTimeoutTime_CVADAS" SG_ 97 GTS_CRC 0;
BA_ "GenSigTimeoutTime_BSM" SG_ 97 GTS_CRC 0;
BA_ "GenSigTimeoutTime_BSM2" SG_ 97 GTS_CRC 0;
BA_ "GenSigTimeoutTime_EPS" SG_ 97 GTS_CRC 0;
BA_ "GenSigTimeoutTime_EVCU2" SG_ 97 GTS_CRC 0;
BA_ "GenSigTimeoutTime_ORC" SG_ 97 GTS_CRC 0;
BA_ "GenSigTimeoutTime_MPAD" SG_ 97 GTS_D 0;
BA_ "GenSigTimeoutTime_ADCAM" SG_ 97 GTS_D 0;
BA_ "GenSigTimeoutTime_CVADAS" SG_ 97 GTS_D 0;
BA_ "GenSigTimeoutTime_BSM" SG_ 97 GTS_D 0;
BA_ "GenSigTimeoutTime_BSM2" SG_ 97 GTS_D 0;
BA_ "GenSigTimeoutTime_EPS" SG_ 97 GTS_D 0;
BA_ "GenSigTimeoutTime_EVCU2" SG_ 97 GTS_D 0;
BA_ "GenSigTimeoutTime_ORC" SG_ 97 GTS_D 0;
BA_ "GenSigTimeoutTime_MPAD" SG_ 97 GTS_SC 0;
BA_ "GenSigTimeoutTime_ADCAM" SG_ 97 GTS_SC 0;
BA_ "GenSigTimeoutTime_CVADAS" SG_ 97 GTS_SC 0;
BA_ "GenSigTimeoutTime_BSM" SG_ 97 GTS_SC 0;
BA_ "GenSigTimeoutTime_BSM2" SG_ 97 GTS_SC 0;
BA_ "GenSigTimeoutTime_EPS" SG_ 97 GTS_SC 0;
BA_ "GenSigTimeoutTime_EVCU2" SG_ 97 GTS_SC 0;
BA_ "GenSigTimeoutTime_ORC" SG_ 97 GTS_SC 0;
BA_ "GenSigTimeoutTime_MPAD" SG_ 97 GTS_Type 0;
BA_ "GenSigTimeoutTime_ADCAM" SG_ 97 GTS_Type 0;
BA_ "GenSigTimeoutTime_CVADAS" SG_ 97 GTS_Type 0;
BA_ "GenSigSendType" SG_ 97 GTS_Type 1;
BA_ "GenSigTimeoutTime_BSM" SG_ 97 GTS_Type 0;
BA_ "GenSigTimeoutTime_BSM2" SG_ 97 GTS_Type 0;
BA_ "GenSigTimeoutTime_EPS" SG_ 97 GTS_Type 0;
BA_ "GenSigTimeoutTime_EVCU2" SG_ 97 GTS_Type 0;
BA_ "GenSigTimeoutTime_ORC" SG_ 97 GTS_Type 0;
BA_ "GenSigTimeoutTime_MPAD" SG_ 97 OfsTimeNSec 0;
BA_ "GenSigTimeoutTime_ADCAM" SG_ 97 OfsTimeNSec 0;
BA_ "GenSigTimeoutTime_CVADAS" SG_ 97 OfsTimeNSec 0;
BA_ "GenSigTimeoutTime_BSM" SG_ 97 OfsTimeNSec 0;
BA_ "GenSigTimeoutTime_BSM2" SG_ 97 OfsTimeNSec 0;
BA_ "GenSigTimeoutTime_EPS" SG_ 97 OfsTimeNSec 0;
BA_ "GenSigTimeoutTime_EVCU2" SG_ 97 OfsTimeNSec 0;
BA_ "GenSigTimeoutTime_ORC" SG_ 97 OfsTimeNSec 0;
BA_ "GenSigTimeoutTime_ADCAM" SG_ 616 AEB_Blind_VIP 0;
BA_ "GenSigTimeoutTime_CVADAS" SG_ 616 AEB_Blind_VIP 0;
BA_ "GenSigSendType" SG_ 616 AEB_Blind_VIP 3;
BA_ "GenSigTimeoutTime_BSM" SG_ 616 AEB_Blind_VIP 0;
BA_ "GenSigTimeoutTime_BSM2" SG_ 616 AEB_Blind_VIP 0;
BA_ "GenSigTimeoutTime_ADCAM" SG_ 616 BlindSpotRightWarn_VIP 0;
BA_ "GenSigTimeoutTime_CVADAS" SG_ 616 BlindSpotRightWarn_VIP 0;
BA_ "GenSigSendType" SG_ 616 BlindSpotRightWarn_VIP 3;
BA_ "GenSigTimeoutTime_BSM" SG_ 616 BlindSpotRightWarn_VIP 0;
BA_ "GenSigTimeoutTime_BSM2" SG_ 616 BlindSpotRightWarn_VIP 0;
BA_ "GenSigTimeoutTime_EPS" SG_ 616 BlindSpotRightWarn_VIP 0;
BA_ "GenSigTimeoutTime_EVCU2" SG_ 616 BlindSpotRightWarn_VIP 0;
BA_ "GenSigTimeoutTime_ORC" SG_ 616 BlindSpotRightWarn_VIP 0;
BA_ "GenSigTimeoutTime_ADCAM" SG_ 616 BSS_Blind_RQSts_VIP 0;
BA_ "GenSigTimeoutTime_CVADAS" SG_ 616 BSS_Blind_RQSts_VIP 0;
BA_ "GenSigSendType" SG_ 616 BSS_Blind_RQSts_VIP 3;
BA_ "GenSigTimeoutTime_BSM" SG_ 616 BSS_Blind_RQSts_VIP 0;
BA_ "GenSigTimeoutTime_BSM2" SG_ 616 BSS_Blind_RQSts_VIP 0;
BA_ "GenSigTimeoutTime_EPS" SG_ 616 BSS_Blind_RQSts_VIP 0;
BA_ "GenSigTimeoutTime_EVCU2" SG_ 616 BSS_Blind_RQSts_VIP 0;
BA_ "GenSigTimeoutTime_ORC" SG_ 616 BSS_Blind_RQSts_VIP 0;
BA_ "GenSigTimeoutTime_EPS" SG_ 616 BSS_CFG_STATSts_VIP 0;
BA_ "GenSigTimeoutTime_EVCU2" SG_ 616 BSS_CFG_STATSts_VIP 0;
BA_ "GenSigTimeoutTime_ORC" SG_ 616 BSS_CFG_STATSts_VIP 0;
BA_ "GenSigTimeoutTime_ADCAM" SG_ 616 BSS_CFG_STATSts_VIP 0;
BA_ "GenSigTimeoutTime_CVADAS" SG_ 616 BSS_CFG_STATSts_VIP 0;
BA_ "GenSigSendType" SG_ 616 BSS_CFG_STATSts_VIP 3;
BA_ "GenSigTimeoutTime_BSM" SG_ 616 BSS_CFG_STATSts_VIP 0;
BA_ "GenSigTimeoutTime_BSM2" SG_ 616 BSS_CFG_STATSts_VIP 0;
BA_ "GenSigTimeoutTime_ADCAM" SG_ 616 BSS_DispPopoupSts_VIP 0;
BA_ "GenSigTimeoutTime_CVADAS" SG_ 616 BSS_DispPopoupSts_VIP 0;
BA_ "GenSigSendType" SG_ 616 BSS_DispPopoupSts_VIP 3;
BA_ "GenSigTimeoutTime_BSM" SG_ 616 BSS_DispPopoupSts_VIP 0;
BA_ "GenSigTimeoutTime_BSM2" SG_ 616 BSS_DispPopoupSts_VIP 0;
BA_ "GenSigTimeoutTime_EPS" SG_ 616 BSS_DispPopoupSts_VIP 0;
BA_ "GenSigTimeoutTime_EVCU2" SG_ 616 BSS_DispPopoupSts_VIP 0;
BA_ "GenSigTimeoutTime_ORC" SG_ 616 BSS_DispPopoupSts_VIP 0;
BA_ "GenSigTimeoutTime_ADCAM" SG_ 616 BSS_SRV_RQSts_VIP 0;
BA_ "GenSigTimeoutTime_CVADAS" SG_ 616 BSS_SRV_RQSts_VIP 0;
BA_ "GenSigSendType" SG_ 616 BSS_SRV_RQSts_VIP 3;
BA_ "GenSigTimeoutTime_BSM" SG_ 616 BSS_SRV_RQSts_VIP 0;
BA_ "GenSigTimeoutTime_BSM2" SG_ 616 BSS_SRV_RQSts_VIP 0;
BA_ "GenSigTimeoutTime_EPS" SG_ 616 BSS_SRV_RQSts_VIP 0;
BA_ "GenSigTimeoutTime_EVCU2" SG_ 616 BSS_SRV_RQSts_VIP 0;
BA_ "GenSigTimeoutTime_ORC" SG_ 616 BSS_SRV_RQSts_VIP 0;
BA_ "GenSigTimeoutTime_ADCAM" SG_ 616 BSS_TrailerSts_VIP 0;
BA_ "GenSigTimeoutTime_CVADAS" SG_ 616 BSS_TrailerSts_VIP 0;
BA_ "GenSigSendType" SG_ 616 BSS_TrailerSts_VIP 3;
BA_ "GenSigTimeoutTime_BSM" SG_ 616 BSS_TrailerSts_VIP 0;
BA_ "GenSigTimeoutTime_BSM2" SG_ 616 BSS_TrailerSts_VIP 0;
BA_ "GenSigTimeoutTime_EPS" SG_ 616 BSS_TrailerSts_VIP 0;
BA_ "GenSigTimeoutTime_EVCU2" SG_ 616 BSS_TrailerSts_VIP 0;
BA_ "GenSigTimeoutTime_ORC" SG_ 616 BSS_TrailerSts_VIP 0;
BA_ "GenSigTimeoutTime_ADCAM" SG_ 616 DDD_DispPopupSts_VIP 0;
BA_ "GenSigTimeoutTime_CVADAS" SG_ 616 DDD_DispPopupSts_VIP 0;
BA_ "GenSigSendType" SG_ 616 DDD_DispPopupSts_VIP 3;
BA_ "GenSigTimeoutTime_BSM" SG_ 616 DDD_DispPopupSts_VIP 0;
BA_ "GenSigTimeoutTime_BSM2" SG_ 616 DDD_DispPopupSts_VIP 0;
BA_ "GenSigTimeoutTime_EPS" SG_ 616 DDD_DispPopupSts_VIP 0;
BA_ "GenSigTimeoutTime_EVCU2" SG_ 616 DDD_DispPopupSts_VIP 0;
BA_ "GenSigTimeoutTime_ORC" SG_ 616 DDD_DispPopupSts_VIP 0;
BA_ "GenSigTimeoutTime_ADCAM" SG_ 616 DDD_FailSts_VIP 0;
BA_ "GenSigTimeoutTime_CVADAS" SG_ 616 DDD_FailSts_VIP 0;
BA_ "GenSigSendType" SG_ 616 DDD_FailSts_VIP 3;
BA_ "GenSigTimeoutTime_BSM" SG_ 616 DDD_FailSts_VIP 0;
BA_ "GenSigTimeoutTime_BSM2" SG_ 616 DDD_FailSts_VIP 0;
BA_ "GenSigTimeoutTime_EPS" SG_ 616 DDD_FailSts_VIP 0;
BA_ "GenSigTimeoutTime_EVCU2" SG_ 616 DDD_FailSts_VIP 0;
BA_ "GenSigTimeoutTime_ORC" SG_ 616 DDD_FailSts_VIP 0;
BA_ "GenSigTimeoutTime_ADCAM" SG_ 616 FCW_Setting_Avail_VIP 0;
BA_ "GenSigTimeoutTime_CVADAS" SG_ 616 FCW_Setting_Avail_VIP 0;
BA_ "GenSigSendType" SG_ 616 FCW_Setting_Avail_VIP 3;
BA_ "GenSigTimeoutTime_BSM" SG_ 616 FCW_Setting_Avail_VIP 0;
BA_ "GenSigTimeoutTime_BSM2" SG_ 616 FCW_Setting_Avail_VIP 0;
BA_ "GenSigTimeoutTime_EPS" SG_ 616 FCW_Setting_Avail_VIP 0;
BA_ "GenSigTimeoutTime_EVCU2" SG_ 616 FCW_Setting_Avail_VIP 0;
BA_ "GenSigTimeoutTime_ORC" SG_ 616 FCW_Setting_Avail_VIP 0;
BA_ "GenSigTimeoutTime_ADCAM" SG_ 616 ICA_Blind_VIP 0;
BA_ "GenSigTimeoutTime_CVADAS" SG_ 616 ICA_Blind_VIP 0;
BA_ "GenSigSendType" SG_ 616 ICA_Blind_VIP 3;
BA_ "GenSigTimeoutTime_BSM" SG_ 616 ICA_Blind_VIP 0;
BA_ "GenSigTimeoutTime_BSM2" SG_ 616 ICA_Blind_VIP 0;
BA_ "GenSigTimeoutTime_EPS" SG_ 616 ICA_Blind_VIP 0;
BA_ "GenSigTimeoutTime_EVCU2" SG_ 616 ICA_Blind_VIP 0;
BA_ "GenSigTimeoutTime_ORC" SG_ 616 ICA_Blind_VIP 0;
BA_ "GenSigTimeoutTime_ADCAM" SG_ 616 LKA_Blind_VIP 0;
BA_ "GenSigTimeoutTime_CVADAS" SG_ 616 LKA_Blind_VIP 0;
BA_ "GenSigSendType" SG_ 616 LKA_Blind_VIP 3;
BA_ "GenSigTimeoutTime_BSM" SG_ 616 LKA_Blind_VIP 0;
BA_ "GenSigTimeoutTime_BSM2" SG_ 616 LKA_Blind_VIP 0;
BA_ "GenSigTimeoutTime_EPS" SG_ 616 LKA_Blind_VIP 0;
BA_ "GenSigTimeoutTime_EVCU2" SG_ 616 LKA_Blind_VIP 0;
BA_ "GenSigTimeoutTime_ORC" SG_ 616 LKA_Blind_VIP 0;
BA_ "GenSigTimeoutTime_MPAD" SG_ 97 OfsTimeSec 0;
BA_ "GenSigTimeoutTime_ADCAM" SG_ 97 OfsTimeSec 0;
BA_ "GenSigTimeoutTime_CVADAS" SG_ 97 OfsTimeSec 0;
BA_ "GenSigTimeoutTime_BSM" SG_ 97 OfsTimeSec 0;
BA_ "GenSigTimeoutTime_BSM2" SG_ 97 OfsTimeSec 0;
BA_ "GenSigTimeoutTime_EPS" SG_ 97 OfsTimeSec 0;
BA_ "GenSigTimeoutTime_EVCU2" SG_ 97 OfsTimeSec 0;
BA_ "GenSigTimeoutTime_ORC" SG_ 97 OfsTimeSec 0;
BA_ "GenSigTimeoutTime_MPAD" SG_ 97 SyncTime 0;
BA_ "GenSigTimeoutTime_ADCAM" SG_ 97 SyncTime 0;
BA_ "GenSigTimeoutTime_CVADAS" SG_ 97 SyncTime 0;
BA_ "GenSigTimeoutTime_BSM" SG_ 97 SyncTime 0;
BA_ "GenSigTimeoutTime_BSM2" SG_ 97 SyncTime 0;
BA_ "GenSigTimeoutTime_EPS" SG_ 97 SyncTime 0;
BA_ "GenSigTimeoutTime_EVCU2" SG_ 97 SyncTime 0;
BA_ "GenSigTimeoutTime_ORC" SG_ 97 SyncTime 0;
BA_ "GenSigTimeoutTime_MPAD" SG_ 213 LKA_LAT_CTRL_ResponseSts_D5 0;
BA_ "GenSigTimeoutTime_CVADAS" SG_ 213 LKA_LAT_CTRL_ResponseSts_D5 0;
BA_ "GenSigTimeoutTime_BSM" SG_ 213 LKA_LAT_CTRL_ResponseSts_D5 0;
BA_ "GenSigTimeoutTime_BSM2" SG_ 213 LKA_LAT_CTRL_ResponseSts_D5 0;
BA_ "GenSigTimeoutTime_EPS" SG_ 213 LKA_LAT_CTRL_ResponseSts_D5 0;
BA_ "GenSigTimeoutTime_EVCU2" SG_ 213 LKA_LAT_CTRL_ResponseSts_D5 0;
BA_ "GenSigTimeoutTime_ORC" SG_ 213 LKA_LAT_CTRL_ResponseSts_D5 0;
BA_ "GenSigTimeoutTime_MPAD" SG_ 213 RRCC_Cancel_Req_D5 0;
BA_ "GenSigTimeoutTime_CVADAS" SG_ 213 RRCC_Cancel_Req_D5 0;
BA_ "GenSigTimeoutTime_BSM" SG_ 213 RRCC_Cancel_Req_D5 0;
BA_ "GenSigTimeoutTime_BSM2" SG_ 213 RRCC_Cancel_Req_D5 0;
BA_ "GenSigTimeoutTime_EPS" SG_ 213 RRCC_Cancel_Req_D5 0;
BA_ "GenSigTimeoutTime_EVCU2" SG_ 213 RRCC_Cancel_Req_D5 0;
BA_ "GenSigTimeoutTime_ORC" SG_ 213 RRCC_Cancel_Req_D5 0;
BA_ "GenSigTimeoutTime_MPAD" SG_ 213 DASEngReqPos_D5 0;
BA_ "GenSigTimeoutTime_CVADAS" SG_ 213 DASEngReqPos_D5 0;
BA_ "GenSigTimeoutTime_BSM" SG_ 213 DASEngReqPos_D5 0;
BA_ "GenSigTimeoutTime_BSM2" SG_ 213 DASEngReqPos_D5 0;
BA_ "GenSigTimeoutTime_EPS" SG_ 213 DASEngReqPos_D5 0;
BA_ "GenSigTimeoutTime_EVCU2" SG_ 213 DASEngReqPos_D5 0;
BA_ "GenSigTimeoutTime_ORC" SG_ 213 DASEngReqPos_D5 0;
BA_ "GenSigTimeoutTime_MPAD" SG_ 213 AEB_Type_Brk_D5 0;
BA_ "GenSigTimeoutTime_CVADAS" SG_ 213 AEB_Type_Brk_D5 0;
BA_ "GenSigTimeoutTime_BSM" SG_ 213 AEB_Type_Brk_D5 0;
BA_ "GenSigTimeoutTime_BSM2" SG_ 213 AEB_Type_Brk_D5 0;
BA_ "GenSigTimeoutTime_EPS" SG_ 213 AEB_Type_Brk_D5 0;
BA_ "GenSigTimeoutTime_EVCU2" SG_ 213 AEB_Type_Brk_D5 0;
BA_ "GenSigTimeoutTime_ORC" SG_ 213 AEB_Type_Brk_D5 0;
BA_ "GenSigTimeoutTime_MPAD" SG_ 213 ACCFSafe_D5 0;
BA_ "GenSigTimeoutTime_CVADAS" SG_ 213 ACCFSafe_D5 0;
BA_ "GenSigTimeoutTime_BSM" SG_ 213 ACCFSafe_D5 0;
BA_ "GenSigTimeoutTime_BSM2" SG_ 213 ACCFSafe_D5 0;
BA_ "GenSigTimeoutTime_EPS" SG_ 213 ACCFSafe_D5 0;
BA_ "GenSigTimeoutTime_EVCU2" SG_ 213 ACCFSafe_D5 0;
BA_ "GenSigTimeoutTime_ORC" SG_ 213 ACCFSafe_D5 0;
BA_ "GenSigTimeoutTime_ADCAM" SG_ 616 LKA_LEDControlSts_VIP 0;
BA_ "GenSigTimeoutTime_CVADAS" SG_ 616 LKA_LEDControlSts_VIP 0;
BA_ "GenSigSendType" SG_ 616 LKA_LEDControlSts_VIP 3;
BA_ "GenSigTimeoutTime_BSM" SG_ 616 LKA_LEDControlSts_VIP 0;
BA_ "GenSigTimeoutTime_BSM2" SG_ 616 LKA_LEDControlSts_VIP 0;
BA_ "GenSigTimeoutTime_EPS" SG_ 616 LKA_LEDControlSts_VIP 0;
BA_ "GenSigTimeoutTime_EVCU2" SG_ 616 LKA_LEDControlSts_VIP 0;
BA_ "GenSigTimeoutTime_ORC" SG_ 616 LKA_LEDControlSts_VIP 0;
BA_ "GenSigTimeoutTime_ADCAM" SG_ 616 Set_Speed_KPH_VIP 0;
BA_ "GenSigTimeoutTime_CVADAS" SG_ 616 Set_Speed_KPH_VIP 0;
BA_ "GenSigSendType" SG_ 616 Set_Speed_KPH_VIP 3;
BA_ "GenSigTimeoutTime_BSM" SG_ 616 Set_Speed_KPH_VIP 0;
BA_ "GenSigTimeoutTime_BSM2" SG_ 616 Set_Speed_KPH_VIP 0;
BA_ "GenSigTimeoutTime_EPS" SG_ 616 Set_Speed_KPH_VIP 0;
BA_ "GenSigTimeoutTime_EVCU2" SG_ 616 Set_Speed_KPH_VIP 0;
BA_ "GenSigTimeoutTime_ORC" SG_ 616 Set_Speed_KPH_VIP 0;
BA_ "GenSigTimeoutTime_ADCAM" SG_ 616 Set_Speed_MPH_VIP 0;
BA_ "GenSigTimeoutTime_CVADAS" SG_ 616 Set_Speed_MPH_VIP 0;
BA_ "GenSigSendType" SG_ 616 Set_Speed_MPH_VIP 3;
BA_ "GenSigTimeoutTime_BSM" SG_ 616 Set_Speed_MPH_VIP 0;
BA_ "GenSigTimeoutTime_BSM2" SG_ 616 Set_Speed_MPH_VIP 0;
BA_ "GenSigTimeoutTime_EPS" SG_ 616 Set_Speed_MPH_VIP 0;
BA_ "GenSigTimeoutTime_EVCU2" SG_ 616 Set_Speed_MPH_VIP 0;
BA_ "GenSigTimeoutTime_ORC" SG_ 616 Set_Speed_MPH_VIP 0;
BA_ "GenSigTimeoutTime_ADCAM" SG_ 616 BlindSpotLeftWarn_VIP 0;
BA_ "GenSigTimeoutTime_CVADAS" SG_ 616 BlindSpotLeftWarn_VIP 0;
BA_ "GenSigSendType" SG_ 616 BlindSpotLeftWarn_VIP 3;
BA_ "GenSigTimeoutTime_BSM" SG_ 616 BlindSpotLeftWarn_VIP 0;
BA_ "GenSigTimeoutTime_BSM2" SG_ 616 BlindSpotLeftWarn_VIP 0;
BA_ "GenSigTimeoutTime_EPS" SG_ 616 BlindSpotLeftWarn_VIP 0;
BA_ "GenSigTimeoutTime_EVCU2" SG_ 616 BlindSpotLeftWarn_VIP 0;
BA_ "GenSigTimeoutTime_ORC" SG_ 616 BlindSpotLeftWarn_VIP 0;
BA_ "GenSigTimeoutTime_ADCAM" SG_ 616 AEB_DispPopupSts_VIP 0;
BA_ "GenSigTimeoutTime_CVADAS" SG_ 616 AEB_DispPopupSts_VIP 0;
BA_ "GenSigSendType" SG_ 616 AEB_DispPopupSts_VIP 3;
BA_ "GenSigTimeoutTime_BSM" SG_ 616 AEB_DispPopupSts_VIP 0;
BA_ "GenSigTimeoutTime_BSM2" SG_ 616 AEB_DispPopupSts_VIP 0;
BA_ "GenSigTimeoutTime_EPS" SG_ 616 AEB_DispPopupSts_VIP 0;
BA_ "GenSigTimeoutTime_EVCU2" SG_ 616 AEB_DispPopupSts_VIP 0;
BA_ "GenSigTimeoutTime_ORC" SG_ 616 AEB_DispPopupSts_VIP 0;
BA_ "GenSigTimeoutTime_ADCAM" SG_ 616 AEB_FailSts_VIP 0;
BA_ "GenSigTimeoutTime_CVADAS" SG_ 616 AEB_FailSts_VIP 0;
BA_ "GenSigSendType" SG_ 616 AEB_FailSts_VIP 3;
BA_ "GenSigTimeoutTime_BSM" SG_ 616 AEB_FailSts_VIP 0;
BA_ "GenSigTimeoutTime_BSM2" SG_ 616 AEB_FailSts_VIP 0;
BA_ "GenSigTimeoutTime_EPS" SG_ 616 AEB_FailSts_VIP 0;
BA_ "GenSigTimeoutTime_EVCU2" SG_ 616 AEB_FailSts_VIP 0;
BA_ "GenSigTimeoutTime_ORC" SG_ 616 AEB_FailSts_VIP 0;
BA_ "GenSigTimeoutTime_ADCAM" SG_ 616 AEB_Limit_Fail_VIP 0;
BA_ "GenSigTimeoutTime_CVADAS" SG_ 616 AEB_Limit_Fail_VIP 0;
BA_ "GenSigSendType" SG_ 616 AEB_Limit_Fail_VIP 3;
BA_ "GenSigTimeoutTime_BSM" SG_ 616 AEB_Limit_Fail_VIP 0;
BA_ "GenSigTimeoutTime_BSM2" SG_ 616 AEB_Limit_Fail_VIP 0;
BA_ "GenSigTimeoutTime_EPS" SG_ 616 AEB_Limit_Fail_VIP 0;
BA_ "GenSigTimeoutTime_EVCU2" SG_ 616 AEB_Limit_Fail_VIP 0;
BA_ "GenSigTimeoutTime_ORC" SG_ 616 AEB_Limit_Fail_VIP 0;
BA_ "GenSigTimeoutTime_ADCAM" SG_ 616 AEB_Limited_VIP 0;
BA_ "GenSigTimeoutTime_CVADAS" SG_ 616 AEB_Limited_VIP 0;
BA_ "GenSigSendType" SG_ 616 AEB_Limited_VIP 3;
BA_ "GenSigTimeoutTime_BSM" SG_ 616 AEB_Limited_VIP 0;
BA_ "GenSigTimeoutTime_BSM2" SG_ 616 AEB_Limited_VIP 0;
BA_ "GenSigTimeoutTime_EPS" SG_ 616 AEB_Limited_VIP 0;
BA_ "GenSigTimeoutTime_EVCU2" SG_ 616 AEB_Limited_VIP 0;
BA_ "GenSigTimeoutTime_ORC" SG_ 616 AEB_Limited_VIP 0;
BA_ "GenSigTimeoutTime_EPS" SG_ 616 AEB_Blind_VIP 0;
BA_ "GenSigTimeoutTime_EVCU2" SG_ 616 AEB_Blind_VIP 0;
BA_ "GenSigTimeoutTime_ORC" SG_ 616 AEB_Blind_VIP 0;
BA_ "GenSigTimeoutTime_ADCAM" SG_ 616 LR_Chime_RqSts_VIP 0;
BA_ "GenSigTimeoutTime_CVADAS" SG_ 616 LR_Chime_RqSts_VIP 0;
BA_ "GenSigSendType" SG_ 616 LR_Chime_RqSts_VIP 3;
BA_ "GenSigTimeoutTime_BSM" SG_ 616 LR_Chime_RqSts_VIP 0;
BA_ "GenSigTimeoutTime_BSM2" SG_ 616 LR_Chime_RqSts_VIP 0;
BA_ "GenSigTimeoutTime_EPS" SG_ 616 LR_Chime_RqSts_VIP 0;
BA_ "GenSigTimeoutTime_EVCU2" SG_ 616 LR_Chime_RqSts_VIP 0;
BA_ "GenSigTimeoutTime_ORC" SG_ 616 LR_Chime_RqSts_VIP 0;
BA_ "GenSigTimeoutTime_ADCAM" SG_ 616 PEB_Setting_Avail_VIP 0;
BA_ "GenSigTimeoutTime_CVADAS" SG_ 616 PEB_Setting_Avail_VIP 0;
BA_ "GenSigSendType" SG_ 616 PEB_Setting_Avail_VIP 3;
BA_ "GenSigTimeoutTime_BSM" SG_ 616 PEB_Setting_Avail_VIP 0;
BA_ "GenSigTimeoutTime_BSM2" SG_ 616 PEB_Setting_Avail_VIP 0;
BA_ "GenSigTimeoutTime_EPS" SG_ 616 PEB_Setting_Avail_VIP 0;
BA_ "GenSigTimeoutTime_EVCU2" SG_ 616 PEB_Setting_Avail_VIP 0;
BA_ "GenSigTimeoutTime_ORC" SG_ 616 PEB_Setting_Avail_VIP 0;
BA_ "GenSigTimeoutTime_ADCAM" SG_ 616 RR_Chime_RqSts_VIP 0;
BA_ "GenSigTimeoutTime_CVADAS" SG_ 616 RR_Chime_RqSts_VIP 0;
BA_ "GenSigSendType" SG_ 616 RR_Chime_RqSts_VIP 3;
BA_ "GenSigTimeoutTime_BSM" SG_ 616 RR_Chime_RqSts_VIP 0;
BA_ "GenSigTimeoutTime_BSM2" SG_ 616 RR_Chime_RqSts_VIP 0;
BA_ "GenSigTimeoutTime_EPS" SG_ 616 RR_Chime_RqSts_VIP 0;
BA_ "GenSigTimeoutTime_EVCU2" SG_ 616 RR_Chime_RqSts_VIP 0;
BA_ "GenSigTimeoutTime_ORC" SG_ 616 RR_Chime_RqSts_VIP 0;
BA_ "GenSigTimeoutTime_ADCAM" SG_ 616 DisplaySts_Veh_LKA_VIP 0;
BA_ "GenSigTimeoutTime_CVADAS" SG_ 616 DisplaySts_Veh_LKA_VIP 0;
BA_ "GenSigSendType" SG_ 616 DisplaySts_Veh_LKA_VIP 3;
BA_ "GenSigTimeoutTime_BSM" SG_ 616 DisplaySts_Veh_LKA_VIP 0;
BA_ "GenSigTimeoutTime_BSM2" SG_ 616 DisplaySts_Veh_LKA_VIP 0;
BA_ "GenSigTimeoutTime_EPS" SG_ 616 DisplaySts_Veh_LKA_VIP 0;
BA_ "GenSigTimeoutTime_EVCU2" SG_ 616 DisplaySts_Veh_LKA_VIP 0;
BA_ "GenSigTimeoutTime_ORC" SG_ 616 DisplaySts_Veh_LKA_VIP 0;
BA_ "GenSigTimeoutTime_ADCAM" SG_ 616 Lane_DisplaySts_Left_VIP 0;
BA_ "GenSigTimeoutTime_CVADAS" SG_ 616 Lane_DisplaySts_Left_VIP 0;
BA_ "GenSigSendType" SG_ 616 Lane_DisplaySts_Left_VIP 3;
BA_ "GenSigTimeoutTime_BSM" SG_ 616 Lane_DisplaySts_Left_VIP 0;
BA_ "GenSigTimeoutTime_BSM2" SG_ 616 Lane_DisplaySts_Left_VIP 0;
BA_ "GenSigTimeoutTime_EPS" SG_ 616 Lane_DisplaySts_Left_VIP 0;
BA_ "GenSigTimeoutTime_EVCU2" SG_ 616 Lane_DisplaySts_Left_VIP 0;
BA_ "GenSigTimeoutTime_ORC" SG_ 616 Lane_DisplaySts_Left_VIP 0;
BA_ "GenSigTimeoutTime_ADCAM" SG_ 616 Lane_DisplaySts_Right_LKA_VIP 0;
BA_ "GenSigTimeoutTime_CVADAS" SG_ 616 Lane_DisplaySts_Right_LKA_VIP 0;
BA_ "GenSigSendType" SG_ 616 Lane_DisplaySts_Right_LKA_VIP 3;
BA_ "GenSigTimeoutTime_BSM" SG_ 616 Lane_DisplaySts_Right_LKA_VIP 0;
BA_ "GenSigTimeoutTime_BSM2" SG_ 616 Lane_DisplaySts_Right_LKA_VIP 0;
BA_ "GenSigTimeoutTime_EPS" SG_ 616 Lane_DisplaySts_Right_LKA_VIP 0;
BA_ "GenSigTimeoutTime_EVCU2" SG_ 616 Lane_DisplaySts_Right_LKA_VIP 0;
BA_ "GenSigTimeoutTime_ORC" SG_ 616 Lane_DisplaySts_Right_LKA_VIP 0;
BA_ "GenSigTimeoutTime_ADCAM" SG_ 616 Lane_DispPopupSts_VIP 0;
BA_ "GenSigTimeoutTime_CVADAS" SG_ 616 Lane_DispPopupSts_VIP 0;
BA_ "GenSigSendType" SG_ 616 Lane_DispPopupSts_VIP 3;
BA_ "GenSigTimeoutTime_BSM" SG_ 616 Lane_DispPopupSts_VIP 0;
BA_ "GenSigTimeoutTime_BSM2" SG_ 616 Lane_DispPopupSts_VIP 0;
BA_ "GenSigTimeoutTime_EPS" SG_ 616 Lane_DispPopupSts_VIP 0;
BA_ "GenSigTimeoutTime_EVCU2" SG_ 616 Lane_DispPopupSts_VIP 0;
BA_ "GenSigTimeoutTime_ORC" SG_ 616 Lane_DispPopupSts_VIP 0;
BA_ "GenSigTimeoutTime_ADCAM" SG_ 616 LKA_Status_VIP 0;
BA_ "GenSigTimeoutTime_CVADAS" SG_ 616 LKA_Status_VIP 0;
BA_ "GenSigSendType" SG_ 616 LKA_Status_VIP 3;
BA_ "GenSigTimeoutTime_BSM" SG_ 616 LKA_Status_VIP 0;
BA_ "GenSigTimeoutTime_BSM2" SG_ 616 LKA_Status_VIP 0;
BA_ "GenSigTimeoutTime_EPS" SG_ 616 LKA_Status_VIP 0;
BA_ "GenSigTimeoutTime_EVCU2" SG_ 616 LKA_Status_VIP 0;
BA_ "GenSigTimeoutTime_ORC" SG_ 616 LKA_Status_VIP 0;
BA_ "GenSigTimeoutTime_ADCAM" SG_ 616 DM_Camera_Block_VIP 0;
BA_ "GenSigTimeoutTime_CVADAS" SG_ 616 DM_Camera_Block_VIP 0;
BA_ "GenSigSendType" SG_ 616 DM_Camera_Block_VIP 3;
BA_ "GenSigTimeoutTime_BSM" SG_ 616 DM_Camera_Block_VIP 0;
BA_ "GenSigTimeoutTime_BSM2" SG_ 616 DM_Camera_Block_VIP 0;
BA_ "GenSigTimeoutTime_EPS" SG_ 616 DM_Camera_Block_VIP 0;
BA_ "GenSigTimeoutTime_EVCU2" SG_ 616 DM_Camera_Block_VIP 0;
BA_ "GenSigTimeoutTime_ORC" SG_ 616 DM_Camera_Block_VIP 0;
BA_ "GenSigTimeoutTime_ADCAM" SG_ 616 CRC_ADAS_FD_HMI_VIP 0;
BA_ "GenSigTimeoutTime_CVADAS" SG_ 616 CRC_ADAS_FD_HMI_VIP 0;
BA_ "GenSigTimeoutTime_BSM" SG_ 616 CRC_ADAS_FD_HMI_VIP 0;
BA_ "GenSigTimeoutTime_BSM2" SG_ 616 CRC_ADAS_FD_HMI_VIP 0;
BA_ "GenSigTimeoutTime_EPS" SG_ 616 CRC_ADAS_FD_HMI_VIP 0;
BA_ "GenSigTimeoutTime_EVCU2" SG_ 616 CRC_ADAS_FD_HMI_VIP 0;
BA_ "GenSigTimeoutTime_ORC" SG_ 616 CRC_ADAS_FD_HMI_VIP 0;
BA_ "GenSigTimeoutTime_ADCAM" SG_ 616 MessageCounter_ADAS_FD_HMI_VIP 0;
BA_ "GenSigTimeoutTime_CVADAS" SG_ 616 MessageCounter_ADAS_FD_HMI_VIP 0;
BA_ "GenSigTimeoutTime_BSM" SG_ 616 MessageCounter_ADAS_FD_HMI_VIP 0;
BA_ "GenSigTimeoutTime_BSM2" SG_ 616 MessageCounter_ADAS_FD_HMI_VIP 0;
BA_ "GenSigTimeoutTime_EPS" SG_ 616 MessageCounter_ADAS_FD_HMI_VIP 0;
BA_ "GenSigTimeoutTime_EVCU2" SG_ 616 MessageCounter_ADAS_FD_HMI_VIP 0;
BA_ "GenSigTimeoutTime_ORC" SG_ 616 MessageCounter_ADAS_FD_HMI_VIP 0;
BA_ "GenSigTimeoutTime_BSM" SG_ 1580 Motor1_RPM 0;
BA_ "GenSigTimeoutTime_BSM2" SG_ 1580 Motor1_RPM 0;
BA_ "GenSigTimeoutTime_CADM" SG_ 1580 Motor1_RPM 0;
BA_ "GenSigTimeoutTime_CVPAM" SG_ 1580 Motor1_RPM 0;
BA_ "GenSigTimeoutTime_ECM" SG_ 1580 Motor1_RPM 0;
BA_ "GenSigTimeoutTime_EPS" SG_ 1580 Motor1_RPM 0;
BA_ "GenSigTimeoutTime_EVCU2" SG_ 1580 Motor1_RPM 0;
BA_ "GenSigTimeoutTime_ORC" SG_ 1580 Motor1_RPM 0;
BA_ "GenSigTimeoutTime_MPAD" SG_ 1580 Motor1_RPM 0;
BA_ "GenSigTimeoutTime_ADCAM" SG_ 1580 Motor1_RPM 0;
BA_ "GenSigTimeoutTime_CVADAS" SG_ 1580 Motor1_RPM 0;
BA_ "GenSigStartValue" SG_ 1580 Motor1_RPM 32768;
BA_ "GenSigStartValue" SG_ 1580 Motor2_RPM 32768;
BA_ "GenSigTimeoutTime_BSM" SG_ 1580 Motor2_RPM 0;
BA_ "GenSigTimeoutTime_BSM2" SG_ 1580 Motor2_RPM 0;
BA_ "GenSigTimeoutTime_CADM" SG_ 1580 Motor2_RPM 0;
BA_ "GenSigTimeoutTime_CVPAM" SG_ 1580 Motor2_RPM 0;
BA_ "GenSigTimeoutTime_ECM" SG_ 1580 Motor2_RPM 0;
BA_ "GenSigTimeoutTime_EPS" SG_ 1580 Motor2_RPM 0;
BA_ "GenSigTimeoutTime_EVCU2" SG_ 1580 Motor2_RPM 0;
BA_ "GenSigTimeoutTime_ORC" SG_ 1580 Motor2_RPM 0;
BA_ "GenSigTimeoutTime_MPAD" SG_ 1580 Motor2_RPM 0;
BA_ "GenSigTimeoutTime_ADCAM" SG_ 1580 Motor2_RPM 0;
BA_ "GenSigTimeoutTime_CVADAS" SG_ 1580 Motor2_RPM 0;
BA_ "GenSigTimeoutTime_MPAD" SG_ 2654486592 CBV_bit2_1E384040 0;
BA_ "GenSigTimeoutTime_ADCAM" SG_ 2654486592 CBV_bit2_1E384040 0;
BA_ "GenSigTimeoutTime_CVADAS" SG_ 2654486592 CBV_bit2_1E384040 0;
BA_ "GenSigTimeoutTime_VDCM" SG_ 2654486592 CBV_bit2_1E384040 0;
BA_ "GenSigTimeoutTime_BSM" SG_ 2654486592 CBV_bit2_1E384040 0;
BA_ "GenSigTimeoutTime_BSM2" SG_ 2654486592 CBV_bit2_1E384040 0;
BA_ "GenSigTimeoutTime_CADM" SG_ 2654486592 CBV_bit2_1E384040 0;
BA_ "GenSigTimeoutTime_CVPAM" SG_ 2654486592 CBV_bit2_1E384040 0;
BA_ "GenSigTimeoutTime_ECM" SG_ 2654486592 CBV_bit2_1E384040 0;
BA_ "GenSigTimeoutTime_EPS" SG_ 2654486592 CBV_bit2_1E384040 0;
BA_ "GenSigTimeoutTime_EVCU2" SG_ 2654486592 CBV_bit2_1E384040 0;
BA_ "GenSigTimeoutTime_ORC" SG_ 2654486592 CBV_bit2_1E384040 0;
BA_ "GenSigTimeoutTime_MPAD" SG_ 2654486592 CBV_bit4_ActiveWakeupBit_1E384040 0;
BA_ "GenSigTimeoutTime_ADCAM" SG_ 2654486592 CBV_bit4_ActiveWakeupBit_1E384040 0;
BA_ "GenSigTimeoutTime_CVADAS" SG_ 2654486592 CBV_bit4_ActiveWakeupBit_1E384040 0;
BA_ "GenSigTimeoutTime_VDCM" SG_ 2654486592 CBV_bit4_ActiveWakeupBit_1E384040 0;
BA_ "GenSigTimeoutTime_BSM" SG_ 2654486592 CBV_bit4_ActiveWakeupBit_1E384040 0;
BA_ "GenSigTimeoutTime_BSM2" SG_ 2654486592 CBV_bit4_ActiveWakeupBit_1E384040 0;
BA_ "GenSigTimeoutTime_CADM" SG_ 2654486592 CBV_bit4_ActiveWakeupBit_1E384040 0;
BA_ "GenSigTimeoutTime_CVPAM" SG_ 2654486592 CBV_bit4_ActiveWakeupBit_1E384040 0;
BA_ "GenSigTimeoutTime_ECM" SG_ 2654486592 CBV_bit4_ActiveWakeupBit_1E384040 0;
BA_ "GenSigTimeoutTime_EPS" SG_ 2654486592 CBV_bit4_ActiveWakeupBit_1E384040 0;
BA_ "GenSigTimeoutTime_EVCU2" SG_ 2654486592 CBV_bit4_ActiveWakeupBit_1E384040 0;
BA_ "GenSigTimeoutTime_ORC" SG_ 2654486592 CBV_bit4_ActiveWakeupBit_1E384040 0;
BA_ "GenSigTimeoutTime_MPAD" SG_ 2654486592 CBV_bit3_NMCoordinatorBit_1E384040 0;
BA_ "GenSigTimeoutTime_ADCAM" SG_ 2654486592 CBV_bit3_NMCoordinatorBit_1E384040 0;
BA_ "GenSigTimeoutTime_CVADAS" SG_ 2654486592 CBV_bit3_NMCoordinatorBit_1E384040 0;
BA_ "GenSigTimeoutTime_VDCM" SG_ 2654486592 CBV_bit3_NMCoordinatorBit_1E384040 0;
BA_ "GenSigTimeoutTime_BSM" SG_ 2654486592 CBV_bit3_NMCoordinatorBit_1E384040 0;
BA_ "GenSigTimeoutTime_BSM2" SG_ 2654486592 CBV_bit3_NMCoordinatorBit_1E384040 0;
BA_ "GenSigTimeoutTime_CADM" SG_ 2654486592 CBV_bit3_NMCoordinatorBit_1E384040 0;
BA_ "GenSigTimeoutTime_CVPAM" SG_ 2654486592 CBV_bit3_NMCoordinatorBit_1E384040 0;
BA_ "GenSigTimeoutTime_ECM" SG_ 2654486592 CBV_bit3_NMCoordinatorBit_1E384040 0;
BA_ "GenSigTimeoutTime_EPS" SG_ 2654486592 CBV_bit3_NMCoordinatorBit_1E384040 0;
BA_ "GenSigTimeoutTime_EVCU2" SG_ 2654486592 CBV_bit3_NMCoordinatorBit_1E384040 0;
BA_ "GenSigTimeoutTime_ORC" SG_ 2654486592 CBV_bit3_NMCoordinatorBit_1E384040 0;
BA_ "GenSigTimeoutTime_MPAD" SG_ 2654486592 CBV_bit0_RepeatMessageRequestBit_1E384040 0;
BA_ "GenSigTimeoutTime_ADCAM" SG_ 2654486592 CBV_bit0_RepeatMessageRequestBit_1E384040 0;
BA_ "GenSigTimeoutTime_CVADAS" SG_ 2654486592 CBV_bit0_RepeatMessageRequestBit_1E384040 0;
BA_ "GenSigTimeoutTime_VDCM" SG_ 2654486592 CBV_bit0_RepeatMessageRequestBit_1E384040 0;
BA_ "GenSigTimeoutTime_BSM" SG_ 2654486592 CBV_bit0_RepeatMessageRequestBit_1E384040 0;
BA_ "GenSigTimeoutTime_BSM2" SG_ 2654486592 CBV_bit0_RepeatMessageRequestBit_1E384040 0;
BA_ "GenSigTimeoutTime_CADM" SG_ 2654486592 CBV_bit0_RepeatMessageRequestBit_1E384040 0;
BA_ "GenSigTimeoutTime_CVPAM" SG_ 2654486592 CBV_bit0_RepeatMessageRequestBit_1E384040 0;
BA_ "GenSigTimeoutTime_ECM" SG_ 2654486592 CBV_bit0_RepeatMessageRequestBit_1E384040 0;
BA_ "GenSigTimeoutTime_EPS" SG_ 2654486592 CBV_bit0_RepeatMessageRequestBit_1E384040 0;
BA_ "GenSigTimeoutTime_EVCU2" SG_ 2654486592 CBV_bit0_RepeatMessageRequestBit_1E384040 0;
BA_ "GenSigTimeoutTime_ORC" SG_ 2654486592 CBV_bit0_RepeatMessageRequestBit_1E384040 0;
BA_ "GenSigTimeoutTime_MPAD" SG_ 2654486592 CBV_bit7_1E384040 0;
BA_ "GenSigTimeoutTime_ADCAM" SG_ 2654486592 CBV_bit7_1E384040 0;
BA_ "GenSigTimeoutTime_CVADAS" SG_ 2654486592 CBV_bit7_1E384040 0;
BA_ "GenSigTimeoutTime_VDCM" SG_ 2654486592 CBV_bit7_1E384040 0;
BA_ "GenSigTimeoutTime_BSM" SG_ 2654486592 CBV_bit7_1E384040 0;
BA_ "GenSigTimeoutTime_BSM2" SG_ 2654486592 CBV_bit7_1E384040 0;
BA_ "GenSigTimeoutTime_CADM" SG_ 2654486592 CBV_bit7_1E384040 0;
BA_ "GenSigTimeoutTime_CVPAM" SG_ 2654486592 CBV_bit7_1E384040 0;
BA_ "GenSigTimeoutTime_ECM" SG_ 2654486592 CBV_bit7_1E384040 0;
BA_ "GenSigTimeoutTime_EPS" SG_ 2654486592 CBV_bit7_1E384040 0;
BA_ "GenSigTimeoutTime_EVCU2" SG_ 2654486592 CBV_bit7_1E384040 0;
BA_ "GenSigTimeoutTime_ORC" SG_ 2654486592 CBV_bit7_1E384040 0;
BA_ "GenSigTimeoutTime_MPAD" SG_ 2654486592 CBV_bit6_PartialNtwInfBit_1E384040 0;
BA_ "GenSigTimeoutTime_ADCAM" SG_ 2654486592 CBV_bit6_PartialNtwInfBit_1E384040 0;
BA_ "GenSigTimeoutTime_CVADAS" SG_ 2654486592 CBV_bit6_PartialNtwInfBit_1E384040 0;
BA_ "GenSigTimeoutTime_VDCM" SG_ 2654486592 CBV_bit6_PartialNtwInfBit_1E384040 0;
BA_ "GenSigTimeoutTime_BSM" SG_ 2654486592 CBV_bit6_PartialNtwInfBit_1E384040 0;
BA_ "GenSigTimeoutTime_BSM2" SG_ 2654486592 CBV_bit6_PartialNtwInfBit_1E384040 0;
BA_ "GenSigTimeoutTime_CADM" SG_ 2654486592 CBV_bit6_PartialNtwInfBit_1E384040 0;
BA_ "GenSigTimeoutTime_CVPAM" SG_ 2654486592 CBV_bit6_PartialNtwInfBit_1E384040 0;
BA_ "GenSigTimeoutTime_ECM" SG_ 2654486592 CBV_bit6_PartialNtwInfBit_1E384040 0;
BA_ "GenSigTimeoutTime_EPS" SG_ 2654486592 CBV_bit6_PartialNtwInfBit_1E384040 0;
BA_ "GenSigTimeoutTime_EVCU2" SG_ 2654486592 CBV_bit6_PartialNtwInfBit_1E384040 0;
BA_ "GenSigTimeoutTime_ORC" SG_ 2654486592 CBV_bit6_PartialNtwInfBit_1E384040 0;
BA_ "GenSigTimeoutTime_MPAD" SG_ 2654486592 CBV_bit5_1E384040 0;
BA_ "GenSigTimeoutTime_ADCAM" SG_ 2654486592 CBV_bit5_1E384040 0;
BA_ "GenSigTimeoutTime_CVADAS" SG_ 2654486592 CBV_bit5_1E384040 0;
BA_ "GenSigTimeoutTime_VDCM" SG_ 2654486592 CBV_bit5_1E384040 0;
BA_ "GenSigTimeoutTime_BSM" SG_ 2654486592 CBV_bit5_1E384040 0;
BA_ "GenSigTimeoutTime_BSM2" SG_ 2654486592 CBV_bit5_1E384040 0;
BA_ "GenSigTimeoutTime_CADM" SG_ 2654486592 CBV_bit5_1E384040 0;
BA_ "GenSigTimeoutTime_CVPAM" SG_ 2654486592 CBV_bit5_1E384040 0;
BA_ "GenSigTimeoutTime_ECM" SG_ 2654486592 CBV_bit5_1E384040 0;
BA_ "GenSigTimeoutTime_EPS" SG_ 2654486592 CBV_bit5_1E384040 0;
BA_ "GenSigTimeoutTime_EVCU2" SG_ 2654486592 CBV_bit5_1E384040 0;
BA_ "GenSigTimeoutTime_ORC" SG_ 2654486592 CBV_bit5_1E384040 0;
BA_ "GenSigTimeoutTime_MPAD" SG_ 2654486592 SourceNodeIdentifier_1E384040 0;
BA_ "GenSigTimeoutTime_ADCAM" SG_ 2654486592 SourceNodeIdentifier_1E384040 0;
BA_ "GenSigTimeoutTime_CVADAS" SG_ 2654486592 SourceNodeIdentifier_1E384040 0;
BA_ "GenSigTimeoutTime_VDCM" SG_ 2654486592 SourceNodeIdentifier_1E384040 0;
BA_ "GenSigTimeoutTime_BSM" SG_ 2654486592 SourceNodeIdentifier_1E384040 0;
BA_ "GenSigTimeoutTime_BSM2" SG_ 2654486592 SourceNodeIdentifier_1E384040 0;
BA_ "GenSigTimeoutTime_CADM" SG_ 2654486592 SourceNodeIdentifier_1E384040 0;
BA_ "GenSigTimeoutTime_CVPAM" SG_ 2654486592 SourceNodeIdentifier_1E384040 0;
BA_ "GenSigTimeoutTime_ECM" SG_ 2654486592 SourceNodeIdentifier_1E384040 0;
BA_ "GenSigTimeoutTime_EPS" SG_ 2654486592 SourceNodeIdentifier_1E384040 0;
BA_ "GenSigTimeoutTime_EVCU2" SG_ 2654486592 SourceNodeIdentifier_1E384040 0;
BA_ "GenSigTimeoutTime_ORC" SG_ 2654486592 SourceNodeIdentifier_1E384040 0;
BA_ "GenSigTimeoutTime_MPAD" SG_ 2654486592 CBV_bit1_1E384040 0;
BA_ "GenSigTimeoutTime_ADCAM" SG_ 2654486592 CBV_bit1_1E384040 0;
BA_ "GenSigTimeoutTime_CVADAS" SG_ 2654486592 CBV_bit1_1E384040 0;
BA_ "GenSigTimeoutTime_VDCM" SG_ 2654486592 CBV_bit1_1E384040 0;
BA_ "GenSigTimeoutTime_BSM" SG_ 2654486592 CBV_bit1_1E384040 0;
BA_ "GenSigTimeoutTime_BSM2" SG_ 2654486592 CBV_bit1_1E384040 0;
BA_ "GenSigTimeoutTime_CADM" SG_ 2654486592 CBV_bit1_1E384040 0;
BA_ "GenSigTimeoutTime_CVPAM" SG_ 2654486592 CBV_bit1_1E384040 0;
BA_ "GenSigTimeoutTime_ECM" SG_ 2654486592 CBV_bit1_1E384040 0;
BA_ "GenSigTimeoutTime_EPS" SG_ 2654486592 CBV_bit1_1E384040 0;
BA_ "GenSigTimeoutTime_EVCU2" SG_ 2654486592 CBV_bit1_1E384040 0;
BA_ "GenSigTimeoutTime_ORC" SG_ 2654486592 CBV_bit1_1E384040 0;
BA_ "GenSigTimeoutTime_MPAD" SG_ 263 RawPVS1_PT 0;
BA_ "GenSigTimeoutTime_ADCAM" SG_ 263 RawPVS1_PT 0;
BA_ "GenSigTimeoutTime_CVADAS" SG_ 263 RawPVS1_PT 0;
BA_ "GenSigStartValue" SG_ 263 RawPVS1_PT 255;
BA_ "GenSigTimeoutTime_BSM" SG_ 263 RawPVS1_PT 0;
BA_ "GenSigTimeoutTime_BSM2" SG_ 263 RawPVS1_PT 0;
BA_ "GenSigTimeoutTime_EPS" SG_ 263 RawPVS1_PT 0;
BA_ "GenSigTimeoutTime_MPAD" SG_ 263 RawPVS2_PT 0;
BA_ "GenSigTimeoutTime_ADCAM" SG_ 263 RawPVS2_PT 0;
BA_ "GenSigTimeoutTime_CVADAS" SG_ 263 RawPVS2_PT 0;
BA_ "GenSigStartValue" SG_ 263 RawPVS2_PT 255;
BA_ "GenSigTimeoutTime_BSM" SG_ 263 RawPVS2_PT 0;
BA_ "GenSigTimeoutTime_BSM2" SG_ 263 RawPVS2_PT 0;
BA_ "GenSigTimeoutTime_EPS" SG_ 263 RawPVS2_PT 0;
BA_ "GenSigTimeoutTime_EVCU2" SG_ 263 RawPVS2_PT 0;
BA_ "GenSigTimeoutTime_ORC" SG_ 263 RawPVS2_PT 0;
BA_ "GenSigTimeoutTime_BSM" SG_ 263 EVCU2_THA_Resp 0;
BA_ "GenSigTimeoutTime_BSM2" SG_ 263 EVCU2_THA_Resp 0;
BA_ "GenSigTimeoutTime_CADM" SG_ 263 EVCU2_THA_Resp 0;
BA_ "GenSigTimeoutTime_ECM" SG_ 263 EVCU2_THA_Resp 0;
BA_ "GenSigTimeoutTime_EPS" SG_ 263 EVCU2_THA_Resp 0;
BA_ "GenSigTimeoutTime_EVCU2" SG_ 263 EVCU2_THA_Resp 0;
BA_ "GenSigTimeoutTime_ORC" SG_ 263 EVCU2_THA_Resp 0;
BA_ "GenSigTimeoutTime_EVCU2" SG_ 263 RawPVS1_PT 0;
BA_ "GenSigTimeoutTime_ORC" SG_ 263 RawPVS1_PT 0;
BA_ "GenSigTimeoutTime_MPAD" SG_ 263 DriveReady_PT 0;
BA_ "GenSigTimeoutTime_ADCAM" SG_ 263 DriveReady_PT 0;
BA_ "GenSigTimeoutTime_CVADAS" SG_ 263 DriveReady_PT 0;
BA_ "GenSigTimeoutTime_VDCM" SG_ 263 DriveReady_PT 0;
BA_ "GenSigTimeoutTime_BSM" SG_ 263 DriveReady_PT 0;
BA_ "GenSigTimeoutTime_BSM2" SG_ 263 DriveReady_PT 0;
BA_ "GenSigTimeoutTime_CADM" SG_ 263 DriveReady_PT 0;
BA_ "GenSigTimeoutTime_CVPAM" SG_ 263 DriveReady_PT 0;
BA_ "GenSigTimeoutTime_ECM" SG_ 263 DriveReady_PT 0;
BA_ "GenSigTimeoutTime_EPS" SG_ 263 DriveReady_PT 0;
BA_ "GenSigTimeoutTime_EVCU2" SG_ 263 DriveReady_PT 0;
BA_ "GenSigTimeoutTime_ORC" SG_ 263 DriveReady_PT 0;
BA_ "GenSigTimeoutTime_MPAD" SG_ 263 GearEngaged_PT 0;
BA_ "GenSigTimeoutTime_ADCAM" SG_ 263 GearEngaged_PT 0;
BA_ "GenSigTimeoutTime_CVADAS" SG_ 263 GearEngaged_PT 0;
BA_ "GenSigTimeoutTime_VDCM" SG_ 263 GearEngaged_PT 0;
BA_ "GenSigTimeoutTime_EPS" SG_ 263 GearEngaged_PT 0;
BA_ "GenSigTimeoutTime_BSM" SG_ 263 GearEngaged_PT 0;
BA_ "GenSigTimeoutTime_BSM2" SG_ 263 GearEngaged_PT 0;
BA_ "GenSigTimeoutTime_CADM" SG_ 263 GearEngaged_PT 0;
BA_ "GenSigTimeoutTime_CVPAM" SG_ 263 GearEngaged_PT 0;
BA_ "GenSigTimeoutTime_ECM" SG_ 263 GearEngaged_PT 0;
BA_ "GenSigTimeoutTime_EVCU2" SG_ 263 GearEngaged_PT 0;
BA_ "GenSigTimeoutTime_ORC" SG_ 263 GearEngaged_PT 0;
BA_ "GenSigTimeoutTime_MPAD" SG_ 263 ShiftLeverPosition_PT 0;
BA_ "GenSigTimeoutTime_CVADAS" SG_ 263 ShiftLeverPosition_PT 0;
BA_ "GenSigTimeoutTime_VDCM" SG_ 263 ShiftLeverPosition_PT 0;
BA_ "GenSigTimeoutTime_BSM" SG_ 263 ShiftLeverPosition_PT 0;
BA_ "GenSigTimeoutTime_BSM2" SG_ 263 ShiftLeverPosition_PT 0;
BA_ "GenSigTimeoutTime_CADM" SG_ 263 ShiftLeverPosition_PT 0;
BA_ "GenSigTimeoutTime_ECM" SG_ 263 ShiftLeverPosition_PT 0;
BA_ "GenSigTimeoutTime_EPS" SG_ 263 ShiftLeverPosition_PT 0;
BA_ "GenSigTimeoutTime_EVCU2" SG_ 263 ShiftLeverPosition_PT 0;
BA_ "GenSigTimeoutTime_ORC" SG_ 263 ShiftLeverPosition_PT 0;
BA_ "GenSigTimeoutTime_MPAD" SG_ 263 SpeedLimitSts_PT 0;
BA_ "GenSigTimeoutTime_ADCAM" SG_ 263 SpeedLimitSts_PT 0;
BA_ "GenSigTimeoutTime_CVADAS" SG_ 263 SpeedLimitSts_PT 0;
BA_ "GenSigTimeoutTime_BSM" SG_ 263 SpeedLimitSts_PT 0;
BA_ "GenSigTimeoutTime_BSM2" SG_ 263 SpeedLimitSts_PT 0;
BA_ "GenSigTimeoutTime_ECM" SG_ 263 SpeedLimitSts_PT 0;
BA_ "GenSigTimeoutTime_EPS" SG_ 263 SpeedLimitSts_PT 0;
BA_ "GenSigTimeoutTime_EVCU2" SG_ 263 SpeedLimitSts_PT 0;
BA_ "GenSigTimeoutTime_ORC" SG_ 263 SpeedLimitSts_PT 0;
BA_ "GenSigTimeoutTime_MPAD" SG_ 263 TargetGear_PT 0;
BA_ "GenSigTimeoutTime_ADCAM" SG_ 263 TargetGear_PT 0;
BA_ "GenSigTimeoutTime_CVADAS" SG_ 263 TargetGear_PT 0;
BA_ "GenSigTimeoutTime_VDCM" SG_ 263 TargetGear_PT 0;
BA_ "GenSigTimeoutTime_BSM" SG_ 263 TargetGear_PT 0;
BA_ "GenSigTimeoutTime_BSM2" SG_ 263 TargetGear_PT 0;
BA_ "GenSigTimeoutTime_CADM" SG_ 263 TargetGear_PT 0;
BA_ "GenSigTimeoutTime_CVPAM" SG_ 263 TargetGear_PT 0;
BA_ "GenSigTimeoutTime_ECM" SG_ 263 TargetGear_PT 0;
BA_ "GenSigTimeoutTime_EPS" SG_ 263 TargetGear_PT 0;
BA_ "GenSigTimeoutTime_EVCU2" SG_ 263 TargetGear_PT 0;
BA_ "GenSigTimeoutTime_ORC" SG_ 263 TargetGear_PT 0;
BA_ "GenSigTimeoutTime_ADCAM" SG_ 263 CRC_PT_SYSTEM_FD_1 0;
BA_ "GenSigTimeoutTime_CVADAS" SG_ 263 CRC_PT_SYSTEM_FD_1 0;
BA_ "GenSigTimeoutTime_VDCM" SG_ 263 CRC_PT_SYSTEM_FD_1 0;
BA_ "GenSigTimeoutTime_BSM" SG_ 263 CRC_PT_SYSTEM_FD_1 0;
BA_ "GenSigTimeoutTime_BSM2" SG_ 263 CRC_PT_SYSTEM_FD_1 0;
BA_ "GenSigTimeoutTime_CADM" SG_ 263 CRC_PT_SYSTEM_FD_1 0;
BA_ "GenSigTimeoutTime_CVPAM" SG_ 263 CRC_PT_SYSTEM_FD_1 0;
BA_ "GenSigTimeoutTime_EPS" SG_ 263 CRC_PT_SYSTEM_FD_1 0;
BA_ "GenSigTimeoutTime_EVCU2" SG_ 263 CRC_PT_SYSTEM_FD_1 0;
BA_ "GenSigTimeoutTime_ORC" SG_ 263 CRC_PT_SYSTEM_FD_1 0;
BA_ "GenSigTimeoutTime_MPAD" SG_ 263 GasPedalPosition_PT 0;
BA_ "GenSigTimeoutTime_ADCAM" SG_ 263 GasPedalPosition_PT 0;
BA_ "GenSigTimeoutTime_CVADAS" SG_ 263 GasPedalPosition_PT 0;
BA_ "GenSigTimeoutTime_VDCM" SG_ 263 GasPedalPosition_PT 0;
BA_ "GenSigTimeoutTime_BSM2" SG_ 263 GasPedalPosition_PT 0;
BA_ "GenSigTimeoutTime_CADM" SG_ 263 GasPedalPosition_PT 0;
BA_ "GenSigTimeoutTime_CVPAM" SG_ 263 GasPedalPosition_PT 0;
BA_ "GenSigTimeoutTime_ECM" SG_ 263 GasPedalPosition_PT 0;
BA_ "GenSigTimeoutTime_EPS" SG_ 263 GasPedalPosition_PT 0;
BA_ "GenSigTimeoutTime_EVCU2" SG_ 263 GasPedalPosition_PT 0;
BA_ "GenSigTimeoutTime_ORC" SG_ 263 GasPedalPosition_PT 0;
BA_ "GenSigTimeoutTime_MPAD" SG_ 263 GasPedalPositionFailSts_PT 0;
BA_ "GenSigTimeoutTime_ADCAM" SG_ 263 GasPedalPositionFailSts_PT 0;
BA_ "GenSigTimeoutTime_CVADAS" SG_ 263 GasPedalPositionFailSts_PT 0;
BA_ "GenSigTimeoutTime_VDCM" SG_ 263 GasPedalPositionFailSts_PT 0;
BA_ "GenSigTimeoutTime_BSM" SG_ 263 GasPedalPositionFailSts_PT 0;
BA_ "GenSigTimeoutTime_BSM2" SG_ 263 GasPedalPositionFailSts_PT 0;
BA_ "GenSigTimeoutTime_CVPAM" SG_ 263 GasPedalPositionFailSts_PT 0;
BA_ "GenSigTimeoutTime_ECM" SG_ 263 GasPedalPositionFailSts_PT 0;
BA_ "GenSigTimeoutTime_EPS" SG_ 263 GasPedalPositionFailSts_PT 0;
BA_ "GenSigTimeoutTime_EVCU2" SG_ 263 GasPedalPositionFailSts_PT 0;
BA_ "GenSigTimeoutTime_ORC" SG_ 263 GasPedalPositionFailSts_PT 0;
BA_ "GenSigTimeoutTime_MPAD" SG_ 263 ISASts_PT 0;
BA_ "GenSigTimeoutTime_ADCAM" SG_ 263 ISASts_PT 0;
BA_ "GenSigTimeoutTime_CVADAS" SG_ 263 ISASts_PT 0;
BA_ "GenSigTimeoutTime_BSM" SG_ 263 ISASts_PT 0;
BA_ "GenSigTimeoutTime_BSM2" SG_ 263 ISASts_PT 0;
BA_ "GenSigTimeoutTime_ECM" SG_ 263 ISASts_PT 0;
BA_ "GenSigTimeoutTime_EPS" SG_ 263 ISASts_PT 0;
BA_ "GenSigTimeoutTime_EVCU2" SG_ 263 ISASts_PT 0;
BA_ "GenSigTimeoutTime_ORC" SG_ 263 ISASts_PT 0;
BA_ "GenSigTimeoutTime_ADCAM" SG_ 263 MessageCounter_PT_SYSTEM_FD_1 0;
BA_ "GenSigTimeoutTime_CVADAS" SG_ 263 MessageCounter_PT_SYSTEM_FD_1 0;
BA_ "GenSigTimeoutTime_VDCM" SG_ 263 MessageCounter_PT_SYSTEM_FD_1 0;
BA_ "GenSigTimeoutTime_BSM" SG_ 263 MessageCounter_PT_SYSTEM_FD_1 0;
BA_ "GenSigTimeoutTime_BSM2" SG_ 263 MessageCounter_PT_SYSTEM_FD_1 0;
BA_ "GenSigTimeoutTime_CADM" SG_ 263 MessageCounter_PT_SYSTEM_FD_1 0;
BA_ "GenSigTimeoutTime_CVPAM" SG_ 263 MessageCounter_PT_SYSTEM_FD_1 0;
BA_ "GenSigTimeoutTime_EPS" SG_ 263 MessageCounter_PT_SYSTEM_FD_1 0;
BA_ "GenSigTimeoutTime_EVCU2" SG_ 263 MessageCounter_PT_SYSTEM_FD_1 0;
BA_ "GenSigTimeoutTime_ORC" SG_ 263 MessageCounter_PT_SYSTEM_FD_1 0;
BA_ "GenSigTimeoutTime_ADCAM" SG_ 263 PdlPosActual_PT 0;
BA_ "GenSigTimeoutTime_CVADAS" SG_ 263 PdlPosActual_PT 0;
BA_ "GenSigTimeoutTime_VDCM" SG_ 263 PdlPosActual_PT 0;
BA_ "GenSigTimeoutTime_BSM" SG_ 263 PdlPosActual_PT 0;
BA_ "GenSigTimeoutTime_ECM" SG_ 263 PdlPosActual_PT 0;
BA_ "GenSigTimeoutTime_EPS" SG_ 263 PdlPosActual_PT 0;
BA_ "GenSigTimeoutTime_EVCU2" SG_ 263 PdlPosActual_PT 0;
BA_ "GenSigTimeoutTime_ORC" SG_ 263 PdlPosActual_PT 0;
BA_ "GenSigTimeoutTime_MPAD" SG_ 263 GearEngagedForDisplay_PT 0;
BA_ "GenSigTimeoutTime_ADCAM" SG_ 263 GearEngagedForDisplay_PT 0;
BA_ "GenSigTimeoutTime_CVADAS" SG_ 263 GearEngagedForDisplay_PT 0;
BA_ "GenSigTimeoutTime_BSM" SG_ 263 GearEngagedForDisplay_PT 0;
BA_ "GenSigTimeoutTime_BSM2" SG_ 263 GearEngagedForDisplay_PT 0;
BA_ "GenSigTimeoutTime_CADM" SG_ 263 GearEngagedForDisplay_PT 0;
BA_ "GenSigTimeoutTime_CVPAM" SG_ 263 GearEngagedForDisplay_PT 0;
BA_ "GenSigTimeoutTime_ECM" SG_ 263 GearEngagedForDisplay_PT 0;
BA_ "GenSigTimeoutTime_EPS" SG_ 263 GearEngagedForDisplay_PT 0;
BA_ "GenSigTimeoutTime_EVCU2" SG_ 263 GearEngagedForDisplay_PT 0;
BA_ "GenSigTimeoutTime_ORC" SG_ 263 GearEngagedForDisplay_PT 0;
BA_ "GenSigTimeoutTime_ADCAM" SG_ 263 PowertrainPrplsnActv_PT 0;
BA_ "GenSigTimeoutTime_CVADAS" SG_ 263 PowertrainPrplsnActv_PT 0;
BA_ "GenSigTimeoutTime_VDCM" SG_ 263 PowertrainPrplsnActv_PT 0;
BA_ "GenSigTimeoutTime_BSM2" SG_ 263 PowertrainPrplsnActv_PT 0;
BA_ "GenSigTimeoutTime_CVPAM" SG_ 263 PowertrainPrplsnActv_PT 0;
BA_ "GenSigTimeoutTime_ECM" SG_ 263 PowertrainPrplsnActv_PT 0;
BA_ "GenSigTimeoutTime_EPS" SG_ 263 PowertrainPrplsnActv_PT 0;
BA_ "GenSigTimeoutTime_EVCU2" SG_ 263 PowertrainPrplsnActv_PT 0;
BA_ "GenSigTimeoutTime_ORC" SG_ 263 PowertrainPrplsnActv_PT 0;
BA_ "GenSigStartValue" SG_ 299 ACC_Axle_Torque 32768;
BA_ "GenSigTimeoutTime_BSM2" SG_ 299 ACC_Axle_Torque 0;
BA_ "GenSigTimeoutTime_CADM" SG_ 299 ACC_Axle_Torque 0;
BA_ "GenSigTimeoutTime_CVPAM" SG_ 299 ACC_Axle_Torque 0;
BA_ "GenSigTimeoutTime_ECM" SG_ 299 ACC_Axle_Torque 0;
BA_ "GenSigTimeoutTime_EPS" SG_ 299 ACC_Axle_Torque 0;
BA_ "GenSigTimeoutTime_EVCU2" SG_ 299 ACC_Axle_Torque 0;
BA_ "GenSigTimeoutTime_ORC" SG_ 299 ACC_Axle_Torque 0;
BA_ "GenSigTimeoutTime_MPAD" SG_ 299 ACC_Axle_Torque 0;
BA_ "GenSigTimeoutTime_ADCAM" SG_ 299 ACC_Axle_Torque 0;
BA_ "GenSigTimeoutTime_CVADAS" SG_ 299 ACC_Axle_Torque 0;
BA_ "GenSigTimeoutTime_VDCM" SG_ 299 ACC_Axle_Torque 0;
BA_ "GenSigTimeoutTime_EPS" SG_ 299 ACC_Axle_Torque_Enabled 0;
BA_ "GenSigTimeoutTime_EVCU2" SG_ 299 ACC_Axle_Torque_Enabled 0;
BA_ "GenSigTimeoutTime_ORC" SG_ 299 ACC_Axle_Torque_Enabled 0;
BA_ "GenSigTimeoutTime_MPAD" SG_ 299 ACC_Axle_Torque_Enabled 0;
BA_ "GenSigTimeoutTime_ADCAM" SG_ 299 ACC_Axle_Torque_Enabled 0;
BA_ "GenSigTimeoutTime_CVADAS" SG_ 299 ACC_Axle_Torque_Enabled 0;
BA_ "GenSigTimeoutTime_VDCM" SG_ 299 ACC_Axle_Torque_Enabled 0;
BA_ "GenSigTimeoutTime_BSM2" SG_ 299 ACC_Axle_Torque_Enabled 0;
BA_ "GenSigTimeoutTime_CADM" SG_ 299 ACC_Axle_Torque_Enabled 0;
BA_ "GenSigTimeoutTime_CVPAM" SG_ 299 ACC_Axle_Torque_Enabled 0;
BA_ "GenSigTimeoutTime_ECM" SG_ 299 ACC_Axle_Torque_Enabled 0;
BA_ "GenSigTimeoutTime_ADCAM" SG_ 299 CRC_ADAS_FD_INFO3 0;
BA_ "GenSigTimeoutTime_CVADAS" SG_ 299 CRC_ADAS_FD_INFO3 0;
BA_ "GenSigTimeoutTime_BSM2" SG_ 299 CRC_ADAS_FD_INFO3 0;
BA_ "GenSigTimeoutTime_CADM" SG_ 299 CRC_ADAS_FD_INFO3 0;
BA_ "GenSigTimeoutTime_CVPAM" SG_ 299 CRC_ADAS_FD_INFO3 0;
BA_ "GenSigTimeoutTime_ECM" SG_ 299 CRC_ADAS_FD_INFO3 0;
BA_ "GenSigTimeoutTime_EPS" SG_ 299 CRC_ADAS_FD_INFO3 0;
BA_ "GenSigTimeoutTime_EVCU2" SG_ 299 CRC_ADAS_FD_INFO3 0;
BA_ "GenSigTimeoutTime_ORC" SG_ 299 CRC_ADAS_FD_INFO3 0;
BA_ "GenSigTimeoutTime_ADCAM" SG_ 299 MessageCounter_ADAS_FD_INFO3 0;
BA_ "GenSigTimeoutTime_CVADAS" SG_ 299 MessageCounter_ADAS_FD_INFO3 0;
BA_ "GenSigTimeoutTime_BSM2" SG_ 299 MessageCounter_ADAS_FD_INFO3 0;
BA_ "GenSigTimeoutTime_CADM" SG_ 299 MessageCounter_ADAS_FD_INFO3 0;
BA_ "GenSigTimeoutTime_CVPAM" SG_ 299 MessageCounter_ADAS_FD_INFO3 0;
BA_ "GenSigTimeoutTime_ECM" SG_ 299 MessageCounter_ADAS_FD_INFO3 0;
BA_ "GenSigTimeoutTime_EPS" SG_ 299 MessageCounter_ADAS_FD_INFO3 0;
BA_ "GenSigTimeoutTime_EVCU2" SG_ 299 MessageCounter_ADAS_FD_INFO3 0;
BA_ "GenSigTimeoutTime_ORC" SG_ 299 MessageCounter_ADAS_FD_INFO3 0;
BA_ "GenSigSendType" SG_ 263 EVCU2_TRSC_Resp 4;
BA_ "GenSigTimeoutTime_BSM" SG_ 263 EVCU2_TRSC_Resp 0;
BA_ "GenSigTimeoutTime_BSM2" SG_ 263 EVCU2_TRSC_Resp 0;
BA_ "GenSigTimeoutTime_CADM" SG_ 263 EVCU2_TRSC_Resp 0;
BA_ "GenSigTimeoutTime_ECM" SG_ 263 EVCU2_TRSC_Resp 0;
BA_ "GenSigTimeoutTime_EPS" SG_ 263 EVCU2_TRSC_Resp 0;
BA_ "GenSigTimeoutTime_EVCU2" SG_ 263 EVCU2_TRSC_Resp 0;
BA_ "GenSigTimeoutTime_ORC" SG_ 263 EVCU2_TRSC_Resp 0;
BA_ "GenSigTimeoutTime_MPAD" SG_ 263 Propulsion_ADAS_Inhibit 0;
BA_ "GenSigTimeoutTime_ADCAM" SG_ 263 Propulsion_ADAS_Inhibit 0;
BA_ "GenSigStartValue" SG_ 263 Propulsion_ADAS_Inhibit 1;
BA_ "GenSigTimeoutTime_BSM" SG_ 263 Propulsion_ADAS_Inhibit 0;
BA_ "GenSigTimeoutTime_BSM2" SG_ 263 Propulsion_ADAS_Inhibit 0;
BA_ "GenSigTimeoutTime_CADM" SG_ 263 Propulsion_ADAS_Inhibit 0;
BA_ "GenSigTimeoutTime_ECM" SG_ 263 Propulsion_ADAS_Inhibit 0;
BA_ "GenSigTimeoutTime_EPS" SG_ 263 Propulsion_ADAS_Inhibit 0;
BA_ "GenSigTimeoutTime_EVCU2" SG_ 263 Propulsion_ADAS_Inhibit 0;
BA_ "GenSigTimeoutTime_ORC" SG_ 263 Propulsion_ADAS_Inhibit 0;
BA_ "GenSigTimeoutTime_MPAD" SG_ 299 ACC_TORSts 0;
BA_ "GenSigTimeoutTime_CVADAS" SG_ 299 ACC_TORSts 0;
BA_ "GenSigTimeoutTime_BSM" SG_ 299 ACC_TORSts 0;
BA_ "GenSigTimeoutTime_BSM2" SG_ 299 ACC_TORSts 0;
BA_ "GenSigTimeoutTime_EPS" SG_ 299 ACC_TORSts 0;
BA_ "GenSigTimeoutTime_EVCU2" SG_ 299 ACC_TORSts 0;
BA_ "GenSigTimeoutTime_ORC" SG_ 299 ACC_TORSts 0;
VAL_ 299 ACC_Axle_Torque 65535 "SNA";
VAL_ 263 TargetGear_PT 0 "Neutral" 1 "ForwardGear_1" 2 "ForwardGear_2" 3 "ForwardGear_3" 4 "ForwardGear_4" 5 "ForwardGear_5" 6 "ForwardGear_6" 7 "ForwardGear_7" 8 "ForwardGear_8" 9 "ForwardGear_9" 13 "Parking" 14 "ReverseGear" 15 "SNA";
VAL_ 263 SpeedLimitSts_PT 0 "Standby" 1 "Activated" 2 "Not_Actuable" 3 "Override" 4 "Overspeed" 5 "Deactivated" 6 "Off" 7 "SNA";
VAL_ 263 ShiftLeverPosition_PT 0 "No_Selection_Active_Or_Available" 1 "Park" 2 "Reverse" 3 "Neutral" 4 "Drive" 5 "Low" 6 "TIP_Autostick" 7 "Plus" 8 "Minus" 9 "Sport" 15 "SNA";
VAL_ 263 PdlPosActual_PT 255 "SNA";
VAL_ 263 ISASts_PT 0 "Not_Active" 1 "Active";
VAL_ 263 GasPedalPositionFailSts_PT 0 "Fail_not_present" 1 "Fail_present";
VAL_ 263 PowertrainPrplsnActv_PT 0 "Not_Active" 1 "Active";
VAL_ 263 GearEngagedForDisplay_PT 0 "Initialize" 1 "Gear_1st" 2 "Gear_2nd" 3 "Gear_3rd" 4 "Gear_4th" 5 "Gear_5th" 6 "Gear_6th" 7 "Gear_7th" 8 "Gear_8th" 9 "Gear_9th" 12 "Park" 13 "Neutral" 14 "Reverse" 15 "Drive" 16 "Low" 17 "Manual" 18 "Sport_Mode" 31 "SNA";
VAL_ 263 GearEngaged_PT 0 "Neutral" 1 "ForwardGear_1" 2 "ForwardGear_2" 3 "ForwardGear_3" 4 "ForwardGear_4" 5 "ForwardGear_5" 6 "ForwardGear_6" 7 "ForwardGear_7" 8 "ForwardGear_8" 9 "ForwardGear_9" 13 "Parking" 14 "ReverseGear" 15 "SNA";
VAL_ 263 DriveReady_PT 0 "Default" 1 "Veh_Allwd_Shift_Out_Of_P_Or_N";
VAL_ 263 GasPedalPosition_PT 255 "SNA";
VAL_ 616 Set_Speed_MPH_VIP 255 "SNA";
VAL_ 616 Set_Speed_KPH_VIP 255 "SNA";
VAL_ 616 LKA_LEDControlSts_VIP 0 "OFF" 1 "CONT" 2 "BLINK" 3 "SNA";
VAL_ 97 GTS_Type 16 "SYNC" 24 "FUP" 32 "SYNC_CRC" 40 "FUP_CRC" 48 "OFS" 56 "OFNS" 64 "OFS_CRC" 72 "OFNS_CRC" 84 "OFS_FD" 100 "OFS_FD_CRC";
VAL_ 210 ACC_Axle_Torque_VIP 65535 "SNA";
VAL_ 299 ACC_Axle_Torque_Enabled 0 "Not_Enabled" 1 "Enabled";
VAL_ 209 SteeringVibration_Type_VIP 0 "TYPE_0" 1 "TYPE_1" 2 "TYPE_2" 3 "TYPE_3" 4 "TYPE_4" 5 "TYPE_5" 6 "TYPE_6" 7 "TYPE_7" 8 "TYPE_8" 9 "TYPE_9" 10 "TYPE_10" 11 "TYPE_11" 15 "SNA";
VAL_ 209 SteeringVibration_Rq_VIP 0 "NOT_REQUESTED" 1 "REQUESTED";
VAL_ 209 Prefill_Req_VIP 0 "No_Prefill_Requested" 1 "Prefill_Requested";
VAL_ 209 PEB_SystemSts_VIP 0 "OFF" 1 "ON";
VAL_ 209 Object_Dist_VIP 255 "SNA";
VAL_ 209 LKA_LAT_CTRL_RequestSts_VIP 0 "Idle" 1 "Faulted" 2 "LKA_Request";
VAL_ 209 LC_Jerk_VIP 0 "Not_Active" 1 "Active";
VAL_ 209 Intervention_VIP 4095 "SNA";
VAL_ 209 GrMax_Rq_ACC_VIP 0 "Passive" 1 "G1" 2 "G2" 3 "G3" 4 "G4" 5 "G5" 6 "G6" 7 "G7" 8 "G8" 9 "G9" 10 "G10" 11 "G11" 12 "G12" 13 "G13" 14 "G14" 15 "G15";
VAL_ 209 DDD_SystemSts_VIP 0 "OFF" 1 "ON";
VAL_ 209 DDD_Setting_Avail_VIP 0 "Available" 1 "Not_Available";
VAL_ 209 CIPV_Fused_VIP 0 "Not_Active" 1 "Active";
VAL_ 209 Brake_Jerk_Req_VIP 0 "Not_Active" 1 "Active";
VAL_ 209 AEB_Type_VIP 0 "NONE" 1 "ACC" 2 "CMS" 3 "CMS_XTD" 4 "ABA" 5 "LSCM" 6 "PEB" 7 "ICA_L" 8 "ICA_R" 9 "HAS_MRM" 10 "RRCC" 11 "L3" 15 "SNA";
VAL_ 209 AEB_Systemsts_VIP 0 "FCW_Off" 1 "FCW_On_Only_Warning" 2 "FCW_On_Full";
VAL_ 209 AEB_Sensitivity_Setting_VIP 0 "NEAR" 1 "MEDIUM" 2 "FAR";
VAL_ 209 ACC_Systemsts_VIP 0 "OFF" 1 "ACC_Enabled" 2 "ACC_Engaged" 3 "ACC_Engaged_BrakeOnly" 4 "ACC_Cancel" 5 "NCC_Enabled" 6 "NCC_Engaged" 7 "NCC_Cancel" 8 "HAS_BSoC" 9 "RRCC_Enabled_No_Set_Speed" 10 "RRCC_Enabled_With_Set_Speed" 11 "RRCC_Engaged" 15 "SNA";
VAL_ 209 ACC_Engine_Torque_Enabled_VIP 0 "Not_Enabled" 1 "Enabled";
VAL_ 209 ACC_DsrSpeedKPH_VIP 255 "SNA";
VAL_ 616 RR_Chime_RqSts_VIP 0 "No_rght_rear_chime_on_req" 1 "Right_rear_chime_on_req";
VAL_ 616 PEB_Setting_Avail_VIP 0 "Available" 1 "Not_Available";
VAL_ 616 LR_Chime_RqSts_VIP 0 "No_left_rear_chime_on_req" 1 "Left_rear_chime_on_req";
VAL_ 616 LKA_FailSts_VIP 0 "Fail_Not_Present" 1 "Fail_Present";
VAL_ 616 LKA_Blind_VIP 0 "Fail_Not_Present" 1 "Fail_Present";
VAL_ 616 ICA_Blind_VIP 0 "Blinded" 1 "Not_Blinded";
VAL_ 616 FCW_Setting_Avail_VIP 0 "Available" 1 "Not_Available";
VAL_ 616 DDD_FailSts_VIP 0 "Fail_Not_Present" 1 "Fail_Present";
VAL_ 616 DDD_DispPopupSts_VIP 0 "No_Code" 1 "Drowsniness_Detected" 2 "DDD_Perm_Fail" 3 "SNA";
VAL_ 616 BSS_TrailerSts_VIP 0 "NONE" 1 "TRAILER_AUTO" 2 "TRAILER_MAX" 3 "TRAILER_0_3" 4 "TRAILER_3_6" 5 "TRAILER_6_9" 6 "MAX" 7 "SNA";
VAL_ 616 BSS_SRV_RQSts_VIP 0 "No_Service_Request" 1 "Service_Request";
VAL_ 616 BSS_DispPopoupSts_VIP 0 "No_Req" 1 "BSS_Trailer_On" 7 "SNA";
VAL_ 616 BSS_CFG_STATSts_VIP 0 "Not_enabled" 1 "Enabled_for_LED" 2 "Enabled_for_LED_and_Chime" 3 "SNA";
VAL_ 616 BSS_Blind_RQSts_VIP 0 "No_Sensor_Blocked_Request" 1 "Sensor_Blocked_Request";
VAL_ 616 BlindSpotRightWarn_VIP 0 "No_Req" 1 "Solid" 2 "Flashing";
VAL_ 616 BlindSpotLeftWarn_VIP 0 "No_Req" 1 "Solid" 2 "Flashing";
VAL_ 616 AEB_Limited_VIP 0 "Fail_Not_Present" 1 "Fail_Present";
VAL_ 616 AEB_Limit_Fail_VIP 0 "Fail_Not_Present" 1 "Fail_Present";
VAL_ 616 AEB_FailSts_VIP 0 "Fail_Not_Present" 1 "Fail_Present";
VAL_ 616 AEB_DispPopupSts_VIP 0 "No_Code" 1 "Pre_Intervention_Warning" 4 "Braking_Complete" 5 "AEB_Unavailble_ESC_Off" 6 "AEB_Unavailble_4WD_Low" 7 "Active_Braking_Enabled" 8 "Active_Braking_Disabled" 9 "AEB_User_Disabled" 10 "AEB_Radar_Blind" 11 "Pre_Intervention_Warning_VRU_L" 12 "AEB_Fail" 13 "Pre_Intervention_Warning_VRU_R" 14 "AEB_Cam_Blind" 15 "Not_used3" 16 "AEB_LIMITED_Fail" 17 "PEB_Off" 18 "PEB_On" 19 "PEB_Radar_Blind" 20 "PEB_Fail" 21 "PEB_Cam_Blind" 22 "FCW_Limited_PEB_Off_Camera_Blinded" 23 "FCW_Limited_PEB_Off_Camera_Fail" 24 "Pre_Intervention_Warning_ICA_L" 25 "Pre_Intervention_Warning_ICA_R" 26 "AEB_Limit_Corner_Blind" 27 "AEB_Unavail_Corsa" 28 "AEB_Unavail_Off_Road" 29 "AEB_Cancel_ESC_Off" 30 "AEB_Cancel_Off_Road" 31 "AEB_Unavail_HDC";
VAL_ 616 AEB_Blind_VIP 0 "Fail_Not_Present" 1 "Fail_Present";
VAL_ 2654486592 CBV_bit4_ActiveWakeupBit_1E384040 0 "PassiveWakeup" 1 "ActiveWakeup";
VAL_ 213 AEB_Type_Brk_D5 0 "NONE" 1 "ACC" 2 "CMS" 3 "CMS_XTD" 4 "ABA" 5 "LSCM" 6 "PEB" 7 "ICA_L" 8 "ICA_R" 9 "HAS_MRM" 10 "RRCC" 15 "SNA";
VAL_ 213 DASEngReqPos_D5 0 "Not_Allowed" 1 "Allowed";
VAL_ 213 LKA_LAT_CTRL_ResponseSts_D5 0 "IDLE" 1 "Permanent_Not_Avail" 2 "Temporarily_Not_Avail" 3 "LKA_Open";
VAL_ 213 RRCC_Cancel_Req_D5 0 "No_request" 1 "Requests temporary off" 2 "Request continuous off" 3 "SNA";
VAL_ 263 EVCU2_THA_Resp 0 "Off" 1 "Active" 3 "SNA";
VAL_ 730 Line_4_Type 0 "None" 1 "Solid" 2 "Dashed" 3 "Double" 4 "Road_edge" 5 "Botts_Dotts" 6 "Barrier";
VAL_ 730 Line_3_Type 0 "None" 1 "Solid" 2 "Dashed" 3 "Double" 4 "Road_edge" 5 "Botts_Dotts" 6 "Barrier";
VAL_ 730 Line_2_Type 0 "None" 1 "Solid" 2 "Dashed" 3 "Double" 4 "Road_edge" 5 "Botts_Dotts" 6 "Barrier";
VAL_ 730 Line_1_Type 0 "None" 1 "Solid" 2 "Dashed" 3 "Double" 4 "Road_edge" 5 "Botts_Dotts" 6 "Barrier";
VAL_ 730 Health_Lane_Detection 0 "Faulted" 1 "Blocked" 2 "Unknown" 3 "Healthy";
VAL_ 730 Health_Front_Object_Detection 0 "Faulted" 1 "Blocked" 2 "Unknown" 3 "Healthy";
VAL_ 730 FOD_Confidence 0 "Not_Detected" 1 "Detected_Low_Confidence" 2 "Detected_Medium_Confidence" 3 "Detected_High_Confidence";
VAL_ 730 Camera_Status 0 "None_Active" 1 "Left_Right_Front" 2 "Left_Right" 3 "Left_Front" 4 "Right_Front" 5 "Front" 6 "Left" 7 "Right";
VAL_ 616 LKA_Status_VIP 0 "OFF" 1 "ON";
VAL_ 616 Lane_DispPopupSts_VIP 0 "No_Code" 1 "LKA_On" 2 "LKA_Off" 3 "LKA_Hands_Off" 4 "HAS_Eyes_Off_Yellow" 5 "Take_Control_Red" 6 "HAS_Ready_Highway" 7 "Blind_Spot_OFF" 8 "HAS_Ready_ACC_Set" 9 "HAS_Unavailable_Speed_to_High" 10 "HAS_Unavailable_Trailer" 11 "HAS_Unavailable_TempNAP" 12 "HAS_Cancel_FOW" 13 "HAS_Cancel_Lane" 15 "HAS_Cancel_Curve" 16 "Unsupport_Lane_Ahead_Take_Control" 17 "MRM_In_Prog" 18 "MRM_Complete" 19 "HAS_Unavail_Lane" 20 "HAS_Hands_Off_Yellow" 21 "HAS_Hands_Off_Red" 22 "HAS_Cancel_Hands_Off" 23 "HAS_AEB_LKA_Cam_Blind" 24 "HAS_AEB_Cam_Blind" 25 "HAS_LKA_Cam_Blind" 26 "HAS_Cam_Blind" 27 "LKA_AEB_Cam_Blind" 28 "LKA_Cam_Blind" 29 "HAS_AEB_Radar_Blind" 30 "HAS_Radar_Blind" 31 "HAS_AEB_LKA_LIMITED_Fail" 32 "HAS_AEB_LIMITED_Fail" 33 "LKA_AEB_LIMITED_Fail" 34 "HAS_AEB_LKA_Fail" 35 "HAS_AEB_Fail" 36 "HAS_LKA_Fail" 37 "HAS_Fail" 38 "LKA_AEB_Fail" 39 "LKA_Fail" 40 "HAS_Cancel" 42 "HAS_ON" 43 "HAS_OFF" 44 "BSS_Blind_ALM_On" 45 "BSS_Blind_ALM_Off" 46 "BSS_OPR_ALM_Off" 47 "BSS_OPR_ALM_On" 48 "BSS_SRV_ALM_Off" 49 "BSS_SRV_ALM_On" 50 "HAS_Unavail_Road_Data" 51 "HAS_Unavail_No_Eyes_On" 52 "HAS_Unavail_Map_OOD" 53 "HAS_Unavail_Locked_Out" 54 "HAS_Cancel_Road_Data" 55 "HAS_Cancel_Driver_Not_Attent" 56 "HAS_Cancel_Brake_Event" 57 "HAS_Cancel_Speed_Too_High" 58 "HAS_Cancel_Control_Limit" 59 "HAS_ACC_Unavailable_4WD_Low" 60 "HAS_ACC_Unavailable_ESC_Off" 61 "HAS_ACC_Unavailable_ESC_Event" 62 "HAS_ACC_Unavailable_Brakes_Cooling" 63 "HAS_ACC_Unavailable_EPB_Active" 64 "HAS_ACC_Unavailable_Shift_D" 65 "HAS_ACC_Unavailable_Door_Open" 66 "HAS_ACC_Unavailable_Seatbelt_Unbuckled" 67 "HAS_ACC_Unavailable_Road_to_Steep" 68 "HAS_ACC_Unavailable_Low_RPM" 69 "HAS_ACC_Unavailable_High_RPM" 70 "HAS_ACC_Cancel" 71 "HAS_ACC_AEB_Cancel_ESC_Off" 72 "HAS_ACC_Cancel_ESC_Off" 73 "HAS_ACC_Cancel_ESC_Event" 74 "HAS_ACC_Cancel_Brakes_Cooling" 75 "HAS_ACC_Cancel_EPB_Active" 76 "HAS_ACC_Cancel_Shift_D" 77 "HAS_ACC_Cancel_Door_Open" 78 "HAS_ACC_Cancel_Seatbelt_Unbuckled" 79 "HAS_ACC_Cancel_Road_to_Steep" 80 "HAS_ACC_Cancel_Low_RPM" 81 "HAS_ACC_Cancel_High_RPM" 82 "HAS_ACC_Stop_Vehicle_Object_Detected" 83 "HAS_ACC_User_Enabled" 84 "HAS_ACC_Set" 85 "LKA_Off_Check" 86 "HAS_Curve_Too_Tight" 87 "HAS_Lane_Split" 88 "HAS_On_Reminder" 89 "HAS_ACC_Unavail_Corsa" 90 "LKA_Unavail_Corsa" 91 "HAS_ACC_Unavailable_Off_Road" 92 "BSS_Unavail_Corsa" 93 "BSS_Trailer_On" 94 "BSS_Trailer_Max" 95 "ADAS_Unavailable_Snow_Plow_Detected" 96 "HF_ADA_Set" 97 "Ready_No_Road_HF" 98 "Adjust_Seat_State_2" 99 "Drowsy_State_2" 100 "HF_To_HO_Generic" 101 "HF_To_HO_Hwy_Ending" 102 "HF_Cancel_Not_Attentive" 103 "DA_Set_HF_Service" 104 "Stay_In_Lane" 105 "ALM_Unavail_ESC_Off" 106 "ALM_Off_ESC_Off" 107 "HAS_ACC_Unavail_HDC" 108 "HAS_ACC_AEB_Cancel_Off_Road" 109 "HAS_ACC_Cancel_Off_Road" 110 "HAS_Only_Fail" 111 "HAS_Only_ALM_Fail" 112 "MRM_Complete_Shift_P" 113 "HAS_Eyes_Off_Red";
VAL_ 616 Lane_DisplaySts_Right_LKA_VIP 0 "Off" 1 "Gray" 2 "Green" 3 "Yellow" 4 "Yellow_Flashing" 5 "Red" 6 "Dashed" 7 "White";
VAL_ 616 Lane_DisplaySts_Left_VIP 0 "Off" 1 "Gray" 2 "Green" 3 "Yellow" 4 "Yellow_Flashing" 5 "Red" 6 "Dashed" 7 "White";
VAL_ 616 DisplaySts_Veh_LKA_VIP 0 "Off" 1 "Center_White" 2 "Center_Green" 3 "Right_Crossing_1" 4 "Left_Crossing_1" 5 "Right_Crossing_2" 6 "Left_Crossing_2";
VAL_ 265 StbmSyncState_BSM_TMSMP 0 "IN_SYNC" 1 "NOT_IN_SYNC" 255 "INVALID";
VAL_ 265 RHRWheelSpeed_TMSMP 8191 "SNA";
VAL_ 265 RHR_WheelSensorFailSts_TMSMP 0 "Fail_Not_Present" 1 "Fail_Present";
VAL_ 265 RHR_Spin_TMSMP 0 "Stand_Still" 1 "Forward" 2 "Backward" 3 "SNA";
VAL_ 265 RHR_FastPulseCounter_TMSMP 255 "SNA";
VAL_ 265 RHFWheelSpeed_TMSMP 8191 "SNA";
VAL_ 265 RHF_WheelSensorFailSts_TMSMP 0 "Fail_Not_Present" 1 "Fail_Present";
VAL_ 265 RHF_Spin_TMSMP 0 "Stand_Still" 1 "Forward" 2 "Backward" 3 "SNA";
VAL_ 265 RHF_FastPulseCounter_TMSMP 255 "SNA";
VAL_ 265 LHRWheelSpeed_TMSMP 8191 "SNA";
VAL_ 265 LHR_WheelSensorFailSts_TMSMP 0 "Fail_Not_Present" 1 "Fail_Present";
VAL_ 265 LHR_Spin_TMSMP 0 "Stand_Still" 1 "Forward" 2 "Backward" 3 "SNA";
VAL_ 265 LHR_FastPulseCounter_TMSMP 255 "SNA";
VAL_ 265 LHFWheelSpeed_TMSMP 8191 "SNA";
VAL_ 265 LHF_WheelSensorFailSts_TMSMP 0 "Fail_Not_Present" 1 "Fail_Present";
VAL_ 265 LHF_Spin_TMSMP 0 "Stand_Still" 1 "Forward" 2 "Backward" 3 "SNA";
VAL_ 265 LHF_FastPulseCounter_TMSMP 255 "SNA";
VAL_ 263 EVCU2_TRSC_Resp 0 "OFF" 1 "ACTIVE" 3 "SNA";
VAL_ 263 Propulsion_ADAS_Inhibit 0 "Faulted" 1 "Available";
VAL_ 616 DM_Camera_Block_VIP 0 "Fail_Not_Present" 1 "Fail_Present";
VAL_ 299 ACC_TORSts 0 "TOR_Active" 1 "TOR_Not_Active";
VAL_ 616 RRCC_DispPopupSts_VIP 0 "No_Code";
VAL_ 616 ACC_Set_Speed_Strike_VIP 0 "Not_Present" 1 "Present";
SIG_GROUP_ 299 ADAS_FD_INFO3_Pkt 1 : ACC_Axle_Torque ACC_Axle_Torque_Enabled MessageCounter_ADAS_FD_INFO3 CRC_ADAS_FD_INFO3 ACC_TORSts;
SIG_GROUP_ 263 PT_SYSTEM_FD_1_Pkt 1 : PowertrainPrplsnActv_PT GearEngagedForDisplay_PT GearEngaged_PT DriveReady_PT TargetGear_PT SpeedLimitSts_PT ShiftLeverPosition_PT PdlPosActual_PT MessageCounter_PT_SYSTEM_FD_1 ISASts_PT GasPedalPositionFailSts_PT GasPedalPosition_PT CRC_PT_SYSTEM_FD_1 RawPVS2_PT RawPVS1_PT EVCU2_THA_Resp EVCU2_TRSC_Resp Propulsion_ADAS_Inhibit;
